VERSION ""

NS_ :

BS_:

BU_: DSAU vHS_M SHVU_RR DPSS AMP ICC RLPSM APSM RWPC RRHV RRPSM CGW_CCU APSS ATS RLHV FPM RDC PSM ASAU

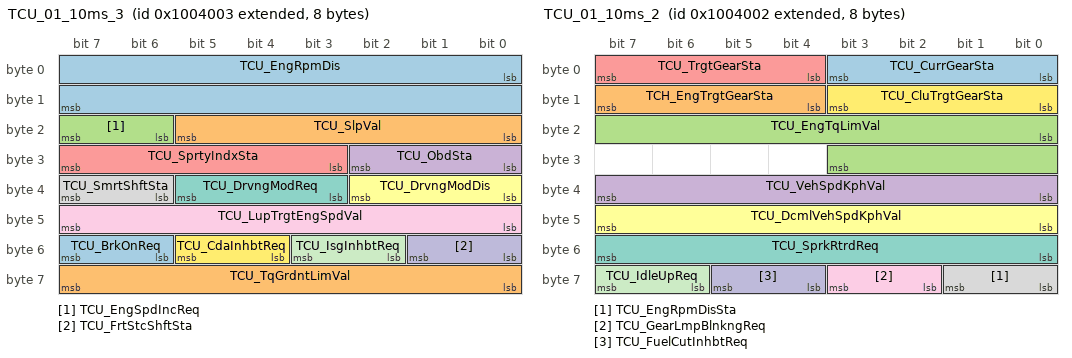
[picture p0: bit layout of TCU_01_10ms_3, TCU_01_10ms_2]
BO_ 2164277251 TCU_01_10ms_3: 8 CGW_CCU
 SG_ TCU_EngRpmDis : 0|16@1+ (0.25,0) [0|0] "rpm"  Vector__XXX
 SG_ TCU_SlpVal : 16|6@1+ (0.5,-16) [0|0] "%"  Vector__XXX
 SG_ TCU_EngSpdIncReq : 22|2@1+ (1,0) [0|0] ""  Vector__XXX
 SG_ TCU_ObdSta : 24|3@1+ (1,0) [0|0] ""  Vector__XXX
 SG_ TCU_SprtyIndxSta : 27|5@1+ (1,0) [0|0] ""  Vector__XXX
 SG_ TCU_DrvngModDis : 32|3@1+ (1,0) [0|0] ""  Vector__XXX
 SG_ TCU_DrvngModReq : 35|3@1+ (1,0) [0|0] ""  Vector__XXX
 SG_ TCU_SmrtShftSta : 38|2@1+ (1,0) [0|0] ""  Vector__XXX
 SG_ TCU_LupTrgtEngSpdVal : 40|8@1+ (10,500) [0|0] "rpm"  Vector__XXX
 SG_ TCU_FrtStcShftSta : 48|2@1+ (1,0) [0|0] ""  Vector__XXX
 SG_ TCU_IsgInhbtReq : 50|2@1+ (1,0) [0|0] ""  Vector__XXX
 SG_ TCU_CdaInhbtReq : 52|2@1+ (1,0) [0|0] ""  Vector__XXX
 SG_ TCU_BrkOnReq : 54|2@1+ (1,0) [0|0] ""  Vector__XXX
 SG_ TCU_TqGrdntLimVal : 56|8@1+ (10,0) [0|0] "Nm/s"  Vector__XXX

BO_ 2164277250 TCU_01_10ms_2: 8 CGW_CCU
 SG_ TCU_CurrGearSta : 0|4@1+ (1,0) [0|0] ""  AMP
 SG_ TCH_EngTrgtGearSta : 12|4@1+ (1,0) [0|0] ""  Vector__XXX
 SG_ TCU_EngTqLimVal : 16|12@1- (1,0) [0|0] "Nm"  Vector__XXX
 SG_ TCU_VehSpdKphVal : 32|8@1+ (1,0) [0|0] "km/h"  Vector__XXX
 SG_ TCU_TrgtGearSta : 4|4@1+ (1,0) [0|0] ""  AMP
 SG_ TCU_DcmlVehSpdKphVal : 40|8@1+ (0.0078125,0) [0|0] "km/h"  Vector__XXX
 SG_ TCU_SprkRtrdReq : 48|8@1+ (0.375,-23.625) [0|0] "˚"  Vector__XXX
 SG_ TCU_EngRpmDisSta : 56|2@1+ (1,0) [0|0] ""  Vector__XXX
 SG_ TCU_GearLmpBlnkngReq : 58|2@1+ (1,0) [0|0] ""  Vector__XXX
 SG_ TCU_FuelCutInhbtReq : 60|2@1+ (1,0) [0|0] ""  Vector__XXX
 SG_ TCU_IdleUpReq : 62|2@1+ (1,0) [0|0] ""  Vector__XXX
 SG_ TCU_CluTrgtGearSta : 8|4@1+ (1,0) [0|0] ""  Vector__XXX

BO_ 799 SBCM_DRV_01_200ms: 8 CGW_CCU
 SG_ SBCM_DRV_Crc1Val : 0|8@1+ (1,0) [0|0] ""  Vector__XXX
 SG_ DRV_CrashUnlockCmd : 10|1@1+ (1,0) [0|0] ""  Vector__XXX
 SG_ C_ApprOpenStatus : 11|1@1+ (1,0) [0|0] ""  Vector__XXX
 SG_ SBCM_DRV_AlvCnt1Val : 12|4@1+ (1,0) [0|0] ""  Vector__XXX
 SG_ Warn_DrvDrSwSta_SBCM : 20|2@1+ (1,0) [0|0] ""  RWPC,PSM,AMP,ATS,ICC
 SG_ DoorLock_DrvDrUnLkSta_SBCM : 22|2@1+ (1,0) [0|0] ""  ATS
 SG_ DRV_SEAWarn_LH : 24|2@1+ (1,0) [0|0] ""  AMP
 SG_ DRV_SEAWarn_RH : 26|2@1+ (1,0) [0|0] ""  AMP
 SG_ DRV_SEWWarn_LH : 28|2@1+ (1,0) [0|0] ""  AMP
 SG_ DRV_SEWWarn_RH : 30|2@1+ (1,0) [0|0] ""  AMP
 SG_ DRV_MRActivationAlarm : 32|2@1+ (1,0) [0|0] ""  Vector__XXX
 SG_ DRV_ReleaseWarn : 34|2@1+ (1,0) [0|0] ""  Vector__XXX
 SG_ Latch_TypeOption_DRV : 36|2@1+ (1,0) [0|0] ""  Vector__XXX
 SG_ DRV_SWFailAlarm : 38|2@1+ (1,0) [0|0] ""  Vector__XXX
 SG_ USM_PwrDRCloseByRKELockSta : 44|2@1+ (1,0) [0|0] ""  Vector__XXX
 SG_ USM_PwrDRCloseByRKELockOpt : 46|2@1+ (1,0) [0|0] ""  Vector__XXX
 SG_ USM_PwrDRCloseByBrakeSta : 48|2@1+ (1,0) [0|0] ""  Vector__XXX
 SG_ USM_PwrDRCloseByBrakeOpt : 50|2@1+ (1,0) [0|0] ""  Vector__XXX
 SG_ USM_PwrDRBuzzerSta : 52|2@1+ (1,0) [0|0] ""  Vector__XXX
 SG_ USM_PwrDRBuzzerOpt : 54|2@1+ (1,0) [0|0] ""  Vector__XXX
 SG_ PDS_TypeOption_DRV : 56|2@1+ (1,0) [0|0] ""  Vector__XXX
 SG_ C_DrvDoorApproachOpen : 58|2@1+ (1,0) [0|0] ""  Vector__XXX
 SG_ C_DrvDoorApproachClose : 60|2@1+ (1,0) [0|0] ""  Vector__XXX
 SG_ DoorLock_PDSLkSwSta_DRV : 62|2@1+ (1,0) [0|0] ""  AMP
 SG_ DRVDoorPushAlarm : 8|2@1+ (1,0) [0|0] ""  Vector__XXX

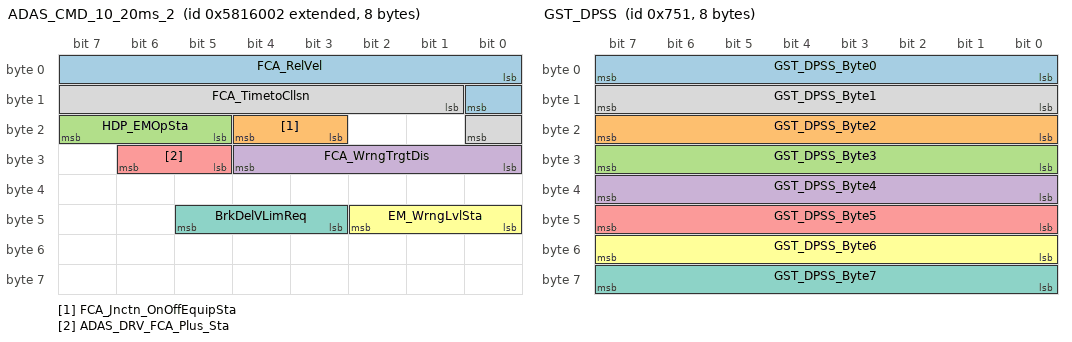
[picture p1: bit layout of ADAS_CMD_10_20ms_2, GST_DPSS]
BO_ 2239848450 ADAS_CMD_10_20ms_2: 8 CGW_CCU
 SG_ FCA_RelVel : 0|9@1+ (0.1,-25.5) [0|0] "m/s"  Vector__XXX
 SG_ FCA_Jnctn_OnOffEquipSta : 19|2@1+ (1,0) [0|0] ""  Vector__XXX
 SG_ HDP_EMOpSta : 21|3@1+ (1,0) [0|0] ""  Vector__XXX
 SG_ FCA_WrngTrgtDis : 24|5@1+ (1,0) [0|0] ""  Vector__XXX
 SG_ ADAS_DRV_FCA_Plus_Sta : 29|2@1+ (1,0) [0|0] ""  Vector__XXX
 SG_ EM_WrngLvlSta : 40|3@1+ (1,0) [0|0] ""  Vector__XXX
 SG_ BrkDelVLimReq : 43|3@1+ (1,0) [0|0] ""  Vector__XXX
 SG_ FCA_TimetoCllsn : 9|8@1+ (10,0) [0|0] "ms"  Vector__XXX

BO_ 1873 GST_DPSS: 8 CGW_CCU
 SG_ GST_DPSS_Byte0 : 0|8@1+ (1,0) [0|0] ""  DPSS,vHS_M
 SG_ GST_DPSS_Byte2 : 16|8@1+ (1,0) [0|0] ""  DPSS,vHS_M
 SG_ GST_DPSS_Byte3 : 24|8@1+ (1,0) [0|0] ""  DPSS,vHS_M
 SG_ GST_DPSS_Byte4 : 32|8@1+ (1,0) [0|0] ""  DPSS,vHS_M
 SG_ GST_DPSS_Byte5 : 40|8@1+ (1,0) [0|0] ""  DPSS,vHS_M
 SG_ GST_DPSS_Byte6 : 48|8@1+ (1,0) [0|0] ""  DPSS,vHS_M
 SG_ GST_DPSS_Byte7 : 56|8@1+ (1,0) [0|0] ""  DPSS,vHS_M
 SG_ GST_DPSS_Byte1 : 8|8@1+ (1,0) [0|0] ""  DPSS,vHS_M

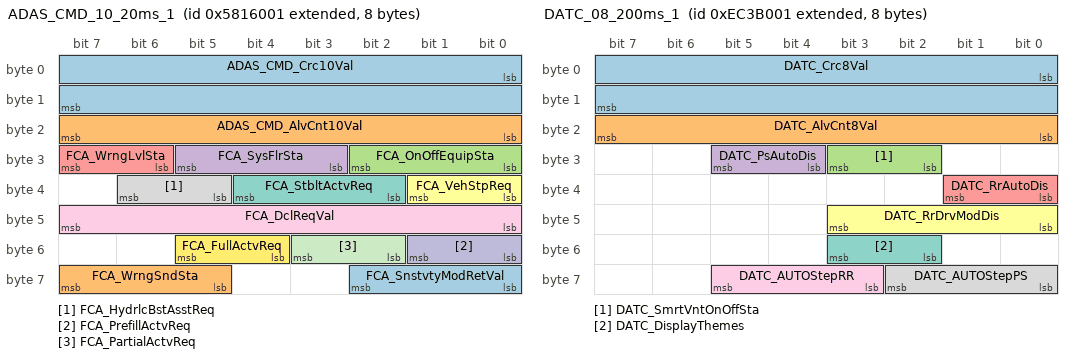
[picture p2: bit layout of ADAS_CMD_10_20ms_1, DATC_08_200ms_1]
BO_ 2239848449 ADAS_CMD_10_20ms_1: 8 CGW_CCU
 SG_ ADAS_CMD_Crc10Val : 0|16@1+ (1,0) [0|0] ""  Vector__XXX
 SG_ ADAS_CMD_AlvCnt10Val : 16|8@1+ (1,0) [0|0] ""  Vector__XXX
 SG_ FCA_OnOffEquipSta : 24|3@1+ (1,0) [0|0] ""  Vector__XXX
 SG_ FCA_SysFlrSta : 27|3@1+ (1,0) [0|0] ""  Vector__XXX
 SG_ FCA_WrngLvlSta : 30|2@1+ (1,0) [0|0] ""  APSM,RLPSM,RRPSM
 SG_ FCA_VehStpReq : 32|2@1+ (1,0) [0|0] ""  Vector__XXX
 SG_ FCA_StbltActvReq : 34|3@1+ (1,0) [0|0] ""  Vector__XXX
 SG_ FCA_HydrlcBstAsstReq : 37|2@1+ (1,0) [0|0] ""  Vector__XXX
 SG_ FCA_DclReqVal : 40|8@1+ (0.01,0) [0|0] "g"  Vector__XXX
 SG_ FCA_PrefillActvReq : 48|2@1+ (1,0) [0|0] ""  Vector__XXX
 SG_ FCA_PartialActvReq : 50|2@1+ (1,0) [0|0] ""  Vector__XXX
 SG_ FCA_FullActvReq : 52|2@1+ (1,0) [0|0] ""  APSM,RLPSM,RRPSM
 SG_ FCA_SnstvtyModRetVal : 56|3@1+ (1,0) [0|0] ""  Vector__XXX
 SG_ FCA_WrngSndSta : 61|3@1+ (1,0) [0|0] ""  AMP

BO_ 2458166529 HU_APSU_PE_00_1: 8 CGW_CCU
 SG_ C_RLUnFldSw_HU : 0|2@1+ (1,0) [0|0] ""  Vector__XXX
 SG_ C_RLTiltUpSw_HU : 10|2@1+ (1,0) [0|0] ""  RLPSM
 SG_ C_RRTiltDownSw_HU : 12|2@1+ (1,0) [0|0] ""  RRPSM
 SG_ C_RRTiltUpSw_HU : 14|2@1+ (1,0) [0|0] ""  RRPSM
 SG_ C_RLRclBwdSw_HU : 16|2@1+ (1,0) [0|0] ""  RLPSM
 SG_ C_RLRclFwdSw_HU : 18|2@1+ (1,0) [0|0] ""  RLPSM
 SG_ C_RLFldSw_HU : 2|2@1+ (1,0) [0|0] ""  Vector__XXX
 SG_ C_RRRclBwdSw_HU : 20|2@1+ (1,0) [0|0] ""  RRPSM
 SG_ C_RRRclFwdSw_HU : 22|2@1+ (1,0) [0|0] ""  RRPSM
 SG_ C_TLHrestFldSw_HU : 24|2@1+ (1,0) [0|0] ""  Vector__XXX
 SG_ C_TRHrestFldSw_HU : 26|2@1+ (1,0) [0|0] ""  Vector__XXX
 SG_ C_RLRlxSW_HU : 28|2@1+ (1,0) [0|0] ""  RLPSM
 SG_ C_RRRlxSW_HU : 30|2@1+ (1,0) [0|0] ""  RRPSM
 SG_ C_RRUnWalkInSw_HU : 32|2@1+ (1,0) [0|0] ""  Vector__XXX
 SG_ C_RRWalkInSw_HU : 34|2@1+ (1,0) [0|0] ""  Vector__XXX
 SG_ C_TLFldSw_HU : 36|2@1+ (1,0) [0|0] ""  Vector__XXX
 SG_ C_TRFldSw_HU : 38|2@1+ (1,0) [0|0] ""  Vector__XXX
 SG_ C_RRUnFldSw_HU : 4|2@1+ (1,0) [0|0] ""  Vector__XXX
 SG_ C_RLUnWalkInSw_HU : 44|2@1+ (1,0) [0|0] ""  Vector__XXX
 SG_ C_RLWalkInSw_HU : 46|2@1+ (1,0) [0|0] ""  Vector__XXX
 SG_ C_TRRclBwdSw_HU : 48|2@1+ (1,0) [0|0] ""  Vector__XXX
 SG_ C_TRRclFwdSw_HU : 50|2@1+ (1,0) [0|0] ""  Vector__XXX
 SG_ C_RRFldSw_HU : 6|2@1+ (1,0) [0|0] ""  Vector__XXX
 SG_ C_TLRclBwdSw_HU : 60|2@1+ (1,0) [0|0] ""  Vector__XXX
 SG_ C_TLRclFwdSw_HU : 62|2@1+ (1,0) [0|0] ""  Vector__XXX
 SG_ C_RLTiltDownSw_HU : 8|2@1+ (1,0) [0|0] ""  RLPSM

BO_ 319 FPM_01_00ms: 8 FPM
 SG_ FPM_Random : 16|48@1+ (1,0) [0|0] ""  CGW_CCU

BO_ 2395189249 DATC_08_200ms_1: 8 CGW_CCU
 SG_ DATC_Crc8Val : 0|16@1+ (1,0) [0|0] ""  Vector__XXX
 SG_ DATC_AlvCnt8Val : 16|8@1+ (1,0) [0|0] ""  Vector__XXX
 SG_ DATC_SmrtVntOnOffSta : 26|2@1+ (1,0) [0|0] ""  Vector__XXX
 SG_ DATC_PsAutoDis : 28|2@1+ (1,0) [0|0] ""  ATS
 SG_ DATC_RrAutoDis : 32|2@1+ (1,0) [0|0] ""  ATS
 SG_ DATC_RrDrvModDis : 40|4@1+ (1,0) [0|0] ""  ATS
 SG_ DATC_DisplayThemes : 50|2@1+ (1,0) [0|0] ""  Vector__XXX
 SG_ DATC_AUTOStepPS : 56|3@1+ (1,0) [0|0] ""  Vector__XXX
 SG_ DATC_AUTOStepRR : 59|3@1+ (1,0) [0|0] ""  Vector__XXX

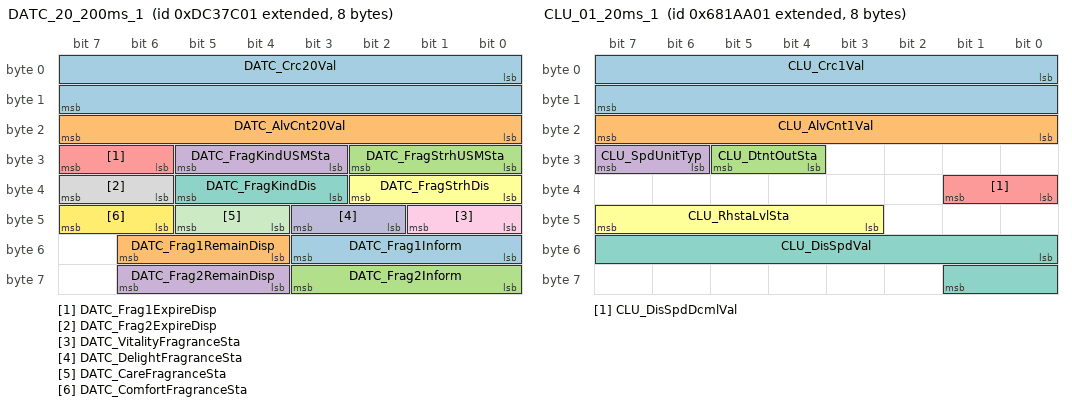
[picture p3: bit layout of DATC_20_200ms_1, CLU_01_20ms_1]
BO_ 2378398721 DATC_20_200ms_1: 8 CGW_CCU
 SG_ DATC_Crc20Val : 0|16@1+ (1,0) [0|0] ""  Vector__XXX
 SG_ DATC_AlvCnt20Val : 16|8@1+ (1,0) [0|0] ""  Vector__XXX
 SG_ DATC_FragStrhUSMSta : 24|3@1+ (1,0) [0|0] ""  ATS
 SG_ DATC_FragKindUSMSta : 27|3@1+ (1,0) [0|0] ""  ATS
 SG_ DATC_Frag1ExpireDisp : 30|2@1+ (1,0) [0|0] ""  ATS
 SG_ DATC_FragStrhDis : 32|3@1+ (1,0) [0|0] ""  ATS
 SG_ DATC_FragKindDis : 35|3@1+ (1,0) [0|0] ""  ATS
 SG_ DATC_Frag2ExpireDisp : 38|2@1+ (1,0) [0|0] ""  ATS
 SG_ DATC_VitalityFragranceSta : 40|2@1+ (1,0) [0|0] ""  Vector__XXX
 SG_ DATC_DelightFragranceSta : 42|2@1+ (1,0) [0|0] ""  Vector__XXX
 SG_ DATC_CareFragranceSta : 44|2@1+ (1,0) [0|0] ""  Vector__XXX
 SG_ DATC_ComfortFragranceSta : 46|2@1+ (1,0) [0|0] ""  Vector__XXX
 SG_ DATC_Frag1Inform : 48|4@1+ (1,0) [0|0] ""  ATS
 SG_ DATC_Frag1RemainDisp : 52|3@1+ (1,0) [0|0] ""  ATS
 SG_ DATC_Frag2Inform : 56|4@1+ (1,0) [0|0] ""  ATS
 SG_ DATC_Frag2RemainDisp : 60|3@1+ (1,0) [0|0] ""  ATS

BO_ 2466562561 HU_USM_E_08_1: 8 CGW_CCU
 SG_ C_RH_Unfolding_SW : 0|2@1+ (1,0) [0|0] ""  Vector__XXX
 SG_ C_PSMHeightNValueSet : 10|3@1+ (1,0) [0|0] ""  Vector__XXX
 SG_ C_AVN_PTGHeightNValueSet : 13|3@1+ (1,0) [0|0] ""  Vector__XXX
 SG_ CF_AVN_SCCMLReset : 16|2@1+ (1,0) [0|0] ""  Vector__XXX
 SG_ C_TgltAwayCloseNValue : 18|2@1+ (1,0) [0|0] ""  Vector__XXX
 SG_ C_RH_Folding_SW : 2|2@1+ (1,0) [0|0] ""  Vector__XXX
 SG_ C_HAnBNValueSet : 20|2@1+ (1,0) [0|0] ""  Vector__XXX
 SG_ CF_AVN_RrSeatRemindNValueSet : 22|2@1+ (1,0) [0|0] ""  Vector__XXX
 SG_ CF_AVN_DSWNValueSet : 24|2@1+ (1,0) [0|0] ""  DSAU,ICC
 SG_ CF_AVN_RRPSU_RLNValueSet : 26|3@1+ (1,0) [0|0] ""  RLPSM
 SG_ CF_AVN_APSUNValueSet : 29|3@1+ (1,0) [0|0] ""  APSM,APSS,ASAU
 SG_ CF_AVN_NCC_CameraNValueSet : 32|3@1+ (1,0) [0|0] ""  Vector__XXX
 SG_ CF_AVN_FCAJnctnNValueSet : 35|2@1+ (1,0) [0|0] ""  Vector__XXX
 SG_ CF_AVN_RRPSU_RRNValueSet : 37|3@1+ (1,0) [0|0] ""  RRPSM
 SG_ C_LH_Unfolding_SW : 4|2@1+ (1,0) [0|0] ""  Vector__XXX
 SG_ CF_AVN_HtBlcAstNValueSet : 40|4@1+ (1,0) [0|0] ""  PSM,APSM
 SG_ CF_AVN_HtBlcDrvNValueSet : 44|4@1+ (1,0) [0|0] ""  PSM,APSM
 SG_ CF_AVN_SCCModeNValueSet : 48|2@1+ (1,0) [0|0] ""  Vector__XXX
 SG_ CF_AVN_SCCMLChar1Set : 50|3@1+ (1,0) [0|0] ""  Vector__XXX
 SG_ CF_AVN_UIPNValueSet : 54|2@1+ (1,0) [0|0] ""  Vector__XXX
 SG_ CF_AVN_SCCMLChar2Set : 56|3@1+ (1,0) [0|0] ""  Vector__XXX
 SG_ CF_AVN_SCCMLChar3Set : 59|3@1+ (1,0) [0|0] ""  Vector__XXX
 SG_ C_LH_Folding_SW : 6|2@1+ (1,0) [0|0] ""  Vector__XXX
 SG_ CF_AVN_NmodeFCAoffNValue : 62|2@1+ (1,0) [0|0] ""  Vector__XXX
 SG_ CF_AVN_HDALCFuncNValueSet : 8|2@1+ (1,0) [0|0] ""  Vector__XXX

BO_ 2256644609 CLU_01_20ms_1: 8 CGW_CCU
 SG_ CLU_Crc1Val : 0|16@1+ (1,0) [0|0] ""  PSM,RRPSM,SHVU_RR,DPSS,ATS
 SG_ CLU_AlvCnt1Val : 16|8@1+ (1,0) [0|0] ""  PSM,RRPSM,SHVU_RR,DPSS,ATS
 SG_ CLU_DtntOutSta : 28|2@1+ (1,0) [0|0] ""  RLPSM,DPSS,FPM,ATS,DSAU,ASAU
 SG_ CLU_SpdUnitTyp : 30|2@1+ (1,0) [0|0] ""  PSM,ICC
 SG_ CLU_DisSpdDcmlVal : 32|2@1+ (0.125,0) [0|0] ""  PSM
 SG_ CLU_RhstaLvlSta : 43|5@1+ (1,0) [0|0] ""  PSM,RLPSM,DPSS,FPM,ATS,DSAU,ASAU
 SG_ CLU_DisSpdVal : 48|10@1+ (0.5,0) [0|0] "km/h or MPH"  PSM,ICC

BO_ 2315419905 HU_FPM_E_01_1: 8 CGW_CCU
 SG_ AVN_Encrypted_Result1 : 0|64@1+ (1,0) [0|0] ""  FPM

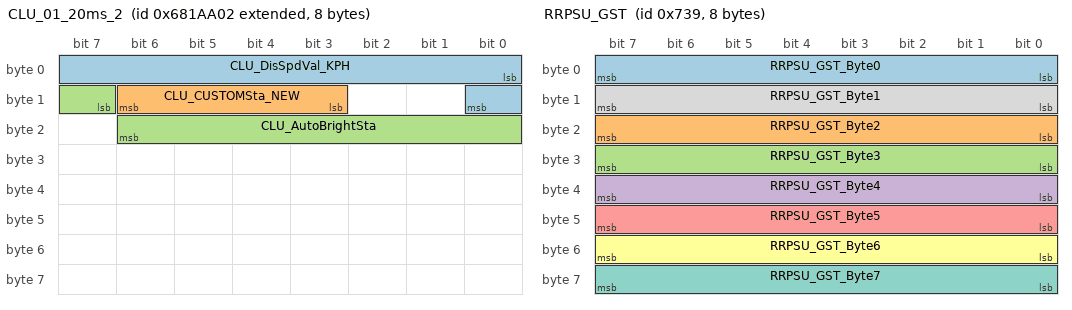
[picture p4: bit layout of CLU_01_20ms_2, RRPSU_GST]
BO_ 2256644610 CLU_01_20ms_2: 8 CGW_CCU
 SG_ CLU_DisSpdVal_KPH : 0|9@1+ (1,0) [0|0] "km/h"  RWPC,PSM,APSM,RLPSM,RRPSM,RLHV,RRHV,SHVU_RR,DPSS,ATS,DSAU,ASAU
 SG_ CLU_CUSTOMSta_NEW : 11|4@1+ (1,0) [0|0] ""  Vector__XXX
 SG_ CLU_AutoBrightSta : 15|8@1+ (1,0) [0|0] ""  Vector__XXX

BO_ 1849 RRPSU_GST: 8 RRPSM
 SG_ RRPSU_GST_Byte0 : 0|8@1+ (1,0) [0|0] ""  CGW_CCU
 SG_ RRPSU_GST_Byte2 : 16|8@1+ (1,0) [0|0] ""  CGW_CCU
 SG_ RRPSU_GST_Byte3 : 24|8@1+ (1,0) [0|0] ""  CGW_CCU
 SG_ RRPSU_GST_Byte4 : 32|8@1+ (1,0) [0|0] ""  CGW_CCU
 SG_ RRPSU_GST_Byte5 : 40|8@1+ (1,0) [0|0] ""  CGW_CCU
 SG_ RRPSU_GST_Byte6 : 48|8@1+ (1,0) [0|0] ""  CGW_CCU
 SG_ RRPSU_GST_Byte7 : 56|8@1+ (1,0) [0|0] ""  CGW_CCU
 SG_ RRPSU_GST_Byte1 : 8|8@1+ (1,0) [0|0] ""  CGW_CCU

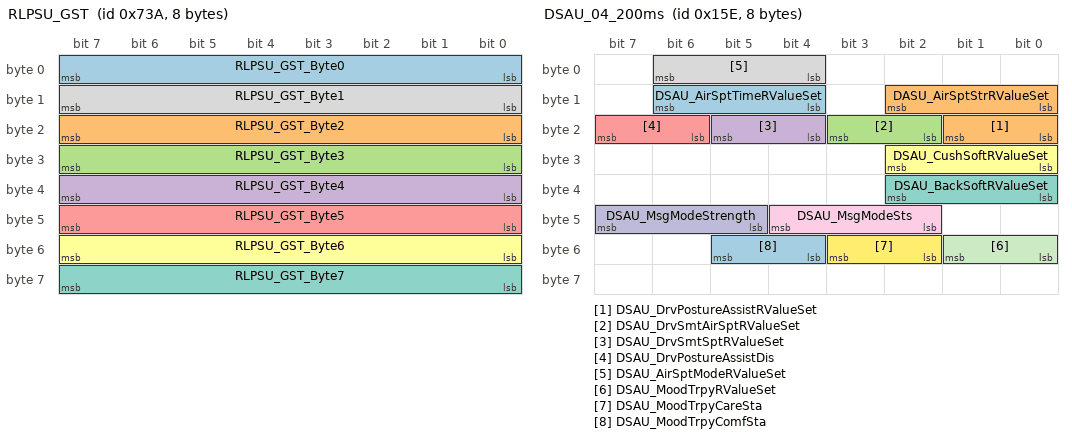
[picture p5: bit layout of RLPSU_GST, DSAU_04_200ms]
BO_ 1850 RLPSU_GST: 8 RLPSM
 SG_ RLPSU_GST_Byte0 : 0|8@1+ (1,0) [0|0] ""  CGW_CCU
 SG_ RLPSU_GST_Byte2 : 16|8@1+ (1,0) [0|0] ""  CGW_CCU
 SG_ RLPSU_GST_Byte3 : 24|8@1+ (1,0) [0|0] ""  CGW_CCU
 SG_ RLPSU_GST_Byte4 : 32|8@1+ (1,0) [0|0] ""  CGW_CCU
 SG_ RLPSU_GST_Byte5 : 40|8@1+ (1,0) [0|0] ""  CGW_CCU
 SG_ RLPSU_GST_Byte6 : 48|8@1+ (1,0) [0|0] ""  CGW_CCU
 SG_ RLPSU_GST_Byte7 : 56|8@1+ (1,0) [0|0] ""  CGW_CCU
 SG_ RLPSU_GST_Byte1 : 8|8@1+ (1,0) [0|0] ""  CGW_CCU

BO_ 351 FPM_03_00ms: 8 FPM
 SG_ FPM_Encrypted_Result2 : 0|64@1+ (1,0) [0|0] ""  CGW_CCU

BO_ 350 DSAU_04_200ms: 8 DSAU
 SG_ DSAU_AirSptTimeRValueSet : 12|3@1+ (1,0) [0|0] ""  CGW_CCU
 SG_ DSAU_DrvPostureAssistRValueSet : 16|2@1+ (1,0) [0|0] ""  CGW_CCU
 SG_ DSAU_DrvSmtAirSptRValueSet : 18|2@1+ (1,0) [0|0] ""  CGW_CCU
 SG_ DSAU_DrvSmtSptRValueSet : 20|2@1+ (1,0) [0|0] ""  CGW_CCU
 SG_ DSAU_DrvPostureAssistDis : 22|2@1+ (1,0) [0|0] ""  CGW_CCU
 SG_ DSAU_CushSoftRValueSet : 24|3@1+ (1,0) [0|0] ""  CGW_CCU
 SG_ DSAU_BackSoftRValueSet : 32|3@1+ (1,0) [0|0] ""  CGW_CCU
 SG_ DSAU_AirSptModeRValueSet : 4|3@1+ (1,0) [0|0] ""  CGW_CCU
 SG_ DSAU_MsgModeSts : 42|3@1+ (1,0) [0|0] ""  CGW_CCU
 SG_ DSAU_MsgModeStrength : 45|3@1+ (1,0) [0|0] ""  CGW_CCU
 SG_ DSAU_MoodTrpyRValueSet : 48|2@1+ (1,0) [0|0] ""  CGW_CCU
 SG_ DSAU_MoodTrpyCareSta : 50|2@1+ (1,0) [0|0] ""  CGW_CCU
 SG_ DSAU_MoodTrpyComfSta : 52|2@1+ (1,0) [0|0] ""  CGW_CCU
 SG_ DASU_AirSptStrRValueSet : 8|3@1+ (1,0) [0|0] ""  CGW_CCU

BO_ 349 DSAU_03_200ms: 8 DSAU
 SG_ DSAU_CushInfDis : 0|2@1+ (1,0) [0|0] ""  DPSS,CGW_CCU
 SG_ DSAU_CushDefDis : 2|2@1+ (1,0) [0|0] ""  DPSS,CGW_CCU

BO_ 348 DSAU_02_200ms: 8 DSAU
 SG_ DSAU_BolsterInfDis : 0|2@1+ (1,0) [0|0] ""  DPSS,CGW_CCU
 SG_ DSAU_BolsterDefDis : 2|2@1+ (1,0) [0|0] ""  DPSS,CGW_CCU

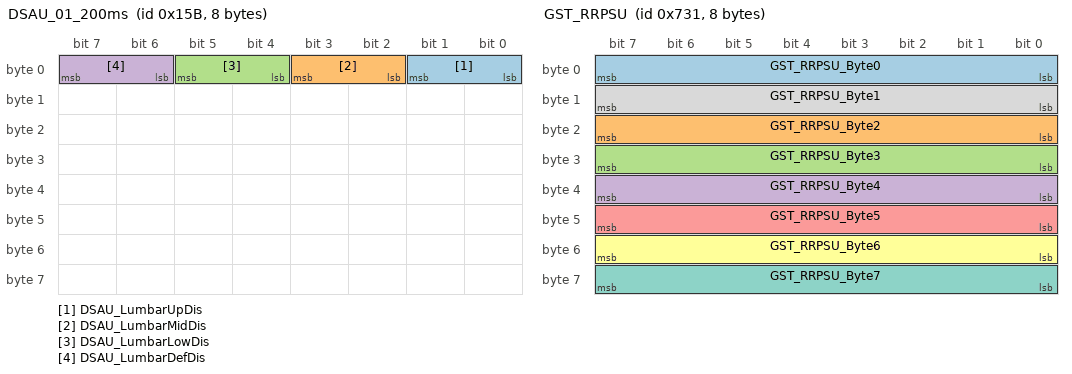
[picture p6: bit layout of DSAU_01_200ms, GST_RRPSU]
BO_ 347 DSAU_01_200ms: 8 DSAU
 SG_ DSAU_LumbarUpDis : 0|2@1+ (1,0) [0|0] ""  DPSS,CGW_CCU
 SG_ DSAU_LumbarMidDis : 2|2@1+ (1,0) [0|0] ""  DPSS,CGW_CCU
 SG_ DSAU_LumbarLowDis : 4|2@1+ (1,0) [0|0] ""  DPSS,CGW_CCU
 SG_ DSAU_LumbarDefDis : 6|2@1+ (1,0) [0|0] ""  DPSS,CGW_CCU

BO_ 1841 GST_RRPSU: 8 CGW_CCU
 SG_ GST_RRPSU_Byte0 : 0|8@1+ (1,0) [0|0] ""  RRPSM,vHS_M
 SG_ GST_RRPSU_Byte2 : 16|8@1+ (1,0) [0|0] ""  RRPSM,vHS_M
 SG_ GST_RRPSU_Byte3 : 24|8@1+ (1,0) [0|0] ""  RRPSM,vHS_M
 SG_ GST_RRPSU_Byte4 : 32|8@1+ (1,0) [0|0] ""  RRPSM,vHS_M
 SG_ GST_RRPSU_Byte5 : 40|8@1+ (1,0) [0|0] ""  RRPSM,vHS_M
 SG_ GST_RRPSU_Byte6 : 48|8@1+ (1,0) [0|0] ""  RRPSM,vHS_M
 SG_ GST_RRPSU_Byte7 : 56|8@1+ (1,0) [0|0] ""  RRPSM,vHS_M
 SG_ GST_RRPSU_Byte1 : 8|8@1+ (1,0) [0|0] ""  RRPSM,vHS_M

BO_ 346 DPSS_04_200ms: 8 DPSS
 SG_ DPSS_AstStCrc1Val : 0|8@1+ (1,0) [0|0] ""  APSM
 SG_ DPSS_AstStAlvCnt1Val : 12|4@1+ (1,0) [0|0] ""  APSM
 SG_ DPSS_AstSldFwdMvBtn : 16|2@1+ (1,0) [0|0] ""  APSM,RRPSM
 SG_ DPSS_AstStSldBwdMvBtn : 18|2@1+ (1,0) [0|0] ""  APSM,RRPSM
 SG_ DPSS_AstStRclFwdMvBtn : 20|2@1+ (1,0) [0|0] ""  APSM,RRPSM
 SG_ DPSS_AstStRclBwdMvBtn : 22|2@1+ (1,0) [0|0] ""  APSM,RRPSM
 SG_ DPSS_AstStHgtUpMvBtn : 24|2@1+ (1,0) [0|0] ""  APSM,RRPSM
 SG_ DPSS_AstStHgtDnMvBtn : 26|2@1+ (1,0) [0|0] ""  APSM,RRPSM
 SG_ DPSS_AstStTltUpMvBtn : 28|2@1+ (1,0) [0|0] ""  APSM,RRPSM
 SG_ DPSS_AstStTltDnMvBtn : 30|2@1+ (1,0) [0|0] ""  APSM,RRPSM
 SG_ DPSS_AstStHRestUpMvBtn : 32|2@1+ (1,0) [0|0] ""  APSM,RRPSM
 SG_ DPSS_AstStHRestDnMvBtn : 34|2@1+ (1,0) [0|0] ""  APSM,RRPSM
 SG_ DPSS_AstStHRestFwdMvBtn : 36|2@1+ (1,0) [0|0] ""  APSM,RRPSM
 SG_ DPSS_AstStHRestBwdMvBtn : 38|2@1+ (1,0) [0|0] ""  APSM,RRPSM
 SG_ DPSS_AstStExtFwdMvBtn : 40|2@1+ (1,0) [0|0] ""  APSM
 SG_ DPSS_AstStExtBwdMvBtn : 42|2@1+ (1,0) [0|0] ""  APSM
 SG_ DPSS_WalkInSwitchSts : 44|2@1+ (1,0) [0|0] ""  Vector__XXX

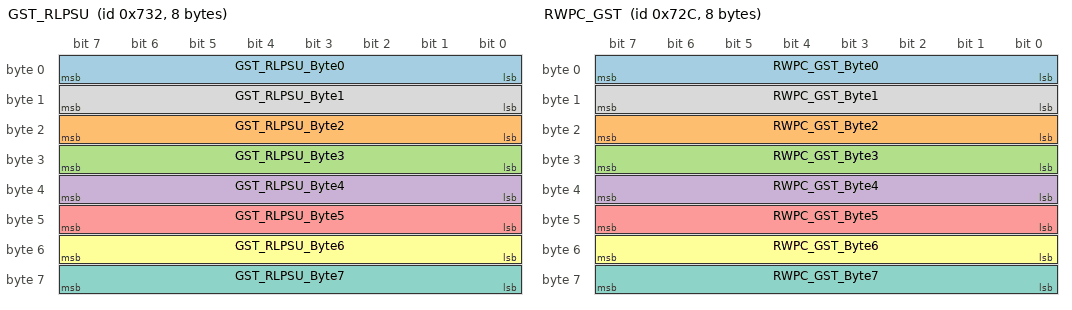
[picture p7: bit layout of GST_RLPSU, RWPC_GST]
BO_ 1842 GST_RLPSU: 8 CGW_CCU
 SG_ GST_RLPSU_Byte0 : 0|8@1+ (1,0) [0|0] ""  RLPSM,vHS_M
 SG_ GST_RLPSU_Byte2 : 16|8@1+ (1,0) [0|0] ""  RLPSM,vHS_M
 SG_ GST_RLPSU_Byte3 : 24|8@1+ (1,0) [0|0] ""  RLPSM,vHS_M
 SG_ GST_RLPSU_Byte4 : 32|8@1+ (1,0) [0|0] ""  RLPSM,vHS_M
 SG_ GST_RLPSU_Byte5 : 40|8@1+ (1,0) [0|0] ""  RLPSM,vHS_M
 SG_ GST_RLPSU_Byte6 : 48|8@1+ (1,0) [0|0] ""  RLPSM,vHS_M
 SG_ GST_RLPSU_Byte7 : 56|8@1+ (1,0) [0|0] ""  RLPSM,vHS_M
 SG_ GST_RLPSU_Byte1 : 8|8@1+ (1,0) [0|0] ""  RLPSM,vHS_M

BO_ 1836 RWPC_GST: 8 RWPC
 SG_ RWPC_GST_Byte0 : 0|8@1+ (1,0) [0|0] ""  CGW_CCU
 SG_ RWPC_GST_Byte2 : 16|8@1+ (1,0) [0|0] ""  CGW_CCU
 SG_ RWPC_GST_Byte3 : 24|8@1+ (1,0) [0|0] ""  CGW_CCU
 SG_ RWPC_GST_Byte4 : 32|8@1+ (1,0) [0|0] ""  CGW_CCU
 SG_ RWPC_GST_Byte5 : 40|8@1+ (1,0) [0|0] ""  CGW_CCU
 SG_ RWPC_GST_Byte6 : 48|8@1+ (1,0) [0|0] ""  CGW_CCU
 SG_ RWPC_GST_Byte7 : 56|8@1+ (1,0) [0|0] ""  CGW_CCU
 SG_ RWPC_GST_Byte1 : 8|8@1+ (1,0) [0|0] ""  CGW_CCU

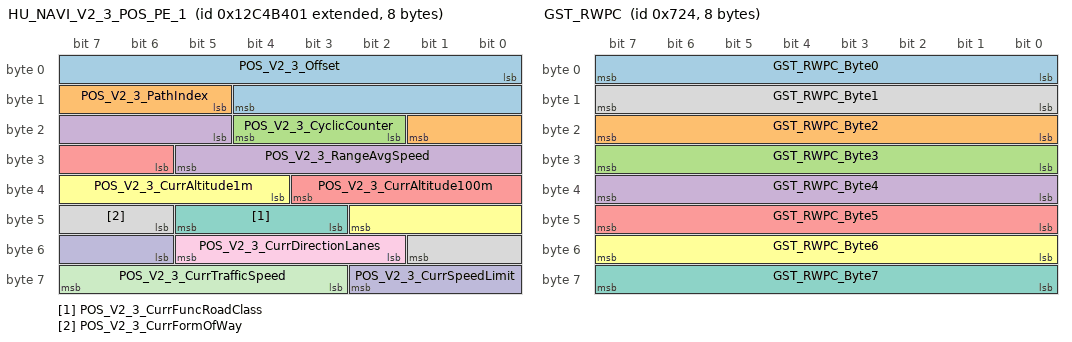
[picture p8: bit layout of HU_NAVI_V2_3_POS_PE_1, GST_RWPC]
BO_ 2462364673 HU_NAVI_V2_3_POS_PE_1: 8 CGW_CCU
 SG_ POS_V2_3_Offset : 0|13@1+ (1,0) [0|0] "m"  DSAU
 SG_ POS_V2_3_PathIndex : 13|5@1+ (1,0) [0|0] ""  Vector__XXX
 SG_ POS_V2_3_CyclicCounter : 18|3@1+ (1,0) [0|0] ""  DSAU
 SG_ POS_V2_3_RangeAvgSpeed : 21|9@1+ (1,0) [0|0] "km/h"  Vector__XXX
 SG_ POS_V2_3_CurrAltitude100m : 30|6@1+ (1,0) [0|0] "m"  Vector__XXX
 SG_ POS_V2_3_CurrAltitude1m : 36|7@1+ (1,0) [0|0] "m"  Vector__XXX
 SG_ POS_V2_3_CurrFuncRoadClass : 43|3@1+ (1,0) [0|0] ""  DSAU
 SG_ POS_V2_3_CurrFormOfWay : 46|4@1+ (1,0) [0|0] ""  DSAU
 SG_ POS_V2_3_CurrDirectionLanes : 50|4@1+ (1,0) [0|0] ""  Vector__XXX
 SG_ POS_V2_3_CurrSpeedLimit : 54|5@1+ (1,0) [0|0] "km/h or MPH"  Vector__XXX
 SG_ POS_V2_3_CurrTrafficSpeed : 59|5@1+ (1,0) [0|0] "km/h or MPH"  Vector__XXX

BO_ 1828 GST_RWPC: 8 CGW_CCU
 SG_ GST_RWPC_Byte0 : 0|8@1+ (1,0) [0|0] ""  RWPC,vHS_M
 SG_ GST_RWPC_Byte2 : 16|8@1+ (1,0) [0|0] ""  RWPC,vHS_M
 SG_ GST_RWPC_Byte3 : 24|8@1+ (1,0) [0|0] ""  RWPC,vHS_M
 SG_ GST_RWPC_Byte4 : 32|8@1+ (1,0) [0|0] ""  RWPC,vHS_M
 SG_ GST_RWPC_Byte5 : 40|8@1+ (1,0) [0|0] ""  RWPC,vHS_M
 SG_ GST_RWPC_Byte6 : 48|8@1+ (1,0) [0|0] ""  RWPC,vHS_M
 SG_ GST_RWPC_Byte7 : 56|8@1+ (1,0) [0|0] ""  RWPC,vHS_M
 SG_ GST_RWPC_Byte1 : 8|8@1+ (1,0) [0|0] ""  RWPC,vHS_M

BO_ 335 FPM_02_00ms: 8 FPM
 SG_ FPM_Encrypted_Result1 : 0|64@1+ (1,0) [0|0] ""  CGW_CCU

BO_ 2407787009 DVRS_HU_PE_00_1: 8 CGW_CCU
 SG_ DVRS_Rec_Crash : 0|2@1+ (1,0) [0|0] ""  Vector__XXX
 SG_ DVRS_Rec_Normal_Prk : 10|2@1+ (1,0) [0|0] ""  Vector__XXX
 SG_ DVRS_Timelapse : 12|2@1+ (1,0) [0|0] ""  Vector__XXX
 SG_ DVRS_Rec_Manual : 14|2@1+ (1,0) [0|0] ""  Vector__XXX
 SG_ DVRS_Prk_time : 16|8@1+ (1,0) [0|0] "Hour"  Vector__XXX
 SG_ DVRS_Rec_Normal : 2|2@1+ (1,0) [0|0] ""  Vector__XXX
 SG_ DVRS_Prk_Crash_Event_Count : 24|8@1+ (1,0) [0|255] ""  Vector__XXX
 SG_ DVRS_Status : 32|4@1+ (1,0) [0|0] ""  Vector__XXX
 SG_ DVRS_Event_Sound : 36|2@1+ (1,0) [0|0] ""  Vector__XXX
 SG_ DVRS_BeepSound : 38|2@1+ (1,0) [0|0] ""  AMP
 SG_ DVRS_Display : 4|4@1+ (1,0) [0|0] ""  Vector__XXX
 SG_ BLTN_CAM_UpdateSWType : 42|2@1+ (1,0) [0|0] ""  Vector__XXX
 SG_ DVRS_I2CMasterSta : 51|2@1+ (1,0) [0|0] ""  Vector__XXX
 SG_ DVRS_CamSta : 53|3@1+ (1,0) [0|0] ""  Vector__XXX
 SG_ DVRS_RecSet_Normal : 56|2@1+ (1,0) [0|0] ""  Vector__XXX
 SG_ DVRS_RecSet_Crash : 58|2@1+ (1,0) [0|0] ""  Vector__XXX
 SG_ DVRS_RecSet_Normal_Prk : 60|2@1+ (1,0) [0|0] ""  Vector__XXX
 SG_ DVRS_RecSet_Crash_Prk : 62|2@1+ (1,0) [0|0] ""  Vector__XXX
 SG_ DVRS_Rec_Crash_Prk : 8|2@1+ (1,0) [0|0] ""  Vector__XXX

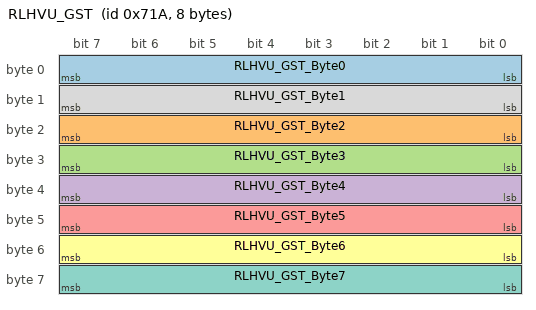
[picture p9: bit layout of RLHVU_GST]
BO_ 1818 RLHVU_GST: 8 RLHV
 SG_ RLHVU_GST_Byte0 : 0|8@1+ (1,0) [0|0] ""  CGW_CCU
 SG_ RLHVU_GST_Byte2 : 16|8@1+ (1,0) [0|0] ""  CGW_CCU
 SG_ RLHVU_GST_Byte3 : 24|8@1+ (1,0) [0|0] ""  CGW_CCU
 SG_ RLHVU_GST_Byte4 : 32|8@1+ (1,0) [0|0] ""  CGW_CCU
 SG_ RLHVU_GST_Byte5 : 40|8@1+ (1,0) [0|0] ""  CGW_CCU
 SG_ RLHVU_GST_Byte6 : 48|8@1+ (1,0) [0|0] ""  CGW_CCU
 SG_ RLHVU_GST_Byte7 : 56|8@1+ (1,0) [0|0] ""  CGW_CCU
 SG_ RLHVU_GST_Byte1 : 8|8@1+ (1,0) [0|0] ""  CGW_CCU

BO_TX_BU_ 1849 : RRPSM,vHS_M;
BO_TX_BU_ 1850 : RLPSM,vHS_M;
BO_TX_BU_ 1836 : RWPC,vHS_M;
BO_TX_BU_ 1818 : RLHV,vHS_M;
CM_ BO_ 2239848449 "[P] Periodic";
CM_ SG_ 2239848449 ADAS_CMD_Crc10Val "ADAS_CMD_CyclicRedundancyCheck10Value ##2G##FCA - FCA11 - CR_FCA_ChkSum";
CM_ SG_ 2239848449 ADAS_CMD_AlvCnt10Val "ADAS_CMD_AliveCounter10Value ##2G##FCA - FCA11 - CR_FCA_Alive";
CM_ SG_ 2239848449 FCA_OnOffEquipSta "FCA_OnOffEquipmentStatus ##2G##FCA - FCA12 - FCA_USM";
CM_ SG_ 2239848449 FCA_SysFlrSta "FCA_SystemFailureStatus ##2G##FCA - FCA11 - FCA_Failinfo";
CM_ SG_ 2239848449 FCA_WrngLvlSta "FCA_WarningLevelStatus ##2G##FCA - FCA11 - CF_VSM_Warn";
CM_ SG_ 2239848449 FCA_VehStpReq "FCA_VehicleStopRequest ##2G##FCA - FCA11 - FCA_StopReq";
CM_ SG_ 2239848449 FCA_StbltActvReq "FCA_SeatBeltActivateRequest ##2G##FCA - FCA11 - CF_VSM_BeltCmd";
CM_ SG_ 2239848449 FCA_HydrlcBstAsstReq "FCA_HydraulicBoostAssistRequest ##2G##FCA - FCA11 - CF_VSM_HBACmd";
CM_ SG_ 2239848449 FCA_DclReqVal "FCA_DecelerationRequestValue ##2G##FCA - FCA11 - CR_VSM_DecCmd";
CM_ SG_ 2239848449 FCA_PrefillActvReq "FCA_PrefillActivateRequest ##2G##FCA - FCA11 - CF_VSM_Prefill";
CM_ SG_ 2239848449 FCA_PartialActvReq "FCA_PartialActivateRequest";
CM_ SG_ 2239848449 FCA_FullActvReq "FCA_FullActivateRequest";
CM_ SG_ 2239848449 FCA_SnstvtyModRetVal "FCA_SensitivityModeReturnValue ##2G##FCA - FCA12 - FCA_DrvSetState";
CM_ SG_ 2239848449 FCA_WrngSndSta "FCA warning sound status";
CM_ BO_ 2239848450 "[P] Periodic";
CM_ SG_ 2239848450 FCA_RelVel "FCA_RelativeVelocity ##2G##FCA - FCA11_FS - FCA_RelativeVelocity";
CM_ SG_ 2239848450 FCA_Jnctn_OnOffEquipSta "FCA_Junction_OnOffEquipStatus";
CM_ SG_ 2239848450 HDP_EMOpSta "HDP EM Operating State";
CM_ SG_ 2239848450 FCA_WrngTrgtDis "FCA_WarningTargetDisplay";
CM_ SG_ 2239848450 ADAS_DRV_FCA_Plus_Sta "전방카메라, 전방레이더 및 전측방 레이더/후측방 레이터 퓨전 트랙을 통해 FCA-Car 타겟 및 자차 좌측/우측 영역 회피 불가능 여부를 판단하여 FCA-Car/Ped/Cyc+ Flag를 출력";
CM_ SG_ 2239848450 EM_WrngLvlSta "EM_WarningLevelStatus";
CM_ SG_ 2239848450 BrkDelVLimReq "Brake Delta V Limit Request";
CM_ SG_ 2239848450 FCA_TimetoCllsn "FCA_TimetoCollision ##2G##FCA - FCA11_FS - FCA_TimetoCollision";
CM_ BO_ 2256644609 "[P] Periodic";
CM_ SG_ 2256644609 CLU_Crc1Val "CLU_CyclicRedundancyCheck1Value";
CM_ SG_ 2256644609 CLU_AlvCnt1Val "CLU_AliveCounter1Value";
CM_ SG_ 2256644609 CLU_DtntOutSta "CLU_DetentOutStatus";
CM_ SG_ 2256644609 CLU_SpdUnitTyp "CLU_SpeedUnitType";
CM_ SG_ 2256644609 CLU_DisSpdDcmlVal "CLU_DisplaySpeedDecimalValue";
CM_ SG_ 2256644609 CLU_RhstaLvlSta "CLU_RheostatLevelStatus";
CM_ SG_ 2256644609 CLU_DisSpdVal "CLU_DisplaySpeedValue";
CM_ BO_ 2256644610 "[P] Periodic";
CM_ SG_ 2256644610 CLU_DisSpdVal_KPH "CLU_DisplaySpeedValue_KPH";
CM_ SG_ 2256644610 CLU_AutoBrightSta "CLU_AutoBrightStatus";
CM_ BO_ 2395189249 "[PE] Periodic and On Event";
CM_ SG_ 2395189249 DATC_Crc8Val "DATC_CyclicRedundancyCheck8Value";
CM_ SG_ 2395189249 DATC_AlvCnt8Val "DATC_AliveCounter8Value";
CM_ SG_ 2395189249 DATC_SmrtVntOnOffSta "DATC_SmartVentilationOnOffStatus";
CM_ SG_ 2395189249 DATC_PsAutoDis "DATC_PassengerAutoDisplay";
CM_ SG_ 2395189249 DATC_RrAutoDis "DATC_RearAutoDisplay";
CM_ SG_ 2395189249 DATC_RrDrvModDis "DATC_RearDriverModeDisplay";
CM_ SG_ 2395189249 DATC_DisplayThemes "DATC_DisplayThemesInformation";
CM_ SG_ 2395189249 DATC_AUTOStepPS "This signal indicates Passenger AUTO step status in case Multi Auto Blower type.";
CM_ SG_ 2395189249 DATC_AUTOStepRR "This signal indicates Rear AUTO step status in case Multi Auto Blower type.";
CM_ BO_ 2378398721 "[PE] Periodic and On Event";
CM_ SG_ 2378398721 DATC_Crc20Val "DATC_CyclicRedundancyCheck20Value";
CM_ SG_ 2378398721 DATC_AlvCnt20Val "DATC_AliveCounter20Value";
CM_ SG_ 2378398721 DATC_FragStrhUSMSta "Fragrance Strength State";
CM_ SG_ 2378398721 DATC_FragKindUSMSta "Fragrance Kind State";
CM_ SG_ 2378398721 DATC_Frag1ExpireDisp "DATC_Fragrance1ExpireDisplay";
CM_ SG_ 2378398721 DATC_FragStrhDis "Fragrance Strength Display";
CM_ SG_ 2378398721 DATC_FragKindDis "Fragrance Kind Display";
CM_ SG_ 2378398721 DATC_Frag2ExpireDisp "DATC_Fragrance2ExpireDisplay";
CM_ SG_ 2378398721 DATC_VitalityFragranceSta "DATC_VitalityFragranceState";
CM_ SG_ 2378398721 DATC_DelightFragranceSta "DATC_DelightFragranceState";
CM_ SG_ 2378398721 DATC_CareFragranceSta "DATC_CareFragranceState";
CM_ SG_ 2378398721 DATC_ComfortFragranceSta "DATC_ComfortFragranceState";
CM_ SG_ 2378398721 DATC_Frag1Inform "DATC_Fragrance1Information";
CM_ SG_ 2378398721 DATC_Frag1RemainDisp "DATC_Fragrance1RemainDisplay";
CM_ SG_ 2378398721 DATC_Frag2Inform "DATC_Fragrance2Information";
CM_ SG_ 2378398721 DATC_Frag2RemainDisp "DATC_Fragrance2RemainDisplay";
CM_ BO_ 346 "[PE] Periodic and On Event";
CM_ SG_ 346 DPSS_AstStCrc1Val "DPSS_AstStCyclicRedundancyCheck1Value";
CM_ SG_ 346 DPSS_AstStAlvCnt1Val "DPSS_AstStAliveCounter1Value";
CM_ SG_ 346 DPSS_AstSldFwdMvBtn "DPSS_AstStSlideForwardMoveButton";
CM_ SG_ 346 DPSS_AstStSldBwdMvBtn "DPSS_AstStSlideBackwardMoveButton";
CM_ SG_ 346 DPSS_AstStRclFwdMvBtn "DPSS_AstStReclinerForwardMoveButton";
CM_ SG_ 346 DPSS_AstStRclBwdMvBtn "DPSS_AstStReclinerBackwardMoveButton";
CM_ SG_ 346 DPSS_AstStHgtUpMvBtn "DPSS_AstStHeightUpMoveButton";
CM_ SG_ 346 DPSS_AstStHgtDnMvBtn "DPSS_AstStHeightDownMoveButton";
CM_ SG_ 346 DPSS_AstStTltUpMvBtn "DPSS_AstStTiltUpMoveButton";
CM_ SG_ 346 DPSS_AstStTltDnMvBtn "DPSS_AstStTiltDownMoveButton";
CM_ SG_ 346 DPSS_AstStHRestUpMvBtn "DPSS_AstStHead Rest UpMoveButton";
CM_ SG_ 346 DPSS_AstStHRestDnMvBtn "DPSS_AstStHead Rest DownMoveButton";
CM_ SG_ 346 DPSS_AstStHRestFwdMvBtn "DPSS_AstStHead Rest ForwardMoveButton";
CM_ SG_ 346 DPSS_AstStHRestBwdMvBtn "DPSS_AstStHead Rest BackwardMoveButton";
CM_ SG_ 346 DPSS_AstStExtFwdMvBtn "DPSS_AstStExtensionForwardMoveButton";
CM_ SG_ 346 DPSS_AstStExtBwdMvBtn "DPSS_AstStExtensionBackwardMoveButton";
CM_ SG_ 346 DPSS_WalkInSwitchSts "DPSS_WalkInSwitchStatus";
CM_ BO_ 347 "[PE] Periodic and On Event";
CM_ SG_ 347 DSAU_LumbarUpDis "DSAU_LumbarUppperDisplay";
CM_ SG_ 347 DSAU_LumbarMidDis "DSAU_LumbarMidDisplay";
CM_ SG_ 347 DSAU_LumbarLowDis "DSAU_LumbarLowerDisplay";
CM_ SG_ 347 DSAU_LumbarDefDis "DSAU_LumbarDeflationDisplay";
CM_ BO_ 348 "[PE] Periodic and On Event";
CM_ SG_ 348 DSAU_BolsterInfDis "DSAU_BolsterInflationDisplay";
CM_ SG_ 348 DSAU_BolsterDefDis "DSAU_BolsterDeflationDisplay";
CM_ BO_ 349 "[PE] Periodic and On Event";
CM_ SG_ 349 DSAU_CushInfDis "DSAU_CushionInflationDisplay";
CM_ SG_ 349 DSAU_CushDefDis "DSAU_CushionDeflationDisplay";
CM_ BO_ 350 "[PE] Periodic and On Event";
CM_ SG_ 350 DSAU_AirSptTimeRValueSet "Air Support Time(Massage Time) USM R Value";
CM_ SG_ 350 DSAU_DrvPostureAssistRValueSet "Drive Seat Posture Assist Function USM R Value";
CM_ SG_ 350 DSAU_DrvSmtAirSptRValueSet "Seat Smart Air Support Function USM R Value";
CM_ SG_ 350 DSAU_DrvSmtSptRValueSet "Seat Smart Support Function USM R Value";
CM_ SG_ 350 DSAU_DrvPostureAssistDis "Seat body Support Function Display Request";
CM_ SG_ 350 DSAU_CushSoftRValueSet "Cushion Soft R Value";
CM_ SG_ 350 DSAU_BackSoftRValueSet "Back Soft USM R Value";
CM_ SG_ 350 DSAU_AirSptModeRValueSet "Air Support Mode(Massage Mode) USM R Value";
CM_ SG_ 350 DSAU_MsgModeSts "Air Support Mode Function Operating Display";
CM_ SG_ 350 DSAU_MsgModeStrength "Air Support intensity regulation(Massage Strenth)";
CM_ SG_ 350 DSAU_MoodTrpyRValueSet "Drive Seat Mood Therapy R Value";
CM_ SG_ 350 DSAU_MoodTrpyCareSta "Drive Seat Mood Therapy Care Mode R Value";
CM_ SG_ 350 DSAU_MoodTrpyComfSta "Drive Seat Mood Therapy Comfort Mode R Value";
CM_ SG_ 350 DASU_AirSptStrRValueSet "Air Support Strenth(Massage Strenth) USM R Value";
CM_ BO_ 2407787009 "[PE] Periodic and On Event";
CM_ SG_ 2407787009 DVRS_Rec_Crash "Crash recoding On/Off Status";
CM_ SG_ 2407787009 DVRS_Rec_Normal_Prk "Parked Normal Recording On/Off Status";
CM_ SG_ 2407787009 DVRS_Timelapse "Timelapse Recording On/Off Status";
CM_ SG_ 2407787009 DVRS_Rec_Manual "Manual recoding On/Off Status";
CM_ SG_ 2407787009 DVRS_Prk_time "The operation time of park mode";
CM_ SG_ 2407787009 DVRS_Rec_Normal "Normal recoding  On/Off  Status";
CM_ SG_ 2407787009 DVRS_Prk_Crash_Event_Count "The number of park crash event";
CM_ SG_ 2407787009 DVRS_Status "Validity of DVRS information";
CM_ SG_ 2407787009 DVRS_Event_Sound "DVRS Event Sound";
CM_ SG_ 2407787009 DVRS_BeepSound "Beep sound when touching AVN screen";
CM_ SG_ 2407787009 DVRS_Display "This signal means whether to display Built-in Cam or AVN mode in AVN screen.";
CM_ SG_ 2407787009 BLTN_CAM_UpdateSWType "0x0: Old/Privious version, 0x1 : New version";
CM_ SG_ 2407787009 DVRS_RecSet_Normal "0x00:Default, 0x01:Off, 0x02:On, 0x03:Invalid";
CM_ SG_ 2407787009 DVRS_RecSet_Crash "0x00:Default, 0x01:Off, 0x02:On, 0x03:Invalid";
CM_ SG_ 2407787009 DVRS_RecSet_Normal_Prk "0x00:Default, 0x01:Off, 0x02:On, 0x03:Invalid";
CM_ SG_ 2407787009 DVRS_RecSet_Crash_Prk "0x00:Default, 0x01:Off, 0x02:On, 0x03:Invalid";
CM_ SG_ 2407787009 DVRS_Rec_Crash_Prk "Crash Recording On/Off Status";
CM_ BO_ 319 "[EC] On Event and On Change";
CM_ BO_ 335 "[EC] On Event and On Change";
CM_ BO_ 351 "[EC] On Event and On Change";
CM_ BO_ 1873 "[TP] Transport Protocol";
CM_ BO_ 1842 "[TP] Transport Protocol";
CM_ BO_ 1841 "[TP] Transport Protocol";
CM_ BO_ 1828 "[TP] Transport Protocol";
CM_ BO_ 2458166529 "[PE] Periodic and On Event";
CM_ SG_ 2458166529 C_RLUnFldSw_HU "2nd Left side seat folding control : UnFolding";
CM_ SG_ 2458166529 C_RLTiltUpSw_HU "2nd Left side seat Moving control : Tilt Up";
CM_ SG_ 2458166529 C_RRTiltDownSw_HU "2nd Right side seat Moving control : Tilt Down";
CM_ SG_ 2458166529 C_RRTiltUpSw_HU "2nd Right side seat Moving control : Tilt Up";
CM_ SG_ 2458166529 C_RLRclBwdSw_HU "2nd Left side seat Moving control :Recline Backward";
CM_ SG_ 2458166529 C_RLRclFwdSw_HU "2nd Left side seat Moving control : Recline Forward";
CM_ SG_ 2458166529 C_RLFldSw_HU "2nd Left side seat folding control : Folding";
CM_ SG_ 2458166529 C_RRRclBwdSw_HU "2nd Right side seat Moving control :Recline Backward";
CM_ SG_ 2458166529 C_RRRclFwdSw_HU "2nd Right side seat Moving control :Recline Forward";
CM_ SG_ 2458166529 C_TLHrestFldSw_HU "3rdLeft side seat Headrest folding control : Folding";
CM_ SG_ 2458166529 C_TRHrestFldSw_HU "3rd Right side seat Headrest folding control : Folding";
CM_ SG_ 2458166529 C_RLRlxSW_HU "2nd Left side seat Moving control : Relax mode";
CM_ SG_ 2458166529 C_RRRlxSW_HU "2nd Right side seat Moving control : Relax mode";
CM_ SG_ 2458166529 C_RRUnWalkInSw_HU "2nd Right side seat moving switch: Un Walk in";
CM_ SG_ 2458166529 C_RRWalkInSw_HU "2nd Right side seat moving switch : Walk In";
CM_ SG_ 2458166529 C_TLFldSw_HU "3rd Left side seat folding control : Folding";
CM_ SG_ 2458166529 C_TRFldSw_HU "3rd Right side seat folding control : Folding";
CM_ SG_ 2458166529 C_RRUnFldSw_HU "2nd Right side seat folding control : UnFolding";
CM_ SG_ 2458166529 C_RLUnWalkInSw_HU "2nd Left side seat moving switch: Un Walkin";
CM_ SG_ 2458166529 C_RLWalkInSw_HU "2nd Right side seat moving switch:Un walk in";
CM_ SG_ 2458166529 C_TRRclBwdSw_HU "3rd right side seat Moving Swtich: Recline Backward";
CM_ SG_ 2458166529 C_TRRclFwdSw_HU "3rd right side seat Moving Swtich: Recline Forward";
CM_ SG_ 2458166529 C_RRFldSw_HU "2nd Right side seat folding control : Folding";
CM_ SG_ 2458166529 C_TLRclBwdSw_HU "3rd left side seat Moving Swtich: Recline Backward";
CM_ SG_ 2458166529 C_TLRclFwdSw_HU "3rd left side seat Moving Swtich: Recline Forward";
CM_ SG_ 2458166529 C_RLTiltDownSw_HU "2nd Left side seat Moving control : Tilt Down";
CM_ BO_ 2315419905 "[EC] On Event and On Change";
CM_ BO_ 2462364673 "[PE] Periodic and On Event";
CM_ SG_ 2462364673 POS_V2_3_Offset "Information for Position moving distance during Position Age.
-Transmitting Map Matching Moving Distance(m) of Vehicles for 200ms by this signal";
CM_ SG_ 2462364673 POS_V2_3_PathIndex "Information for Index of current path: If this number differs from one specified in previous POSITION message, vehicle left the original path.";
CM_ SG_ 2462364673 POS_V2_3_CyclicCounter "Information for Cyclic counter of this message type: Reconstructor can use this value to detect missing messages.";
CM_ SG_ 2462364673 POS_V2_3_RangeAvgSpeed "Information for Range camera average speed
(km/h)
This is used when entering the range camera area.";
CM_ SG_ 2462364673 POS_V2_3_CurrAltitude100m "Information for altitude(height) value of current position in 100m unit";
CM_ SG_ 2462364673 POS_V2_3_CurrAltitude1m "Information for altitude(height) value of current position in 1m unit";
CM_ SG_ 2462364673 POS_V2_3_CurrFuncRoadClass "Information for Functional Road Class of Current Position indicates relative importance of the road in the routing network and lower values indicate higher priority";
CM_ SG_ 2462364673 POS_V2_3_CurrFormOfWay "Information for Link Class Value of current position";
CM_ SG_ 2462364673 POS_V2_3_CurrDirectionLanes "Information for the Number of lanes in driving direction of current position";
CM_ SG_ 2462364673 POS_V2_3_CurrSpeedLimit "Information for Current Link Speed Limit of current position expressed as kph or mph according to META_SpeedUnit";
CM_ SG_ 2462364673 POS_V2_3_CurrTrafficSpeed "Information for the traffic speed of the current position expressed as kph or mph according to META speed unit";
CM_ BO_ 2466562561 "[EC] On Event and On Change";
CM_ SG_ 2466562561 C_RH_Unfolding_SW "3rd RH Seat Unfolding Switch";
CM_ SG_ 2466562561 C_PSMHeightNValueSet "USM request for Seat Easy Access(Height)";
CM_ SG_ 2466562561 C_AVN_PTGHeightNValueSet "Power Tailgate(Trunk) Height Request Signal";
CM_ SG_ 2466562561 CF_AVN_SCCMLReset "Request for SCC-ML reset";
CM_ SG_ 2466562561 C_RH_Folding_SW "3rd RH Seat Folding Switch";
CM_ SG_ 2466562561 C_HAnBNValueSet "USM Request for Horn Feedback";
CM_ SG_ 2466562561 CF_AVN_RrSeatRemindNValueSet "USM Request for Rear Seat Remind function";
CM_ SG_ 2466562561 CF_AVN_DSWNValueSet "Request for driver state warning";
CM_ SG_ 2466562561 CF_AVN_RRPSU_RLNValueSet "Request for Seat easy access of rear left seat";
CM_ SG_ 2466562561 CF_AVN_APSUNValueSet "Request for easy access of passenger seat";
CM_ SG_ 2466562561 CF_AVN_NCC_CameraNValueSet "Request for Eco Vehicle NCC";
CM_ SG_ 2466562561 CF_AVN_FCAJnctnNValueSet "Request for foward cross traffic safety";
CM_ SG_ 2466562561 CF_AVN_RRPSU_RRNValueSet "Request for seat easy access of rear right seat";
CM_ SG_ 2466562561 C_LH_Unfolding_SW "3rd LH Seat Unfolding Switch";
CM_ SG_ 2466562561 CF_AVN_HtBlcAstNValueSet "Request for Passenger seat heater balance";
CM_ SG_ 2466562561 CF_AVN_HtBlcDrvNValueSet "Request for Driver seat heater balance";
CM_ SG_ 2466562561 CF_AVN_SCCModeNValueSet "This signal request for scc setting(Whether sccml or following driving mode)";
CM_ SG_ 2466562561 CF_AVN_SCCMLChar1Set "Request for scc-ml acceleration learning result change";
CM_ SG_ 2466562561 CF_AVN_UIPNValueSet "USM Request for Ultrasonic Intrusion Protection function";
CM_ SG_ 2466562561 CF_AVN_SCCMLChar2Set "Request for scc-ml distnace learning result change";
CM_ SG_ 2466562561 CF_AVN_SCCMLChar3Set "Request for scc-ml reaction learning result change";
CM_ SG_ 2466562561 C_LH_Folding_SW "3RD LH Seat Folding Swtich";
CM_ SG_ 2466562561 CF_AVN_HDALCFuncNValueSet "Request for highway lane change assist";
CM_ BO_ 1818 "[TP] Transport Protocol";
CM_ BO_ 1850 "[TP] Transport Protocol";
CM_ BO_ 1849 "[TP] Transport Protocol";
CM_ BO_ 1836 "[TP] Transport Protocol";
CM_ BO_ 799 "[PE] Periodic and On Event";
CM_ SG_ 799 SBCM_DRV_Crc1Val "SBCM_DRV_CyclicRedundancyCheck1Value";
CM_ SG_ 799 C_ApprOpenStatus "Stop fob searching signal";
CM_ SG_ 799 SBCM_DRV_AlvCnt1Val "SBCM_DRV_AliveCounter1Value";
CM_ SG_ 799 Warn_DrvDrSwSta_SBCM "DoorLock_DriverDoorSwitchStatus ##2G## -  - C_DrvDrSw,CF_Gway_DrvDrSw,Warn_DrvDrSwSta";
CM_ SG_ 799 DoorLock_DrvDrUnLkSta_SBCM "DoorLock_DriverDoorUnLockStatus ##2G## -  - C_DrvUnlockState,CF_Gway_DrvUnlockState";
CM_ SG_ 799 C_DrvDoorApproachOpen "Approach open";
CM_ BO_ 2164277250 "[P] Periodic";
CM_ SG_ 2164277250 TCU_CurrGearSta "TCU_CurrentGearStatus";
CM_ SG_ 2164277250 TCH_EngTrgtGearSta "TCU_EngineTargetGear";
CM_ SG_ 2164277250 TCU_EngTqLimVal "TCU_EngineTorqueLimitValue";
CM_ SG_ 2164277250 TCU_VehSpdKphVal "TCU_VehicleSpeedKphValue";
CM_ SG_ 2164277250 TCU_TrgtGearSta "TCU_TargetGearStatus";
CM_ SG_ 2164277250 TCU_DcmlVehSpdKphVal "TCU_VehicleSpeedDecimalKphValue";
CM_ SG_ 2164277250 TCU_SprkRtrdReq "TCU_SparkRetardAngleValue";
CM_ SG_ 2164277250 TCU_EngRpmDisSta "TCU_EngineRpmDisplayStatus";
CM_ SG_ 2164277250 TCU_GearLmpBlnkngReq "TCU_GearLampBlinkingRequest";
CM_ SG_ 2164277250 TCU_FuelCutInhbtReq "TCU_FuelCutInhibitionRequest";
CM_ SG_ 2164277250 TCU_IdleUpReq "TCU_IdleUpRequest";
CM_ SG_ 2164277250 TCU_CluTrgtGearSta "TCU_ClusterTargetGear";
CM_ BO_ 2164277251 "[P] Periodic";
CM_ SG_ 2164277251 TCU_EngRpmDis "TCU_EngineRpmDisplay";
CM_ SG_ 2164277251 TCU_SlpVal "TCU_SlopeValue";
CM_ SG_ 2164277251 TCU_EngSpdIncReq "TCU_EngineSpeedIncreaseRequest";
CM_ SG_ 2164277251 TCU_ObdSta "TCU_ObdStatus";
CM_ SG_ 2164277251 TCU_SprtyIndxSta "TCU_SportyIndexStatus";
CM_ SG_ 2164277251 TCU_DrvngModDis "TCU_DrivingModeDisplay";
CM_ SG_ 2164277251 TCU_DrvngModReq "TCU_DrivingModeRequest";
CM_ SG_ 2164277251 TCU_SmrtShftSta "TCU_SmartShiftStatus";
CM_ SG_ 2164277251 TCU_LupTrgtEngSpdVal "TCU_LupTargetEngineSpeedValue";
CM_ SG_ 2164277251 TCU_FrtStcShftSta "TCU_FirstStaticShiftStatus";
CM_ SG_ 2164277251 TCU_IsgInhbtReq "TCU_IsgInhibitRequest";
CM_ SG_ 2164277251 TCU_CdaInhbtReq "TCU_CdaInhibitRequest";
CM_ SG_ 2164277251 TCU_BrkOnReq "TCU_BrakeOnRequest";
CM_ SG_ 2164277251 TCU_TqGrdntLimVal "TCU_TorqueGradientLimitationValue";
BA_DEF_ BO_ "DiagState" ENUM "No","Yes" ;
BA_DEF_ BO_ "DiagResponse" ENUM "No","Yes" ;
BA_DEF_ BO_ "DiagRequest" ENUM "No","Yes" ;
BA_DEF_ BO_ "TpMessage" ENUM "No","Yes" ;
BA_DEF_ BO_ "UsrMsgIDSforwardDeviation" INT 0 100 ;
BA_DEF_ BO_ "UsrMsgIDSbackwardDeviation" INT 50 1000 ;
BA_DEF_ BO_ "GenMsgCycleTime" INT 0 2000 ;
BA_DEF_ BO_ "GenMsgStartDelayTime" INT 0 2000 ;
BA_DEF_ BO_ "GenMsgSendType" ENUM "Cyclic","NoMsgSendType" ;
BA_DEF_ BO_ "GenMsgCycleTimeFast" INT 0 500 ;
BA_DEF_ BO_ "GenMsgDelayTime" INT 0 20 ;
BA_DEF_ BO_ "GenMsgILSupport" ENUM "No","Yes" ;
BA_DEF_ BO_ "GenMsgNrOfRepetition" INT 0 3 ;
BA_DEF_ BO_ "NmMessage" ENUM "No","Yes" ;
BA_DEF_ BO_ "NWM-Botschaft" ENUM "No","Yes" ;
BA_DEF_ BO_ "TpTxIndex" INT 0 255 ;
BA_DEF_ BO_ "VFrameFormat" ENUM "StandardCAN","ExtendedCAN","reserved","reserved","reserved","reserved","reserved","reserved","reserved","reserved","reserved","reserved","reserved","reserved","StandardCAN_FD","ExtendedCAN_FD" ;
BA_DEF_ SG_ "UserSigValidity" ENUM "B+","ACC","IG","IG1","IG2","IG3","IG1 or IG2","IG1 or IG3","Undef" ;
BA_DEF_ SG_ "TimeoutValue" STRING ;
BA_DEF_ SG_ "UsrSigPurpose" ENUM "Undef","FN","DIAG","DIAG(Req)","DIAG(Res)","DIAG(Phy)","DEV","CCP(Req)","CCP(Res)","NM","TP" ;
BA_DEF_ SG_ "GenSigStartValue" INT 0 1215752192 ;
BA_DEF_ SG_ "NetworkRequest" ENUM "Yes","No" ;
BA_DEF_ SG_ "NetworkRequestHoldingTime" INT 0 65535 ;
BA_DEF_ SG_ "Description" STRING ;
BA_DEF_ SG_ "Version" STRING ;
BA_DEF_ SG_ "GenSigEnvVarType" ENUM "Int","Float","Undef" ;
BA_DEF_ SG_ "GenSigSendType" ENUM "Cyclic","OnWrite","OnWriteWithRepetition","OnChange","OnChangeWithRepetition","IfActive","IfActiveWithRepetition","NoSigSendType","OnChangeAndIfActive","OnChangeAndIfActiveWithRepetition" ;
BA_DEF_ SG_ "GwSigLatencyTime" INT 0 65536 ;
BA_DEF_ SG_ "GwSigMissingSourceType" ENUM "Undef","OldValue","DefaultValue","InitialValue" ;
BA_DEF_ SG_ "NWM-WakeupAllowed" ENUM "<n.a.>" ;
BA_DEF_ SG_ "RoutingFactor" INT 1 1215752192 ;
BA_DEF_REL_ BU_SG_REL_ "GenSigTimeoutTime" INT 0 7000 ;
BA_DEF_DEF_ "DiagState" "No" ;
BA_DEF_DEF_ "DiagResponse" "No" ;
BA_DEF_DEF_ "DiagRequest" "No" ;
BA_DEF_DEF_ "TpMessage" "No" ;
BA_DEF_DEF_ "UsrMsgIDSforwardDeviation" 10 ;
BA_DEF_DEF_ "UsrMsgIDSbackwardDeviation" 100 ;
BA_DEF_DEF_ "GenMsgCycleTime" 200 ;
BA_DEF_DEF_ "GenMsgStartDelayTime" 0 ;
BA_DEF_DEF_ "GenMsgSendType" "NoMsgSendType" ;
BA_DEF_DEF_ "GenMsgCycleTimeFast" 40 ;
BA_DEF_DEF_ "GenMsgDelayTime" 20 ;
BA_DEF_DEF_ "GenMsgILSupport" "Yes" ;
BA_DEF_DEF_ "GenMsgNrOfRepetition" 3 ;
BA_DEF_DEF_ "NmMessage" "No" ;
BA_DEF_DEF_ "NWM-Botschaft" "No" ;
BA_DEF_DEF_ "TpTxIndex" 0 ;
BA_DEF_DEF_ "VFrameFormat" "StandardCAN" ;
BA_DEF_DEF_ "UserSigValidity" "IG" ;
BA_DEF_DEF_ "TimeoutValue" "" ;
BA_DEF_DEF_ "UsrSigPurpose" "FN" ;
BA_DEF_DEF_ "GenSigStartValue" 0 ;
BA_DEF_DEF_ "NetworkRequest" "No" ;
BA_DEF_DEF_ "NetworkRequestHoldingTime" 0 ;
BA_DEF_DEF_ "Description" "" ;
BA_DEF_DEF_ "Version" "" ;
BA_DEF_DEF_ "GenSigEnvVarType" "Undef" ;
BA_DEF_DEF_ "GenSigSendType" "NoSigSendType" ;
BA_DEF_DEF_ "GwSigLatencyTime" 40 ;
BA_DEF_DEF_ "GwSigMissingSourceType" "Undef" ;
BA_DEF_DEF_ "NWM-WakeupAllowed" "<n.a.>" ;
BA_DEF_DEF_ "RoutingFactor" 1 ;
BA_DEF_DEF_REL_ "GenSigTimeoutTime" 500 ;
BA_ "GenMsgSendType" BO_ 2239848449 0;
BA_ "GenMsgCycleTime" BO_ 2239848449 20;
BA_ "GenMsgCycleTimeFast" BO_ 2239848449 0;
BA_ "GenMsgNrOfRepetition" BO_ 2239848449 0;
BA_ "GenMsgDelayTime" BO_ 2239848449 0;
BA_ "VFrameFormat" BO_ 2239848449 1;
BA_ "Description" SG_ 2239848449 ADAS_CMD_Crc10Val "The data area for CRC calculation is based on the data length (DLC) of the message DB.

The CRC shall be calculated over the entire data block (excluding the CRC bytes) including the user data, alive counter and Data ID

 

- CRC Polynomial (0x1021) , Initial Value : 0xFFFF, XOR value : 0x0000, Data ID : Message ID + 0xF800 

- The initial value is for CRC calculation and the message should be sent with the calculated result value. 

- The mathematical expression to 16 bit CRC polynomial is given here. G(x) = x16 + x12 + x5 + 1";
BA_ "GenSigStartValue" SG_ 2239848449 ADAS_CMD_Crc10Val 65535;
BA_ "UserSigValidity" SG_ 2239848449 ADAS_CMD_Crc10Val 3;
BA_ "RoutingFactor" SG_ 2239848449 ADAS_CMD_Crc10Val 5;
BA_ "Version" SG_ 2239848449 ADAS_CMD_Crc10Val "21.01.08";
BA_ "Description" SG_ 2239848449 ADAS_CMD_AlvCnt10Val "For the first transmission request for a data element the counter shall be initialized with 0 and shall be incremented by 1 for every subsequent send request. 

When the counter reaches the maximum value(0xFF), then it shall restart with 0 for the next send request";
BA_ "UserSigValidity" SG_ 2239848449 ADAS_CMD_AlvCnt10Val 3;
BA_ "RoutingFactor" SG_ 2239848449 ADAS_CMD_AlvCnt10Val 5;
BA_ "Version" SG_ 2239848449 ADAS_CMD_AlvCnt10Val "21.01.08";
BA_ "Description" SG_ 2239848449 FCA_OnOffEquipSta "This signal describes the FCA Function.

- 시스템 장착 여부 및 시스템 on/off 정보";
BA_ "UserSigValidity" SG_ 2239848449 FCA_OnOffEquipSta 3;
BA_ "RoutingFactor" SG_ 2239848449 FCA_OnOffEquipSta 5;
BA_ "Version" SG_ 2239848449 FCA_OnOffEquipSta "21.01.08";
BA_ "Description" SG_ 2239848449 FCA_SysFlrSta "This signal describes the failure information of FCA Function.

- 시스템 정상 또는 카메라/레이더/시스템 고장상태 정보

0x1: Temporary unavailable by Front View Camera (blockage, high temperature, etc) for Sensor Fusion FCA 

0x2: Temporary unavailable by Front Radar (blockage, high temperature, etc) for either Radar only FCA or Sensor Fusion FCA when logic is in Front Radar

0x3: System failure (Failure by Front View Camera failure, Front Radar failure or relative cooperative control units, etc)

0x4: Temporary unavailable by Front View Camera (blockage, high temperature, etc) for Front View Camera only FCA

0x5: Temporary unavailable of steering function by Front View Camera (blockage, high temperature, etc) for sensor fusion when logic is in ADAS_DRV

0x6: Temporary unavailable by Front Radar (blockage, high temperature, etc) for Sensor Fusion FCA when logic is in Front View Camera";
BA_ "UserSigValidity" SG_ 2239848449 FCA_SysFlrSta 3;
BA_ "RoutingFactor" SG_ 2239848449 FCA_SysFlrSta 5;
BA_ "Version" SG_ 2239848449 FCA_SysFlrSta "21.01.08";
BA_ "Description" SG_ 2239848449 FCA_WrngLvlSta "Request CLU to activate the corresponding warning device(s) according to the FCA warning level. (Braking / Steering act)

- FCA 기능의 제동 및 조향 제어 작동 상태 표시용 정보신호";
BA_ "UserSigValidity" SG_ 2239848449 FCA_WrngLvlSta 3;
BA_ "RoutingFactor" SG_ 2239848449 FCA_WrngLvlSta 5;
BA_ "Version" SG_ 2239848449 FCA_WrngLvlSta "21.01.08";
BA_ "Description" SG_ 2239848449 FCA_VehStpReq "A control request flag for vehicle stop. FCA expects vehicle to be controlled to a complete stop and hold its state by ESC.



- FCA 제동상황 종료후 정차 상태 유지를 위한 신호";
BA_ "UserSigValidity" SG_ 2239848449 FCA_VehStpReq 3;
BA_ "RoutingFactor" SG_ 2239848449 FCA_VehStpReq 5;
BA_ "Version" SG_ 2239848449 FCA_VehStpReq "17.12.00";
BA_ "Description" SG_ 2239848449 FCA_StbltActvReq "Depending on the driving situation, FCA tells PSB to release(no alert), retract or pull the seat belt for occupant protection or warning.

- FCA 제동상황시 시트벨트 작동을 위한 정보 신호";
BA_ "UserSigValidity" SG_ 2239848449 FCA_StbltActvReq 3;
BA_ "RoutingFactor" SG_ 2239848449 FCA_StbltActvReq 5;
BA_ "Version" SG_ 2239848449 FCA_StbltActvReq "17.12.00";
BA_ "Description" SG_ 2239848449 FCA_HydrlcBstAsstReq "Depending on the driving situation, FCA tells ESC to use lowered HBA (Hydraulic Boost Assist) threshold to sensitize the HBA entrance. 

The boost assist function is more easily activated than under normal driving condition.

- FCA 제동상황시 HBA 작동을 위한 정보 신호";
BA_ "UserSigValidity" SG_ 2239848449 FCA_HydrlcBstAsstReq 3;
BA_ "RoutingFactor" SG_ 2239848449 FCA_HydrlcBstAsstReq 5;
BA_ "Version" SG_ 2239848449 FCA_HydrlcBstAsstReq "21.01.08";
BA_ "Description" SG_ 2239848449 FCA_DclReqVal "Depending on the driving situation, FCA gives ESC the deceleration command. ESC maintains the deceleration.

- FCA 제동을 위한 요구 감속도 값";
BA_ "UserSigValidity" SG_ 2239848449 FCA_DclReqVal 3;
BA_ "RoutingFactor" SG_ 2239848449 FCA_DclReqVal 5;
BA_ "Version" SG_ 2239848449 FCA_DclReqVal "21.01.08";
BA_ "Description" SG_ 2239848449 FCA_PrefillActvReq "A control requeset flag for FCA first warning. (Audible Warning)

- FCA 1차 제동상황 요청신호";
BA_ "UserSigValidity" SG_ 2239848449 FCA_PrefillActvReq 3;
BA_ "RoutingFactor" SG_ 2239848449 FCA_PrefillActvReq 5;
BA_ "Version" SG_ 2239848449 FCA_PrefillActvReq "17.12.00";
BA_ "Description" SG_ 2239848449 FCA_PartialActvReq "A control requeset flag for FCA second warning. (Partial braking)

- FCA 2차 제동상황 요청신호";
BA_ "UserSigValidity" SG_ 2239848449 FCA_PartialActvReq 3;
BA_ "RoutingFactor" SG_ 2239848449 FCA_PartialActvReq 5;
BA_ "Version" SG_ 2239848449 FCA_PartialActvReq "17.11.00";
BA_ "Description" SG_ 2239848449 FCA_FullActvReq "A control requeset flag for FCA third warning. (Full braking)

- FCA 3차 제동상황 요청신호";
BA_ "UserSigValidity" SG_ 2239848449 FCA_FullActvReq 3;
BA_ "RoutingFactor" SG_ 2239848449 FCA_FullActvReq 5;
BA_ "Version" SG_ 2239848449 FCA_FullActvReq "17.11.00";
BA_ "Description" SG_ 2239848449 FCA_SnstvtyModRetVal "This signal is FCA sensitive set mode switch(USM) info return value to cluster.

- FCA 민감도 설정 관련 USM 설정 스위치 정보의 리턴 값";
BA_ "UserSigValidity" SG_ 2239848449 FCA_SnstvtyModRetVal 3;
BA_ "RoutingFactor" SG_ 2239848449 FCA_SnstvtyModRetVal 5;
BA_ "Version" SG_ 2239848449 FCA_SnstvtyModRetVal "17.12.00";
BA_ "Description" SG_ 2239848449 FCA_WrngSndSta "FCA warning sound status";
BA_ "UserSigValidity" SG_ 2239848449 FCA_WrngSndSta 3;
BA_ "RoutingFactor" SG_ 2239848449 FCA_WrngSndSta 5;
BA_ "Version" SG_ 2239848449 FCA_WrngSndSta "18.12.04";
BA_ "GenMsgSendType" BO_ 2239848450 0;
BA_ "GenMsgCycleTime" BO_ 2239848450 20;
BA_ "GenMsgCycleTimeFast" BO_ 2239848450 0;
BA_ "GenMsgNrOfRepetition" BO_ 2239848450 0;
BA_ "GenMsgDelayTime" BO_ 2239848450 0;
BA_ "VFrameFormat" BO_ 2239848450 1;
BA_ "Description" SG_ 2239848450 FCA_RelVel "This signal indicates the relative velocity between the host vehicle and a forward vehicle.







(PH) = ((HEX)-0FFH)*0.1 [m/s/digit]



       = (HEX)*0.1 [m/s/digit] - 25.5 [m/s]



CAN Message Physical range : Max. Relative velocity : 0x1FE(25.5m/s), Zero : 0x0FF(0m/s), Min. Relative velocity : 0x000(-25.5m/s)";
BA_ "UserSigValidity" SG_ 2239848450 FCA_RelVel 3;
BA_ "RoutingFactor" SG_ 2239848450 FCA_RelVel 5;
BA_ "Version" SG_ 2239848450 FCA_RelVel "21.01.08";
BA_ "Description" SG_ 2239848450 FCA_Jnctn_OnOffEquipSta "This signal describes the FCA-JC Function.

- 시스템 장착 여부 및 시스템 on/off 정보";
BA_ "UserSigValidity" SG_ 2239848450 FCA_Jnctn_OnOffEquipSta 3;
BA_ "RoutingFactor" SG_ 2239848450 FCA_Jnctn_OnOffEquipSta 5;
BA_ "Version" SG_ 2239848450 FCA_Jnctn_OnOffEquipSta "21.01.08";
BA_ "Description" SG_ 2239848450 HDP_EMOpSta "EM On (Not Active/Active), Off status";
BA_ "UserSigValidity" SG_ 2239848450 HDP_EMOpSta 3;
BA_ "RoutingFactor" SG_ 2239848450 HDP_EMOpSta 5;
BA_ "Version" SG_ 2239848450 HDP_EMOpSta "20.06.05";
BA_ "Description" SG_ 2239848450 FCA_WrngTrgtDis "Request CLU to activate the corresponding warning device(s) according to the type of FCA warning target.

- FCA 경고 대상 종류별 표시 정보신호";
BA_ "UserSigValidity" SG_ 2239848450 FCA_WrngTrgtDis 3;
BA_ "RoutingFactor" SG_ 2239848450 FCA_WrngTrgtDis 5;
BA_ "Version" SG_ 2239848450 FCA_WrngTrgtDis "21.01.08";
BA_ "Description" SG_ 2239848450 ADAS_DRV_FCA_Plus_Sta "전방카메라, 전방레이더 및 전측방 레이더/후측방 레이터 퓨전 트랙을 통해 FCA-Car 타겟 및 자차 좌측/우측 영역 회피 불가능 여부를 판단하여 FCA-Car/Ped/Cyc+ Flag를 출력함";
BA_ "UserSigValidity" SG_ 2239848450 ADAS_DRV_FCA_Plus_Sta 3;
BA_ "RoutingFactor" SG_ 2239848450 ADAS_DRV_FCA_Plus_Sta 5;
BA_ "Version" SG_ 2239848450 ADAS_DRV_FCA_Plus_Sta "21.01.08";
BA_ "Description" SG_ 2239848450 EM_WrngLvlSta "Request CLU to activate the corresponding warning device(s) according to the EM warning level. (Braking / Steering act)

- EM 기능의 제동 및 조향 제어 작동 상태 표시용 정보신호";
BA_ "UserSigValidity" SG_ 2239848450 EM_WrngLvlSta 3;
BA_ "RoutingFactor" SG_ 2239848450 EM_WrngLvlSta 5;
BA_ "Version" SG_ 2239848450 EM_WrngLvlSta "19.12.00";
BA_ "Description" SG_ 2239848450 BrkDelVLimReq "- Request ESC whether to release brake control or not when FCA or EM function reduces vehicle’s velocity over 50km/h for ISO 26262.

- FCA 또는 EM 작동 중 ESC가 50km/h 초과 감속 시 제동제어 해제/미해제 요청 신호 (ISO 26262 대응)";
BA_ "UserSigValidity" SG_ 2239848450 BrkDelVLimReq 3;
BA_ "RoutingFactor" SG_ 2239848450 BrkDelVLimReq 5;
BA_ "Version" SG_ 2239848450 BrkDelVLimReq "20.03.00";
BA_ "Description" SG_ 2239848450 FCA_TimetoCllsn "This signal indicates predictive time to Collision between the host vehicle and a forward vehicle.







(PH) = 10*(HEX) [ms]



CAN Message Physical range : 0 ~ 2540 [ms], Resolution : 10ms";
BA_ "GenSigStartValue" SG_ 2239848450 FCA_TimetoCllsn 254;
BA_ "UserSigValidity" SG_ 2239848450 FCA_TimetoCllsn 3;
BA_ "RoutingFactor" SG_ 2239848450 FCA_TimetoCllsn 5;
BA_ "Version" SG_ 2239848450 FCA_TimetoCllsn "19.06.03";
BA_ "GenMsgSendType" BO_ 2256644609 0;
BA_ "GenMsgCycleTime" BO_ 2256644609 100;
BA_ "GenMsgCycleTimeFast" BO_ 2256644609 0;
BA_ "GenMsgNrOfRepetition" BO_ 2256644609 0;
BA_ "VFrameFormat" BO_ 2256644609 1;
BA_ "Description" SG_ 2256644609 CLU_Crc1Val "The data area for CRC calculation is based on the data length (DLC) of the message DB.

The CRC shall be calculated over the entire data block (excluding the CRC bytes) including the user data, alive counter and Data ID

 

- CRC Polynomial (0x1021) , Initial Value : 0xFFFF, XOR value : 0x0000, Data ID : Message ID + 0xF800 

- The initial value is for CRC calculation and the message should be sent with the calculated result value. 

- The mathematical expression to 16 bit CRC polynomial is given here. G(x) = x16 + x12 + x5 + 1";
BA_ "GenSigStartValue" SG_ 2256644609 CLU_Crc1Val 65535;
BA_ "UserSigValidity" SG_ 2256644609 CLU_Crc1Val 3;
BA_REL_ "GenSigTimeoutTime" BU_SG_REL_ PSM SG_ 2256644609 CLU_Crc1Val 1500;
BA_REL_ "GenSigTimeoutTime" BU_SG_REL_ RRPSM SG_ 2256644609 CLU_Crc1Val 1500;
BA_REL_ "GenSigTimeoutTime" BU_SG_REL_ SHVU_RR SG_ 2256644609 CLU_Crc1Val 1500;
BA_REL_ "GenSigTimeoutTime" BU_SG_REL_ DPSS SG_ 2256644609 CLU_Crc1Val 1500;
BA_REL_ "GenSigTimeoutTime" BU_SG_REL_ ATS SG_ 2256644609 CLU_Crc1Val 1500;
BA_ "RoutingFactor" SG_ 2256644609 CLU_Crc1Val 5;
BA_ "Version" SG_ 2256644609 CLU_Crc1Val "18.11.08";
BA_ "Description" SG_ 2256644609 CLU_AlvCnt1Val "For the first transmission request for a data element the counter shall be initialized with 0 and shall be incremented by 1 for every subsequent send request. 

When the counter reaches the maximum value(0xFF), then it shall restart with 0 for the next send request";
BA_ "UserSigValidity" SG_ 2256644609 CLU_AlvCnt1Val 3;
BA_REL_ "GenSigTimeoutTime" BU_SG_REL_ PSM SG_ 2256644609 CLU_AlvCnt1Val 1500;
BA_REL_ "GenSigTimeoutTime" BU_SG_REL_ RRPSM SG_ 2256644609 CLU_AlvCnt1Val 1500;
BA_REL_ "GenSigTimeoutTime" BU_SG_REL_ SHVU_RR SG_ 2256644609 CLU_AlvCnt1Val 1500;
BA_REL_ "GenSigTimeoutTime" BU_SG_REL_ DPSS SG_ 2256644609 CLU_AlvCnt1Val 1500;
BA_REL_ "GenSigTimeoutTime" BU_SG_REL_ ATS SG_ 2256644609 CLU_AlvCnt1Val 1500;
BA_ "RoutingFactor" SG_ 2256644609 CLU_AlvCnt1Val 5;
BA_ "Version" SG_ 2256644609 CLU_AlvCnt1Val "18.11.08";
BA_ "Description" SG_ 2256644609 CLU_DtntOutSta "This signal indicates the status of detent illumination. Cluster sends the detent information for a Unified Illumination system.";
BA_ "UserSigValidity" SG_ 2256644609 CLU_DtntOutSta 0;
BA_REL_ "GenSigTimeoutTime" BU_SG_REL_ RLPSM SG_ 2256644609 CLU_DtntOutSta 1500;
BA_REL_ "GenSigTimeoutTime" BU_SG_REL_ DPSS SG_ 2256644609 CLU_DtntOutSta 1500;
BA_REL_ "GenSigTimeoutTime" BU_SG_REL_ FPM SG_ 2256644609 CLU_DtntOutSta 1500;
BA_REL_ "GenSigTimeoutTime" BU_SG_REL_ ATS SG_ 2256644609 CLU_DtntOutSta 1500;
BA_REL_ "GenSigTimeoutTime" BU_SG_REL_ DSAU SG_ 2256644609 CLU_DtntOutSta 1500;
BA_REL_ "GenSigTimeoutTime" BU_SG_REL_ ASAU SG_ 2256644609 CLU_DtntOutSta 1500;
BA_ "RoutingFactor" SG_ 2256644609 CLU_DtntOutSta 5;
BA_ "Version" SG_ 2256644609 CLU_DtntOutSta "17.11.00";
BA_ "Description" SG_ 2256644609 CLU_SpdUnitTyp "This signal indicates the unit of the speed displayed in the speedometer.";
BA_ "UserSigValidity" SG_ 2256644609 CLU_SpdUnitTyp 3;
BA_REL_ "GenSigTimeoutTime" BU_SG_REL_ PSM SG_ 2256644609 CLU_SpdUnitTyp 1500;
BA_REL_ "GenSigTimeoutTime" BU_SG_REL_ ICC SG_ 2256644609 CLU_SpdUnitTyp 1500;
BA_ "RoutingFactor" SG_ 2256644609 CLU_SpdUnitTyp 5;
BA_ "Version" SG_ 2256644609 CLU_SpdUnitTyp "17.11.00";
BA_ "Description" SG_ 2256644609 CLU_DisSpdDcmlVal "The signal 'CF_Clu_VanzDecimal' means the extra value of the signal 'CF_Clu_Vanz' (vehicle speed which is indicated in the speedometer)

Also, This signal should be sent in km/h or MPH according to the 'CF_Clu_SPEED_UNIT' signal.

CF_Clu_SPEED_UNIT = 0 : [km/h]

CF_Clu_SPEED_UNIT = 1 : [MPH]



Example)   CF_Clu_Vanz = 13,  CF_Clu_VanzDecimal  = 3

Displayed vehicle speed  = (CF_Clu_Vanz / 2) + (CF_Clu_VanzDecimal / 8)

= ( 13 / 2 ) + ( 3 / 8 ) = 6.875 [Km/h or MPH]";
BA_ "UserSigValidity" SG_ 2256644609 CLU_DisSpdDcmlVal 3;
BA_REL_ "GenSigTimeoutTime" BU_SG_REL_ PSM SG_ 2256644609 CLU_DisSpdDcmlVal 1500;
BA_ "RoutingFactor" SG_ 2256644609 CLU_DisSpdDcmlVal 5;
BA_ "Version" SG_ 2256644609 CLU_DisSpdDcmlVal "17.11.00";
BA_ "Description" SG_ 2256644609 CLU_RhstaLvlSta "This signal is used for a rheostat level of CLUSTER from 1 to 21 level (21 level : Detent) for a Unified Illumination system.



※ Start Value : Current value";
BA_ "UserSigValidity" SG_ 2256644609 CLU_RhstaLvlSta 0;
BA_REL_ "GenSigTimeoutTime" BU_SG_REL_ PSM SG_ 2256644609 CLU_RhstaLvlSta 1500;
BA_REL_ "GenSigTimeoutTime" BU_SG_REL_ RLPSM SG_ 2256644609 CLU_RhstaLvlSta 1500;
BA_REL_ "GenSigTimeoutTime" BU_SG_REL_ DPSS SG_ 2256644609 CLU_RhstaLvlSta 1500;
BA_REL_ "GenSigTimeoutTime" BU_SG_REL_ FPM SG_ 2256644609 CLU_RhstaLvlSta 1500;
BA_REL_ "GenSigTimeoutTime" BU_SG_REL_ ATS SG_ 2256644609 CLU_RhstaLvlSta 1500;
BA_REL_ "GenSigTimeoutTime" BU_SG_REL_ DSAU SG_ 2256644609 CLU_RhstaLvlSta 1500;
BA_REL_ "GenSigTimeoutTime" BU_SG_REL_ ASAU SG_ 2256644609 CLU_RhstaLvlSta 1500;
BA_ "RoutingFactor" SG_ 2256644609 CLU_RhstaLvlSta 5;
BA_ "Version" SG_ 2256644609 CLU_RhstaLvlSta "17.11.00";
BA_ "Description" SG_ 2256644609 CLU_DisSpdVal "The vehicle speed which is indicated in the speedmeter has to be sent to SCC. This value is used for evalution of SCC command values instead of the vehicle velocity in order to avoid significant difference between the speedmeter indicator and the set speed indicator(especially in the case of free cruising with the set speed). In terms of debouning and presnce on CAN, the same time scales have to be used and described for time gap setting.

This signal should be sent in km/h or MPH according to the “SPEED_UNIT” signal.

SPEED_UNIT = 0 : [km/h]

SPEED_UNIT = 1 : [MPH]";
BA_ "UserSigValidity" SG_ 2256644609 CLU_DisSpdVal 3;
BA_REL_ "GenSigTimeoutTime" BU_SG_REL_ PSM SG_ 2256644609 CLU_DisSpdVal 1500;
BA_REL_ "GenSigTimeoutTime" BU_SG_REL_ ICC SG_ 2256644609 CLU_DisSpdVal 1500;
BA_ "RoutingFactor" SG_ 2256644609 CLU_DisSpdVal 5;
BA_ "Version" SG_ 2256644609 CLU_DisSpdVal "17.12.03";
BA_ "GenMsgSendType" BO_ 2256644610 0;
BA_ "GenMsgCycleTime" BO_ 2256644610 100;
BA_ "GenMsgCycleTimeFast" BO_ 2256644610 0;
BA_ "GenMsgNrOfRepetition" BO_ 2256644610 0;
BA_ "VFrameFormat" BO_ 2256644610 1;
BA_ "Description" SG_ 2256644610 CLU_DisSpdVal_KPH "The vehicle speed which is indicated in the speedmeter.

This signal should be sent in km/h only.";
BA_ "UserSigValidity" SG_ 2256644610 CLU_DisSpdVal_KPH 3;
BA_REL_ "GenSigTimeoutTime" BU_SG_REL_ RWPC SG_ 2256644610 CLU_DisSpdVal_KPH 1500;
BA_REL_ "GenSigTimeoutTime" BU_SG_REL_ PSM SG_ 2256644610 CLU_DisSpdVal_KPH 1500;
BA_REL_ "GenSigTimeoutTime" BU_SG_REL_ APSM SG_ 2256644610 CLU_DisSpdVal_KPH 1500;
BA_REL_ "GenSigTimeoutTime" BU_SG_REL_ RLPSM SG_ 2256644610 CLU_DisSpdVal_KPH 1500;
BA_REL_ "GenSigTimeoutTime" BU_SG_REL_ RRPSM SG_ 2256644610 CLU_DisSpdVal_KPH 1500;
BA_REL_ "GenSigTimeoutTime" BU_SG_REL_ RLHV SG_ 2256644610 CLU_DisSpdVal_KPH 1500;
BA_REL_ "GenSigTimeoutTime" BU_SG_REL_ RRHV SG_ 2256644610 CLU_DisSpdVal_KPH 1500;
BA_REL_ "GenSigTimeoutTime" BU_SG_REL_ SHVU_RR SG_ 2256644610 CLU_DisSpdVal_KPH 1500;
BA_REL_ "GenSigTimeoutTime" BU_SG_REL_ DPSS SG_ 2256644610 CLU_DisSpdVal_KPH 1500;
BA_REL_ "GenSigTimeoutTime" BU_SG_REL_ ATS SG_ 2256644610 CLU_DisSpdVal_KPH 1500;
BA_REL_ "GenSigTimeoutTime" BU_SG_REL_ DSAU SG_ 2256644610 CLU_DisSpdVal_KPH 1500;
BA_REL_ "GenSigTimeoutTime" BU_SG_REL_ ASAU SG_ 2256644610 CLU_DisSpdVal_KPH 1500;
BA_ "RoutingFactor" SG_ 2256644610 CLU_DisSpdVal_KPH 5;
BA_ "Version" SG_ 2256644610 CLU_DisSpdVal_KPH "17.12.09";
BA_ "Description" SG_ 2256644610 CLU_CUSTOMSta_NEW "This is a signal for New concept CUSTOM mode in AVN USM

This is a confirm signal for selecting CUSTOM mode in AVN USM

And Other units refer this signal when CUSTOM mode (CLU_DrvngModSwSta=0x6

). Other unit decided the Detailed CUSTOM Mode with this signal

EX>

 In AVN USM, MY DRIVE MODE is selected, sent CLU_CUSTOMSta_NEW= 0x1

In vehicle, current mode is MY DRIVE MODE, other unit refer this signal and decide detailed Mode.In this case, MY DRIVE MODE is a mode";
BA_ "UserSigValidity" SG_ 2256644610 CLU_CUSTOMSta_NEW 3;
BA_ "RoutingFactor" SG_ 2256644610 CLU_CUSTOMSta_NEW 5;
BA_ "Version" SG_ 2256644610 CLU_CUSTOMSta_NEW "20.08.07";
BA_ "Description" SG_ 2256644610 CLU_AutoBrightSta "This signal is used for a auto bright level of CLUSTER from 1step to 200step for a Unified Illumination system.



※ Start Value : Current value";
BA_ "UserSigValidity" SG_ 2256644610 CLU_AutoBrightSta 0;
BA_ "RoutingFactor" SG_ 2256644610 CLU_AutoBrightSta 5;
BA_ "Version" SG_ 2256644610 CLU_AutoBrightSta "20.12.05";
BA_ "GenMsgSendType" BO_ 2395189249 0;
BA_ "VFrameFormat" BO_ 2395189249 1;
BA_ "Description" SG_ 2395189249 DATC_Crc8Val "The data area for CRC calculation is based on the data length (DLC) of the message DB.

The CRC shall be calculated over the entire data block (excluding the CRC bytes) including the user data, alive counter and Data ID

 

- CRC Polynomial (0x1021) , Initial Value : 0xFFFF, XOR value : 0x0000, Data ID : Message ID + 0xF800 

- The initial value is for CRC calculation and the message should be sent with the calculated result value. 

- The mathematical expression to 16 bit CRC polynomial is given here. G(x) = x16 + x12 + x5 + 1";
BA_ "GenSigSendType" SG_ 2395189249 DATC_Crc8Val 4;
BA_ "GenSigStartValue" SG_ 2395189249 DATC_Crc8Val 65535;
BA_ "UserSigValidity" SG_ 2395189249 DATC_Crc8Val 3;
BA_ "Version" SG_ 2395189249 DATC_Crc8Val "18.11.08";
BA_ "Description" SG_ 2395189249 DATC_AlvCnt8Val "For the first transmission request for a data element the counter shall be initialized with 0 and shall be incremented by 1 for every subsequent send request. 

When the counter reaches the maximum value(0xFF), then it shall restart with 0 for the next send request";
BA_ "GenSigSendType" SG_ 2395189249 DATC_AlvCnt8Val 4;
BA_ "UserSigValidity" SG_ 2395189249 DATC_AlvCnt8Val 3;
BA_ "Version" SG_ 2395189249 DATC_AlvCnt8Val "18.11.08";
BA_ "GenSigSendType" SG_ 2395189249 DATC_SmrtVntOnOffSta 4;
BA_ "GenSigStartValue" SG_ 2395189249 DATC_SmrtVntOnOffSta 3;
BA_ "UserSigValidity" SG_ 2395189249 DATC_SmrtVntOnOffSta 3;
BA_ "Version" SG_ 2395189249 DATC_SmrtVntOnOffSta "17.11.00";
BA_ "GenSigSendType" SG_ 2395189249 DATC_PsAutoDis 4;
BA_ "UserSigValidity" SG_ 2395189249 DATC_PsAutoDis 3;
BA_REL_ "GenSigTimeoutTime" BU_SG_REL_ ATS SG_ 2395189249 DATC_PsAutoDis 1500;
BA_ "Version" SG_ 2395189249 DATC_PsAutoDis "17.11.00";
BA_ "GenSigSendType" SG_ 2395189249 DATC_RrAutoDis 4;
BA_ "UserSigValidity" SG_ 2395189249 DATC_RrAutoDis 3;
BA_REL_ "GenSigTimeoutTime" BU_SG_REL_ ATS SG_ 2395189249 DATC_RrAutoDis 1500;
BA_ "Version" SG_ 2395189249 DATC_RrAutoDis "17.11.00";
BA_ "GenSigSendType" SG_ 2395189249 DATC_RrDrvModDis 4;
BA_ "UserSigValidity" SG_ 2395189249 DATC_RrDrvModDis 7;
BA_REL_ "GenSigTimeoutTime" BU_SG_REL_ ATS SG_ 2395189249 DATC_RrDrvModDis 1500;
BA_ "Version" SG_ 2395189249 DATC_RrDrvModDis "18.11.05";
BA_ "Description" SG_ 2395189249 DATC_DisplayThemes "This signal indicates DATC lcd white or black themes. (only TFT LCD type)";
BA_ "GenSigSendType" SG_ 2395189249 DATC_DisplayThemes 4;
BA_ "UserSigValidity" SG_ 2395189249 DATC_DisplayThemes 7;
BA_ "Version" SG_ 2395189249 DATC_DisplayThemes "20.01.01";
BA_ "Description" SG_ 2395189249 DATC_AUTOStepPS "This signal indicates Passenger AUTO step status in case Multi Auto Blower type.";
BA_ "GenSigSendType" SG_ 2395189249 DATC_AUTOStepPS 4;
BA_ "UserSigValidity" SG_ 2395189249 DATC_AUTOStepPS 7;
BA_ "Version" SG_ 2395189249 DATC_AUTOStepPS "19.12.00";
BA_ "Description" SG_ 2395189249 DATC_AUTOStepRR "This signal indicates Rear AUTO step status in case Multi Auto Blower type.";
BA_ "GenSigSendType" SG_ 2395189249 DATC_AUTOStepRR 4;
BA_ "UserSigValidity" SG_ 2395189249 DATC_AUTOStepRR 7;
BA_ "Version" SG_ 2395189249 DATC_AUTOStepRR "19.12.00";
BA_ "GenMsgSendType" BO_ 2378398721 0;
BA_ "VFrameFormat" BO_ 2378398721 1;
BA_ "Description" SG_ 2378398721 DATC_Crc20Val "The data area for CRC calculation is based on the data length (DLC) of the message DB.

The CRC shall be calculated over the entire data block (excluding the CRC bytes) including the user data, alive counter and Data ID

 

- CRC Polynomial (0x1021) , Initial Value : 0xFFFF, XOR value : 0x0000, Data ID : Message ID + 0xF800 

- The initial value is for CRC calculation and the message should be sent with the calculated result value. 

- The mathematical expression to 16 bit CRC polynomial is given here. G(x) = x16 + x12 + x5 + 1";
BA_ "GenSigSendType" SG_ 2378398721 DATC_Crc20Val 4;
BA_ "GenSigStartValue" SG_ 2378398721 DATC_Crc20Val 65535;
BA_ "UserSigValidity" SG_ 2378398721 DATC_Crc20Val 3;
BA_ "Version" SG_ 2378398721 DATC_Crc20Val "21.01.02";
BA_ "Description" SG_ 2378398721 DATC_AlvCnt20Val "For the first transmission request for a data element the counter shall be initialized with 0 and shall be incremented by 1 for every subsequent send request. 

When the counter reaches the maximum value(0xFF), then it shall restart with 0 for the next send request";
BA_ "GenSigSendType" SG_ 2378398721 DATC_AlvCnt20Val 4;
BA_ "UserSigValidity" SG_ 2378398721 DATC_AlvCnt20Val 3;
BA_ "Version" SG_ 2378398721 DATC_AlvCnt20Val "21.01.02";
BA_ "Description" SG_ 2378398721 DATC_FragStrhUSMSta "This signal indicate frangrance strength USM state";
BA_ "GenSigSendType" SG_ 2378398721 DATC_FragStrhUSMSta 4;
BA_ "UserSigValidity" SG_ 2378398721 DATC_FragStrhUSMSta 7;
BA_REL_ "GenSigTimeoutTime" BU_SG_REL_ ATS SG_ 2378398721 DATC_FragStrhUSMSta 1500;
BA_ "Version" SG_ 2378398721 DATC_FragStrhUSMSta "21.01.02";
BA_ "Description" SG_ 2378398721 DATC_FragKindUSMSta "This signal indicate fragrance kind USM state.";
BA_ "GenSigSendType" SG_ 2378398721 DATC_FragKindUSMSta 4;
BA_ "UserSigValidity" SG_ 2378398721 DATC_FragKindUSMSta 7;
BA_REL_ "GenSigTimeoutTime" BU_SG_REL_ ATS SG_ 2378398721 DATC_FragKindUSMSta 1500;
BA_ "Version" SG_ 2378398721 DATC_FragKindUSMSta "21.01.02";
BA_ "Description" SG_ 2378398721 DATC_Frag1ExpireDisp "This signal indicate Expire Display of Fragrance No.1";
BA_ "GenSigSendType" SG_ 2378398721 DATC_Frag1ExpireDisp 4;
BA_ "UserSigValidity" SG_ 2378398721 DATC_Frag1ExpireDisp 7;
BA_REL_ "GenSigTimeoutTime" BU_SG_REL_ ATS SG_ 2378398721 DATC_Frag1ExpireDisp 1500;
BA_ "Version" SG_ 2378398721 DATC_Frag1ExpireDisp "21.01.02";
BA_ "Description" SG_ 2378398721 DATC_FragStrhDis "This signal indicate frangrance strength display value.";
BA_ "GenSigSendType" SG_ 2378398721 DATC_FragStrhDis 4;
BA_ "UserSigValidity" SG_ 2378398721 DATC_FragStrhDis 7;
BA_REL_ "GenSigTimeoutTime" BU_SG_REL_ ATS SG_ 2378398721 DATC_FragStrhDis 1500;
BA_ "Version" SG_ 2378398721 DATC_FragStrhDis "21.01.02";
BA_ "Description" SG_ 2378398721 DATC_FragKindDis "This signal indicate fragrance kind display value.";
BA_ "GenSigSendType" SG_ 2378398721 DATC_FragKindDis 4;
BA_ "UserSigValidity" SG_ 2378398721 DATC_FragKindDis 7;
BA_REL_ "GenSigTimeoutTime" BU_SG_REL_ ATS SG_ 2378398721 DATC_FragKindDis 1500;
BA_ "Version" SG_ 2378398721 DATC_FragKindDis "21.01.02";
BA_ "Description" SG_ 2378398721 DATC_Frag2ExpireDisp "This signal indicate Expire Display of Fragrance No.2";
BA_ "GenSigSendType" SG_ 2378398721 DATC_Frag2ExpireDisp 4;
BA_ "UserSigValidity" SG_ 2378398721 DATC_Frag2ExpireDisp 7;
BA_REL_ "GenSigTimeoutTime" BU_SG_REL_ ATS SG_ 2378398721 DATC_Frag2ExpireDisp 1500;
BA_ "Version" SG_ 2378398721 DATC_Frag2ExpireDisp "21.01.02";
BA_ "Description" SG_ 2378398721 DATC_VitalityFragranceSta "This signal indicate USM setting state of Fragrance for Vatality Mood.";
BA_ "GenSigSendType" SG_ 2378398721 DATC_VitalityFragranceSta 4;
BA_ "UserSigValidity" SG_ 2378398721 DATC_VitalityFragranceSta 3;
BA_ "Version" SG_ 2378398721 DATC_VitalityFragranceSta "21.01.02";
BA_ "Description" SG_ 2378398721 DATC_DelightFragranceSta "This signal indicate USM setting state of Fragrance for Delight Mood.";
BA_ "GenSigSendType" SG_ 2378398721 DATC_DelightFragranceSta 4;
BA_ "UserSigValidity" SG_ 2378398721 DATC_DelightFragranceSta 3;
BA_ "Version" SG_ 2378398721 DATC_DelightFragranceSta "21.01.02";
BA_ "Description" SG_ 2378398721 DATC_CareFragranceSta "This signal indicate USM setting state of Fragrance for Care Mood.";
BA_ "GenSigSendType" SG_ 2378398721 DATC_CareFragranceSta 4;
BA_ "UserSigValidity" SG_ 2378398721 DATC_CareFragranceSta 3;
BA_ "Version" SG_ 2378398721 DATC_CareFragranceSta "21.01.02";
BA_ "Description" SG_ 2378398721 DATC_ComfortFragranceSta "This signal indicate USM setting state of Fragrance for Comfort Mood.";
BA_ "GenSigSendType" SG_ 2378398721 DATC_ComfortFragranceSta 4;
BA_ "UserSigValidity" SG_ 2378398721 DATC_ComfortFragranceSta 3;
BA_ "Version" SG_ 2378398721 DATC_ComfortFragranceSta "21.01.02";
BA_ "Description" SG_ 2378398721 DATC_Frag1Inform "This signal indicate Fragrance 1 information.";
BA_ "GenSigSendType" SG_ 2378398721 DATC_Frag1Inform 4;
BA_ "UserSigValidity" SG_ 2378398721 DATC_Frag1Inform 7;
BA_REL_ "GenSigTimeoutTime" BU_SG_REL_ ATS SG_ 2378398721 DATC_Frag1Inform 1500;
BA_ "Version" SG_ 2378398721 DATC_Frag1Inform "21.07.06";
BA_ "Description" SG_ 2378398721 DATC_Frag1RemainDisp "This signal indicate Remain Display of Fragrance No.1";
BA_ "GenSigSendType" SG_ 2378398721 DATC_Frag1RemainDisp 4;
BA_ "UserSigValidity" SG_ 2378398721 DATC_Frag1RemainDisp 7;
BA_REL_ "GenSigTimeoutTime" BU_SG_REL_ ATS SG_ 2378398721 DATC_Frag1RemainDisp 1500;
BA_ "Version" SG_ 2378398721 DATC_Frag1RemainDisp "21.01.02";
BA_ "Description" SG_ 2378398721 DATC_Frag2Inform "This signal indicate Fragrance 2 Information.";
BA_ "GenSigSendType" SG_ 2378398721 DATC_Frag2Inform 4;
BA_ "UserSigValidity" SG_ 2378398721 DATC_Frag2Inform 7;
BA_REL_ "GenSigTimeoutTime" BU_SG_REL_ ATS SG_ 2378398721 DATC_Frag2Inform 1500;
BA_ "Version" SG_ 2378398721 DATC_Frag2Inform "21.07.06";
BA_ "Description" SG_ 2378398721 DATC_Frag2RemainDisp "This signal indicate Remains Display of Fragrance No.2";
BA_ "GenSigSendType" SG_ 2378398721 DATC_Frag2RemainDisp 4;
BA_ "UserSigValidity" SG_ 2378398721 DATC_Frag2RemainDisp 7;
BA_REL_ "GenSigTimeoutTime" BU_SG_REL_ ATS SG_ 2378398721 DATC_Frag2RemainDisp 1500;
BA_ "Version" SG_ 2378398721 DATC_Frag2RemainDisp "21.01.02";
BA_ "GenMsgSendType" BO_ 346 0;
BA_ "Description" SG_ 346 DPSS_AstStCrc1Val "DPSS_AstStCyclicRedundancyCheck1Value";
BA_ "GenSigSendType" SG_ 346 DPSS_AstStCrc1Val 4;
BA_ "GenSigStartValue" SG_ 346 DPSS_AstStCrc1Val 255;
BA_ "UserSigValidity" SG_ 346 DPSS_AstStCrc1Val 3;
BA_REL_ "GenSigTimeoutTime" BU_SG_REL_ APSM SG_ 346 DPSS_AstStCrc1Val 1500;
BA_ "NetworkRequest" SG_ 346 DPSS_AstStCrc1Val 0;
BA_ "Version" SG_ 346 DPSS_AstStCrc1Val "19.11.06";
BA_ "Description" SG_ 346 DPSS_AstStAlvCnt1Val "DPSS_AstStAliveCounter1Value";
BA_ "GenSigSendType" SG_ 346 DPSS_AstStAlvCnt1Val 4;
BA_ "UserSigValidity" SG_ 346 DPSS_AstStAlvCnt1Val 3;
BA_REL_ "GenSigTimeoutTime" BU_SG_REL_ APSM SG_ 346 DPSS_AstStAlvCnt1Val 1500;
BA_ "NetworkRequest" SG_ 346 DPSS_AstStAlvCnt1Val 0;
BA_ "NetworkRequestHoldingTime" SG_ 346 DPSS_AstStAlvCnt1Val 5000;
BA_ "Version" SG_ 346 DPSS_AstStAlvCnt1Val "19.11.06";
BA_ "Description" SG_ 346 DPSS_AstSldFwdMvBtn "DPSS_AstStSlideForwardMoveButton";
BA_ "GenSigSendType" SG_ 346 DPSS_AstSldFwdMvBtn 4;
BA_ "UserSigValidity" SG_ 346 DPSS_AstSldFwdMvBtn 3;
BA_REL_ "GenSigTimeoutTime" BU_SG_REL_ APSM SG_ 346 DPSS_AstSldFwdMvBtn 1500;
BA_REL_ "GenSigTimeoutTime" BU_SG_REL_ RRPSM SG_ 346 DPSS_AstSldFwdMvBtn 1500;
BA_ "NetworkRequest" SG_ 346 DPSS_AstSldFwdMvBtn 0;
BA_ "NetworkRequestHoldingTime" SG_ 346 DPSS_AstSldFwdMvBtn 5000;
BA_ "Version" SG_ 346 DPSS_AstSldFwdMvBtn "19.11.06";
BA_ "Description" SG_ 346 DPSS_AstStSldBwdMvBtn "DPSS_AstStSlideBackwardMoveButton";
BA_ "GenSigSendType" SG_ 346 DPSS_AstStSldBwdMvBtn 4;
BA_ "UserSigValidity" SG_ 346 DPSS_AstStSldBwdMvBtn 3;
BA_REL_ "GenSigTimeoutTime" BU_SG_REL_ APSM SG_ 346 DPSS_AstStSldBwdMvBtn 1500;
BA_REL_ "GenSigTimeoutTime" BU_SG_REL_ RRPSM SG_ 346 DPSS_AstStSldBwdMvBtn 1500;
BA_ "NetworkRequest" SG_ 346 DPSS_AstStSldBwdMvBtn 0;
BA_ "NetworkRequestHoldingTime" SG_ 346 DPSS_AstStSldBwdMvBtn 5000;
BA_ "Version" SG_ 346 DPSS_AstStSldBwdMvBtn "19.11.06";
BA_ "Description" SG_ 346 DPSS_AstStRclFwdMvBtn "DPSS_AstStReclinerForwardMoveButton";
BA_ "GenSigSendType" SG_ 346 DPSS_AstStRclFwdMvBtn 4;
BA_ "UserSigValidity" SG_ 346 DPSS_AstStRclFwdMvBtn 3;
BA_REL_ "GenSigTimeoutTime" BU_SG_REL_ APSM SG_ 346 DPSS_AstStRclFwdMvBtn 1500;
BA_REL_ "GenSigTimeoutTime" BU_SG_REL_ RRPSM SG_ 346 DPSS_AstStRclFwdMvBtn 1500;
BA_ "NetworkRequest" SG_ 346 DPSS_AstStRclFwdMvBtn 0;
BA_ "NetworkRequestHoldingTime" SG_ 346 DPSS_AstStRclFwdMvBtn 5000;
BA_ "Version" SG_ 346 DPSS_AstStRclFwdMvBtn "19.11.06";
BA_ "Description" SG_ 346 DPSS_AstStRclBwdMvBtn "DPSS_AstStReclinerBackwardMoveButton";
BA_ "GenSigSendType" SG_ 346 DPSS_AstStRclBwdMvBtn 4;
BA_ "UserSigValidity" SG_ 346 DPSS_AstStRclBwdMvBtn 3;
BA_REL_ "GenSigTimeoutTime" BU_SG_REL_ APSM SG_ 346 DPSS_AstStRclBwdMvBtn 1500;
BA_REL_ "GenSigTimeoutTime" BU_SG_REL_ RRPSM SG_ 346 DPSS_AstStRclBwdMvBtn 1500;
BA_ "NetworkRequest" SG_ 346 DPSS_AstStRclBwdMvBtn 0;
BA_ "NetworkRequestHoldingTime" SG_ 346 DPSS_AstStRclBwdMvBtn 5000;
BA_ "Version" SG_ 346 DPSS_AstStRclBwdMvBtn "19.11.06";
BA_ "Description" SG_ 346 DPSS_AstStHgtUpMvBtn "DPSS_AstStHeightUpMoveButton";
BA_ "GenSigSendType" SG_ 346 DPSS_AstStHgtUpMvBtn 4;
BA_ "UserSigValidity" SG_ 346 DPSS_AstStHgtUpMvBtn 3;
BA_REL_ "GenSigTimeoutTime" BU_SG_REL_ APSM SG_ 346 DPSS_AstStHgtUpMvBtn 1500;
BA_REL_ "GenSigTimeoutTime" BU_SG_REL_ RRPSM SG_ 346 DPSS_AstStHgtUpMvBtn 1500;
BA_ "NetworkRequest" SG_ 346 DPSS_AstStHgtUpMvBtn 0;
BA_ "NetworkRequestHoldingTime" SG_ 346 DPSS_AstStHgtUpMvBtn 5000;
BA_ "Version" SG_ 346 DPSS_AstStHgtUpMvBtn "19.11.06";
BA_ "Description" SG_ 346 DPSS_AstStHgtDnMvBtn "DPSS_AstStHeightDownMoveButton";
BA_ "GenSigSendType" SG_ 346 DPSS_AstStHgtDnMvBtn 4;
BA_ "UserSigValidity" SG_ 346 DPSS_AstStHgtDnMvBtn 3;
BA_REL_ "GenSigTimeoutTime" BU_SG_REL_ APSM SG_ 346 DPSS_AstStHgtDnMvBtn 1500;
BA_REL_ "GenSigTimeoutTime" BU_SG_REL_ RRPSM SG_ 346 DPSS_AstStHgtDnMvBtn 1500;
BA_ "NetworkRequest" SG_ 346 DPSS_AstStHgtDnMvBtn 0;
BA_ "NetworkRequestHoldingTime" SG_ 346 DPSS_AstStHgtDnMvBtn 5000;
BA_ "Version" SG_ 346 DPSS_AstStHgtDnMvBtn "19.11.06";
BA_ "Description" SG_ 346 DPSS_AstStTltUpMvBtn "DPSS_AstStTiltUpMoveButton";
BA_ "GenSigSendType" SG_ 346 DPSS_AstStTltUpMvBtn 4;
BA_ "UserSigValidity" SG_ 346 DPSS_AstStTltUpMvBtn 3;
BA_REL_ "GenSigTimeoutTime" BU_SG_REL_ APSM SG_ 346 DPSS_AstStTltUpMvBtn 1500;
BA_REL_ "GenSigTimeoutTime" BU_SG_REL_ RRPSM SG_ 346 DPSS_AstStTltUpMvBtn 1500;
BA_ "NetworkRequest" SG_ 346 DPSS_AstStTltUpMvBtn 0;
BA_ "NetworkRequestHoldingTime" SG_ 346 DPSS_AstStTltUpMvBtn 5000;
BA_ "Version" SG_ 346 DPSS_AstStTltUpMvBtn "19.11.06";
BA_ "Description" SG_ 346 DPSS_AstStTltDnMvBtn "DPSS_AstStTiltDownMoveButton";
BA_ "GenSigSendType" SG_ 346 DPSS_AstStTltDnMvBtn 4;
BA_ "UserSigValidity" SG_ 346 DPSS_AstStTltDnMvBtn 3;
BA_REL_ "GenSigTimeoutTime" BU_SG_REL_ APSM SG_ 346 DPSS_AstStTltDnMvBtn 1500;
BA_REL_ "GenSigTimeoutTime" BU_SG_REL_ RRPSM SG_ 346 DPSS_AstStTltDnMvBtn 1500;
BA_ "NetworkRequest" SG_ 346 DPSS_AstStTltDnMvBtn 0;
BA_ "NetworkRequestHoldingTime" SG_ 346 DPSS_AstStTltDnMvBtn 5000;
BA_ "Version" SG_ 346 DPSS_AstStTltDnMvBtn "19.11.06";
BA_ "Description" SG_ 346 DPSS_AstStHRestUpMvBtn "DPSS_AstStHead Rest UpMoveButton";
BA_ "GenSigSendType" SG_ 346 DPSS_AstStHRestUpMvBtn 4;
BA_ "UserSigValidity" SG_ 346 DPSS_AstStHRestUpMvBtn 3;
BA_REL_ "GenSigTimeoutTime" BU_SG_REL_ APSM SG_ 346 DPSS_AstStHRestUpMvBtn 1500;
BA_REL_ "GenSigTimeoutTime" BU_SG_REL_ RRPSM SG_ 346 DPSS_AstStHRestUpMvBtn 1500;
BA_ "NetworkRequest" SG_ 346 DPSS_AstStHRestUpMvBtn 0;
BA_ "NetworkRequestHoldingTime" SG_ 346 DPSS_AstStHRestUpMvBtn 5000;
BA_ "Version" SG_ 346 DPSS_AstStHRestUpMvBtn "19.11.06";
BA_ "Description" SG_ 346 DPSS_AstStHRestDnMvBtn "DPSS_AstStHead Rest DownMoveButton";
BA_ "GenSigSendType" SG_ 346 DPSS_AstStHRestDnMvBtn 4;
BA_ "UserSigValidity" SG_ 346 DPSS_AstStHRestDnMvBtn 3;
BA_REL_ "GenSigTimeoutTime" BU_SG_REL_ APSM SG_ 346 DPSS_AstStHRestDnMvBtn 1500;
BA_REL_ "GenSigTimeoutTime" BU_SG_REL_ RRPSM SG_ 346 DPSS_AstStHRestDnMvBtn 1500;
BA_ "NetworkRequest" SG_ 346 DPSS_AstStHRestDnMvBtn 0;
BA_ "NetworkRequestHoldingTime" SG_ 346 DPSS_AstStHRestDnMvBtn 5000;
BA_ "Version" SG_ 346 DPSS_AstStHRestDnMvBtn "19.11.06";
BA_ "Description" SG_ 346 DPSS_AstStHRestFwdMvBtn "DPSS_AstStHead Rest ForwardMoveButton";
BA_ "GenSigSendType" SG_ 346 DPSS_AstStHRestFwdMvBtn 4;
BA_ "UserSigValidity" SG_ 346 DPSS_AstStHRestFwdMvBtn 3;
BA_REL_ "GenSigTimeoutTime" BU_SG_REL_ APSM SG_ 346 DPSS_AstStHRestFwdMvBtn 1500;
BA_REL_ "GenSigTimeoutTime" BU_SG_REL_ RRPSM SG_ 346 DPSS_AstStHRestFwdMvBtn 1500;
BA_ "NetworkRequest" SG_ 346 DPSS_AstStHRestFwdMvBtn 0;
BA_ "NetworkRequestHoldingTime" SG_ 346 DPSS_AstStHRestFwdMvBtn 5000;
BA_ "Version" SG_ 346 DPSS_AstStHRestFwdMvBtn "19.11.06";
BA_ "Description" SG_ 346 DPSS_AstStHRestBwdMvBtn "DPSS_AstStHead Rest BackwardMoveButton";
BA_ "GenSigSendType" SG_ 346 DPSS_AstStHRestBwdMvBtn 4;
BA_ "UserSigValidity" SG_ 346 DPSS_AstStHRestBwdMvBtn 3;
BA_REL_ "GenSigTimeoutTime" BU_SG_REL_ APSM SG_ 346 DPSS_AstStHRestBwdMvBtn 1500;
BA_REL_ "GenSigTimeoutTime" BU_SG_REL_ RRPSM SG_ 346 DPSS_AstStHRestBwdMvBtn 1500;
BA_ "NetworkRequest" SG_ 346 DPSS_AstStHRestBwdMvBtn 0;
BA_ "NetworkRequestHoldingTime" SG_ 346 DPSS_AstStHRestBwdMvBtn 5000;
BA_ "Version" SG_ 346 DPSS_AstStHRestBwdMvBtn "19.11.06";
BA_ "Description" SG_ 346 DPSS_AstStExtFwdMvBtn "DPSS_AstStExtensionForwardMoveButton";
BA_ "GenSigSendType" SG_ 346 DPSS_AstStExtFwdMvBtn 4;
BA_ "UserSigValidity" SG_ 346 DPSS_AstStExtFwdMvBtn 3;
BA_REL_ "GenSigTimeoutTime" BU_SG_REL_ APSM SG_ 346 DPSS_AstStExtFwdMvBtn 1500;
BA_ "NetworkRequest" SG_ 346 DPSS_AstStExtFwdMvBtn 0;
BA_ "NetworkRequestHoldingTime" SG_ 346 DPSS_AstStExtFwdMvBtn 5000;
BA_ "Version" SG_ 346 DPSS_AstStExtFwdMvBtn "19.11.06";
BA_ "Description" SG_ 346 DPSS_AstStExtBwdMvBtn "DPSS_AstStExtensionBackwardMoveButton";
BA_ "GenSigSendType" SG_ 346 DPSS_AstStExtBwdMvBtn 4;
BA_ "UserSigValidity" SG_ 346 DPSS_AstStExtBwdMvBtn 3;
BA_REL_ "GenSigTimeoutTime" BU_SG_REL_ APSM SG_ 346 DPSS_AstStExtBwdMvBtn 1500;
BA_ "NetworkRequest" SG_ 346 DPSS_AstStExtBwdMvBtn 0;
BA_ "NetworkRequestHoldingTime" SG_ 346 DPSS_AstStExtBwdMvBtn 5000;
BA_ "Version" SG_ 346 DPSS_AstStExtBwdMvBtn "19.11.06";
BA_ "Description" SG_ 346 DPSS_WalkInSwitchSts "DPSS_WalkInSwitchStatus";
BA_ "GenSigSendType" SG_ 346 DPSS_WalkInSwitchSts 4;
BA_ "UserSigValidity" SG_ 346 DPSS_WalkInSwitchSts 3;
BA_ "NetworkRequest" SG_ 346 DPSS_WalkInSwitchSts 0;
BA_ "NetworkRequestHoldingTime" SG_ 346 DPSS_WalkInSwitchSts 5000;
BA_ "Version" SG_ 346 DPSS_WalkInSwitchSts "19.11.06";
BA_ "GenMsgSendType" BO_ 347 0;
BA_ "Description" SG_ 347 DSAU_LumbarUpDis "DSAU_LumbarUppperDisplay";
BA_ "GenSigSendType" SG_ 347 DSAU_LumbarUpDis 4;
BA_ "UserSigValidity" SG_ 347 DSAU_LumbarUpDis 3;
BA_REL_ "GenSigTimeoutTime" BU_SG_REL_ DPSS SG_ 347 DSAU_LumbarUpDis 1500;
BA_REL_ "GenSigTimeoutTime" BU_SG_REL_ CGW_CCU SG_ 347 DSAU_LumbarUpDis 1500;
BA_ "NetworkRequest" SG_ 347 DSAU_LumbarUpDis 0;
BA_ "NetworkRequestHoldingTime" SG_ 347 DSAU_LumbarUpDis 5000;
BA_ "Version" SG_ 347 DSAU_LumbarUpDis "19.11.06";
BA_ "Description" SG_ 347 DSAU_LumbarMidDis "DSAU_LumbarMidDisplay";
BA_ "GenSigSendType" SG_ 347 DSAU_LumbarMidDis 4;
BA_ "UserSigValidity" SG_ 347 DSAU_LumbarMidDis 3;
BA_REL_ "GenSigTimeoutTime" BU_SG_REL_ DPSS SG_ 347 DSAU_LumbarMidDis 1500;
BA_REL_ "GenSigTimeoutTime" BU_SG_REL_ CGW_CCU SG_ 347 DSAU_LumbarMidDis 1500;
BA_ "NetworkRequest" SG_ 347 DSAU_LumbarMidDis 0;
BA_ "NetworkRequestHoldingTime" SG_ 347 DSAU_LumbarMidDis 5000;
BA_ "Version" SG_ 347 DSAU_LumbarMidDis "19.11.06";
BA_ "Description" SG_ 347 DSAU_LumbarLowDis "DSAU_LumbarLowerDisplay";
BA_ "GenSigSendType" SG_ 347 DSAU_LumbarLowDis 4;
BA_ "UserSigValidity" SG_ 347 DSAU_LumbarLowDis 3;
BA_REL_ "GenSigTimeoutTime" BU_SG_REL_ DPSS SG_ 347 DSAU_LumbarLowDis 1500;
BA_REL_ "GenSigTimeoutTime" BU_SG_REL_ CGW_CCU SG_ 347 DSAU_LumbarLowDis 1500;
BA_ "NetworkRequest" SG_ 347 DSAU_LumbarLowDis 0;
BA_ "NetworkRequestHoldingTime" SG_ 347 DSAU_LumbarLowDis 5000;
BA_ "Version" SG_ 347 DSAU_LumbarLowDis "19.11.06";
BA_ "Description" SG_ 347 DSAU_LumbarDefDis "DSAU_LumbarDeflationDisplay";
BA_ "GenSigSendType" SG_ 347 DSAU_LumbarDefDis 4;
BA_ "UserSigValidity" SG_ 347 DSAU_LumbarDefDis 3;
BA_REL_ "GenSigTimeoutTime" BU_SG_REL_ DPSS SG_ 347 DSAU_LumbarDefDis 1500;
BA_REL_ "GenSigTimeoutTime" BU_SG_REL_ CGW_CCU SG_ 347 DSAU_LumbarDefDis 1500;
BA_ "NetworkRequest" SG_ 347 DSAU_LumbarDefDis 0;
BA_ "NetworkRequestHoldingTime" SG_ 347 DSAU_LumbarDefDis 5000;
BA_ "Version" SG_ 347 DSAU_LumbarDefDis "19.11.06";
BA_ "GenMsgSendType" BO_ 348 0;
BA_ "Description" SG_ 348 DSAU_BolsterInfDis "DSAU_BolsterInflationDisplay";
BA_ "GenSigSendType" SG_ 348 DSAU_BolsterInfDis 4;
BA_ "UserSigValidity" SG_ 348 DSAU_BolsterInfDis 3;
BA_REL_ "GenSigTimeoutTime" BU_SG_REL_ DPSS SG_ 348 DSAU_BolsterInfDis 1500;
BA_REL_ "GenSigTimeoutTime" BU_SG_REL_ CGW_CCU SG_ 348 DSAU_BolsterInfDis 1500;
BA_ "NetworkRequest" SG_ 348 DSAU_BolsterInfDis 0;
BA_ "NetworkRequestHoldingTime" SG_ 348 DSAU_BolsterInfDis 5000;
BA_ "Version" SG_ 348 DSAU_BolsterInfDis "19.11.06";
BA_ "Description" SG_ 348 DSAU_BolsterDefDis "DSAU_BolsterDeflationDisplay";
BA_ "GenSigSendType" SG_ 348 DSAU_BolsterDefDis 4;
BA_ "UserSigValidity" SG_ 348 DSAU_BolsterDefDis 3;
BA_REL_ "GenSigTimeoutTime" BU_SG_REL_ DPSS SG_ 348 DSAU_BolsterDefDis 1500;
BA_REL_ "GenSigTimeoutTime" BU_SG_REL_ CGW_CCU SG_ 348 DSAU_BolsterDefDis 1500;
BA_ "NetworkRequest" SG_ 348 DSAU_BolsterDefDis 0;
BA_ "NetworkRequestHoldingTime" SG_ 348 DSAU_BolsterDefDis 5000;
BA_ "Version" SG_ 348 DSAU_BolsterDefDis "19.11.06";
BA_ "GenMsgSendType" BO_ 349 0;
BA_ "Description" SG_ 349 DSAU_CushInfDis "DSAU_CushionInflationDisplay";
BA_ "GenSigSendType" SG_ 349 DSAU_CushInfDis 4;
BA_ "UserSigValidity" SG_ 349 DSAU_CushInfDis 3;
BA_REL_ "GenSigTimeoutTime" BU_SG_REL_ DPSS SG_ 349 DSAU_CushInfDis 1500;
BA_REL_ "GenSigTimeoutTime" BU_SG_REL_ CGW_CCU SG_ 349 DSAU_CushInfDis 1500;
BA_ "NetworkRequest" SG_ 349 DSAU_CushInfDis 0;
BA_ "NetworkRequestHoldingTime" SG_ 349 DSAU_CushInfDis 5000;
BA_ "Version" SG_ 349 DSAU_CushInfDis "19.11.06";
BA_ "Description" SG_ 349 DSAU_CushDefDis "DSAU_CushionDeflationDisplay";
BA_ "GenSigSendType" SG_ 349 DSAU_CushDefDis 4;
BA_ "UserSigValidity" SG_ 349 DSAU_CushDefDis 3;
BA_REL_ "GenSigTimeoutTime" BU_SG_REL_ DPSS SG_ 349 DSAU_CushDefDis 1500;
BA_REL_ "GenSigTimeoutTime" BU_SG_REL_ CGW_CCU SG_ 349 DSAU_CushDefDis 1500;
BA_ "NetworkRequest" SG_ 349 DSAU_CushDefDis 0;
BA_ "NetworkRequestHoldingTime" SG_ 349 DSAU_CushDefDis 5000;
BA_ "Version" SG_ 349 DSAU_CushDefDis "19.11.06";
BA_ "GenMsgSendType" BO_ 350 0;
BA_ "Description" SG_ 350 DSAU_AirSptTimeRValueSet "Air Support Time(Massage Time) USM R Value";
BA_ "GenSigSendType" SG_ 350 DSAU_AirSptTimeRValueSet 4;
BA_ "UserSigValidity" SG_ 350 DSAU_AirSptTimeRValueSet 3;
BA_REL_ "GenSigTimeoutTime" BU_SG_REL_ CGW_CCU SG_ 350 DSAU_AirSptTimeRValueSet 1500;
BA_ "NetworkRequest" SG_ 350 DSAU_AirSptTimeRValueSet 0;
BA_ "NetworkRequestHoldingTime" SG_ 350 DSAU_AirSptTimeRValueSet 5000;
BA_ "Version" SG_ 350 DSAU_AirSptTimeRValueSet "19.11.06";
BA_ "Description" SG_ 350 DSAU_DrvPostureAssistRValueSet "Drive Seat Posture Assist Function USM R Value";
BA_ "GenSigSendType" SG_ 350 DSAU_DrvPostureAssistRValueSet 4;
BA_ "UserSigValidity" SG_ 350 DSAU_DrvPostureAssistRValueSet 3;
BA_REL_ "GenSigTimeoutTime" BU_SG_REL_ CGW_CCU SG_ 350 DSAU_DrvPostureAssistRValueSet 1500;
BA_ "NetworkRequest" SG_ 350 DSAU_DrvPostureAssistRValueSet 0;
BA_ "NetworkRequestHoldingTime" SG_ 350 DSAU_DrvPostureAssistRValueSet 5000;
BA_ "Version" SG_ 350 DSAU_DrvPostureAssistRValueSet "19.11.06";
BA_ "Description" SG_ 350 DSAU_DrvSmtAirSptRValueSet "Seat Smart Air Support Function USM R Value";
BA_ "GenSigSendType" SG_ 350 DSAU_DrvSmtAirSptRValueSet 4;
BA_ "UserSigValidity" SG_ 350 DSAU_DrvSmtAirSptRValueSet 3;
BA_REL_ "GenSigTimeoutTime" BU_SG_REL_ CGW_CCU SG_ 350 DSAU_DrvSmtAirSptRValueSet 1500;
BA_ "NetworkRequest" SG_ 350 DSAU_DrvSmtAirSptRValueSet 0;
BA_ "NetworkRequestHoldingTime" SG_ 350 DSAU_DrvSmtAirSptRValueSet 5000;
BA_ "Version" SG_ 350 DSAU_DrvSmtAirSptRValueSet "19.12.00";
BA_ "Description" SG_ 350 DSAU_DrvSmtSptRValueSet "Seat Smart Support Function USM R Value";
BA_ "GenSigSendType" SG_ 350 DSAU_DrvSmtSptRValueSet 4;
BA_ "UserSigValidity" SG_ 350 DSAU_DrvSmtSptRValueSet 3;
BA_REL_ "GenSigTimeoutTime" BU_SG_REL_ CGW_CCU SG_ 350 DSAU_DrvSmtSptRValueSet 1500;
BA_ "NetworkRequest" SG_ 350 DSAU_DrvSmtSptRValueSet 0;
BA_ "NetworkRequestHoldingTime" SG_ 350 DSAU_DrvSmtSptRValueSet 5000;
BA_ "Version" SG_ 350 DSAU_DrvSmtSptRValueSet "19.12.01";
BA_ "Description" SG_ 350 DSAU_DrvPostureAssistDis "Seat Body Support Function Display Request";
BA_ "GenSigSendType" SG_ 350 DSAU_DrvPostureAssistDis 4;
BA_ "UserSigValidity" SG_ 350 DSAU_DrvPostureAssistDis 1;
BA_REL_ "GenSigTimeoutTime" BU_SG_REL_ CGW_CCU SG_ 350 DSAU_DrvPostureAssistDis 1500;
BA_ "Version" SG_ 350 DSAU_DrvPostureAssistDis "21.07.07";
BA_ "Description" SG_ 350 DSAU_CushSoftRValueSet "Cushion Soft R Value";
BA_ "GenSigSendType" SG_ 350 DSAU_CushSoftRValueSet 4;
BA_ "UserSigValidity" SG_ 350 DSAU_CushSoftRValueSet 3;
BA_REL_ "GenSigTimeoutTime" BU_SG_REL_ CGW_CCU SG_ 350 DSAU_CushSoftRValueSet 1500;
BA_ "NetworkRequest" SG_ 350 DSAU_CushSoftRValueSet 0;
BA_ "NetworkRequestHoldingTime" SG_ 350 DSAU_CushSoftRValueSet 5000;
BA_ "Version" SG_ 350 DSAU_CushSoftRValueSet "20.04.02";
BA_ "Description" SG_ 350 DSAU_BackSoftRValueSet "Back Soft USM R Value";
BA_ "GenSigSendType" SG_ 350 DSAU_BackSoftRValueSet 4;
BA_ "UserSigValidity" SG_ 350 DSAU_BackSoftRValueSet 3;
BA_REL_ "GenSigTimeoutTime" BU_SG_REL_ CGW_CCU SG_ 350 DSAU_BackSoftRValueSet 1500;
BA_ "NetworkRequest" SG_ 350 DSAU_BackSoftRValueSet 0;
BA_ "NetworkRequestHoldingTime" SG_ 350 DSAU_BackSoftRValueSet 5000;
BA_ "Version" SG_ 350 DSAU_BackSoftRValueSet "20.04.02";
BA_ "Description" SG_ 350 DSAU_AirSptModeRValueSet "Air Support Mode(Massage Mode) USM R Value";
BA_ "GenSigSendType" SG_ 350 DSAU_AirSptModeRValueSet 4;
BA_ "UserSigValidity" SG_ 350 DSAU_AirSptModeRValueSet 3;
BA_REL_ "GenSigTimeoutTime" BU_SG_REL_ CGW_CCU SG_ 350 DSAU_AirSptModeRValueSet 1500;
BA_ "NetworkRequest" SG_ 350 DSAU_AirSptModeRValueSet 0;
BA_ "NetworkRequestHoldingTime" SG_ 350 DSAU_AirSptModeRValueSet 5000;
BA_ "Version" SG_ 350 DSAU_AirSptModeRValueSet "19.11.06";
BA_ "Description" SG_ 350 DSAU_MsgModeSts "Air Support Mode Function Operating Display";
BA_ "GenSigSendType" SG_ 350 DSAU_MsgModeSts 4;
BA_ "UserSigValidity" SG_ 350 DSAU_MsgModeSts 3;
BA_REL_ "GenSigTimeoutTime" BU_SG_REL_ CGW_CCU SG_ 350 DSAU_MsgModeSts 1500;
BA_ "NetworkRequest" SG_ 350 DSAU_MsgModeSts 0;
BA_ "NetworkRequestHoldingTime" SG_ 350 DSAU_MsgModeSts 5000;
BA_ "Version" SG_ 350 DSAU_MsgModeSts "20.04.02";
BA_ "Description" SG_ 350 DSAU_MsgModeStrength "Air Support intensity regulation(Massage Strenth)";
BA_ "GenSigSendType" SG_ 350 DSAU_MsgModeStrength 4;
BA_ "UserSigValidity" SG_ 350 DSAU_MsgModeStrength 3;
BA_REL_ "GenSigTimeoutTime" BU_SG_REL_ CGW_CCU SG_ 350 DSAU_MsgModeStrength 1500;
BA_ "NetworkRequest" SG_ 350 DSAU_MsgModeStrength 0;
BA_ "NetworkRequestHoldingTime" SG_ 350 DSAU_MsgModeStrength 5000;
BA_ "Version" SG_ 350 DSAU_MsgModeStrength "19.12.01";
BA_ "Description" SG_ 350 DSAU_MoodTrpyRValueSet "Drive Seat Mood Therapy R Value";
BA_ "GenSigSendType" SG_ 350 DSAU_MoodTrpyRValueSet 4;
BA_ "UserSigValidity" SG_ 350 DSAU_MoodTrpyRValueSet 3;
BA_REL_ "GenSigTimeoutTime" BU_SG_REL_ CGW_CCU SG_ 350 DSAU_MoodTrpyRValueSet 1500;
BA_ "NetworkRequest" SG_ 350 DSAU_MoodTrpyRValueSet 0;
BA_ "NetworkRequestHoldingTime" SG_ 350 DSAU_MoodTrpyRValueSet 5000;
BA_ "Version" SG_ 350 DSAU_MoodTrpyRValueSet "20.07.03";
BA_ "Description" SG_ 350 DSAU_MoodTrpyCareSta "Drive Seat Mood Therapy Care Mode R Value";
BA_ "GenSigSendType" SG_ 350 DSAU_MoodTrpyCareSta 4;
BA_ "UserSigValidity" SG_ 350 DSAU_MoodTrpyCareSta 3;
BA_REL_ "GenSigTimeoutTime" BU_SG_REL_ CGW_CCU SG_ 350 DSAU_MoodTrpyCareSta 1500;
BA_ "NetworkRequest" SG_ 350 DSAU_MoodTrpyCareSta 0;
BA_ "NetworkRequestHoldingTime" SG_ 350 DSAU_MoodTrpyCareSta 5000;
BA_ "Version" SG_ 350 DSAU_MoodTrpyCareSta "20.07.12";
BA_ "Description" SG_ 350 DSAU_MoodTrpyComfSta "Drive Seat Mood Therapy Comfort Mode R Value";
BA_ "GenSigSendType" SG_ 350 DSAU_MoodTrpyComfSta 4;
BA_ "UserSigValidity" SG_ 350 DSAU_MoodTrpyComfSta 3;
BA_REL_ "GenSigTimeoutTime" BU_SG_REL_ CGW_CCU SG_ 350 DSAU_MoodTrpyComfSta 1500;
BA_ "NetworkRequest" SG_ 350 DSAU_MoodTrpyComfSta 0;
BA_ "NetworkRequestHoldingTime" SG_ 350 DSAU_MoodTrpyComfSta 5000;
BA_ "Version" SG_ 350 DSAU_MoodTrpyComfSta "20.07.12";
BA_ "Description" SG_ 350 DASU_AirSptStrRValueSet "Air Support Strenth(Massage Strenth) USM R Value";
BA_ "GenSigSendType" SG_ 350 DASU_AirSptStrRValueSet 4;
BA_ "UserSigValidity" SG_ 350 DASU_AirSptStrRValueSet 3;
BA_REL_ "GenSigTimeoutTime" BU_SG_REL_ CGW_CCU SG_ 350 DASU_AirSptStrRValueSet 1500;
BA_ "NetworkRequest" SG_ 350 DASU_AirSptStrRValueSet 0;
BA_ "NetworkRequestHoldingTime" SG_ 350 DASU_AirSptStrRValueSet 5000;
BA_ "Version" SG_ 350 DASU_AirSptStrRValueSet "20.07.11";
BA_ "GenMsgSendType" BO_ 2407787009 0;
BA_ "VFrameFormat" BO_ 2407787009 1;
BA_ "Description" SG_ 2407787009 DVRS_Rec_Crash "18.11.06_";
BA_ "GenSigSendType" SG_ 2407787009 DVRS_Rec_Crash 4;
BA_ "GenSigStartValue" SG_ 2407787009 DVRS_Rec_Crash 3;
BA_ "UserSigValidity" SG_ 2407787009 DVRS_Rec_Crash 1;
BA_ "Version" SG_ 2407787009 DVRS_Rec_Crash "18.12.06";
BA_ "Description" SG_ 2407787009 DVRS_Rec_Normal_Prk "18.11.04_";
BA_ "GenSigSendType" SG_ 2407787009 DVRS_Rec_Normal_Prk 4;
BA_ "GenSigStartValue" SG_ 2407787009 DVRS_Rec_Normal_Prk 3;
BA_ "UserSigValidity" SG_ 2407787009 DVRS_Rec_Normal_Prk 0;
BA_ "Version" SG_ 2407787009 DVRS_Rec_Normal_Prk "18.12.06";
BA_ "Description" SG_ 2407787009 DVRS_Timelapse "18.07.03_";
BA_ "GenSigSendType" SG_ 2407787009 DVRS_Timelapse 4;
BA_ "GenSigStartValue" SG_ 2407787009 DVRS_Timelapse 3;
BA_ "UserSigValidity" SG_ 2407787009 DVRS_Timelapse 1;
BA_ "Version" SG_ 2407787009 DVRS_Timelapse "18.12.06";
BA_ "Description" SG_ 2407787009 DVRS_Rec_Manual "18.07.03_";
BA_ "GenSigSendType" SG_ 2407787009 DVRS_Rec_Manual 4;
BA_ "GenSigStartValue" SG_ 2407787009 DVRS_Rec_Manual 3;
BA_ "UserSigValidity" SG_ 2407787009 DVRS_Rec_Manual 1;
BA_ "Version" SG_ 2407787009 DVRS_Rec_Manual "18.12.06";
BA_ "GenSigSendType" SG_ 2407787009 DVRS_Prk_time 4;
BA_ "GenSigStartValue" SG_ 2407787009 DVRS_Prk_time 255;
BA_ "UserSigValidity" SG_ 2407787009 DVRS_Prk_time 0;
BA_ "Version" SG_ 2407787009 DVRS_Prk_time "19.12.07";
BA_ "Description" SG_ 2407787009 DVRS_Rec_Normal "18.07.03_";
BA_ "GenSigSendType" SG_ 2407787009 DVRS_Rec_Normal 4;
BA_ "GenSigStartValue" SG_ 2407787009 DVRS_Rec_Normal 3;
BA_ "UserSigValidity" SG_ 2407787009 DVRS_Rec_Normal 1;
BA_ "Version" SG_ 2407787009 DVRS_Rec_Normal "18.12.06";
BA_ "GenSigSendType" SG_ 2407787009 DVRS_Prk_Crash_Event_Count 4;
BA_ "GenSigStartValue" SG_ 2407787009 DVRS_Prk_Crash_Event_Count 255;
BA_ "UserSigValidity" SG_ 2407787009 DVRS_Prk_Crash_Event_Count 0;
BA_ "Version" SG_ 2407787009 DVRS_Prk_Crash_Event_Count "19.12.07";
BA_ "Description" SG_ 2407787009 DVRS_Status "18.08.16_";
BA_ "GenSigSendType" SG_ 2407787009 DVRS_Status 4;
BA_ "UserSigValidity" SG_ 2407787009 DVRS_Status 1;
BA_ "Version" SG_ 2407787009 DVRS_Status "18.12.06";
BA_ "Description" SG_ 2407787009 DVRS_Event_Sound "18.07.03_";
BA_ "GenSigSendType" SG_ 2407787009 DVRS_Event_Sound 4;
BA_ "GenSigStartValue" SG_ 2407787009 DVRS_Event_Sound 3;
BA_ "UserSigValidity" SG_ 2407787009 DVRS_Event_Sound 1;
BA_ "Version" SG_ 2407787009 DVRS_Event_Sound "18.12.06";
BA_ "Description" SG_ 2407787009 DVRS_BeepSound "Beep Trigger signal when DVRS screen on AVN

0x1 : normal trigger

0x2 : Keyboard trigger only";
BA_ "GenSigSendType" SG_ 2407787009 DVRS_BeepSound 4;
BA_ "GenSigStartValue" SG_ 2407787009 DVRS_BeepSound 3;
BA_ "UserSigValidity" SG_ 2407787009 DVRS_BeepSound 1;
BA_REL_ "GenSigTimeoutTime" BU_SG_REL_ AMP SG_ 2407787009 DVRS_BeepSound 1500;
BA_ "Version" SG_ 2407787009 DVRS_BeepSound "20.06.12";
BA_ "Description" SG_ 2407787009 DVRS_Display "This signal means whether to display Built-in Cam or AVN mode in AVN screen.";
BA_ "GenSigSendType" SG_ 2407787009 DVRS_Display 4;
BA_ "GenSigStartValue" SG_ 2407787009 DVRS_Display 15;
BA_ "UserSigValidity" SG_ 2407787009 DVRS_Display 1;
BA_ "Version" SG_ 2407787009 DVRS_Display "21.05.05";
BA_ "Description" SG_ 2407787009 BLTN_CAM_UpdateSWType "BLTN_CAM Update SW Type";
BA_ "GenSigSendType" SG_ 2407787009 BLTN_CAM_UpdateSWType 4;
BA_ "UserSigValidity" SG_ 2407787009 BLTN_CAM_UpdateSWType 1;
BA_ "Version" SG_ 2407787009 BLTN_CAM_UpdateSWType "21.03.01";
BA_ "Description" SG_ 2407787009 DVRS_I2CMasterSta "This signal indicates Status of I2C Master.



0x0:Built-in Cam has control over I2C channel

0x1:ADAS_PRK has control over I2C channel

0x2:Configure Failed

0x3:Invalid";
BA_ "GenSigSendType" SG_ 2407787009 DVRS_I2CMasterSta 4;
BA_ "UserSigValidity" SG_ 2407787009 DVRS_I2CMasterSta 0;
BA_ "Version" SG_ 2407787009 DVRS_I2CMasterSta "20.10.00";
BA_ "Description" SG_ 2407787009 DVRS_CamSta "This signal indicates Status of Rear Camera.";
BA_ "GenSigSendType" SG_ 2407787009 DVRS_CamSta 4;
BA_ "UserSigValidity" SG_ 2407787009 DVRS_CamSta 0;
BA_ "Version" SG_ 2407787009 DVRS_CamSta "19.11.05";
BA_ "Description" SG_ 2407787009 DVRS_RecSet_Normal "FRS Setting for DVRS, DVRS_RecSet_Normal";
BA_ "GenSigSendType" SG_ 2407787009 DVRS_RecSet_Normal 4;
BA_ "UserSigValidity" SG_ 2407787009 DVRS_RecSet_Normal 1;
BA_ "Version" SG_ 2407787009 DVRS_RecSet_Normal "20.11.02";
BA_ "Description" SG_ 2407787009 DVRS_RecSet_Crash "FRS Setting for DVRS, DVRS_RecSet_Crash";
BA_ "GenSigSendType" SG_ 2407787009 DVRS_RecSet_Crash 4;
BA_ "UserSigValidity" SG_ 2407787009 DVRS_RecSet_Crash 1;
BA_ "Version" SG_ 2407787009 DVRS_RecSet_Crash "20.11.02";
BA_ "Description" SG_ 2407787009 DVRS_RecSet_Normal_Prk "FRS Setting for DVRS, DVRS_RecSet_Normal_Prk";
BA_ "GenSigSendType" SG_ 2407787009 DVRS_RecSet_Normal_Prk 4;
BA_ "UserSigValidity" SG_ 2407787009 DVRS_RecSet_Normal_Prk 1;
BA_ "Version" SG_ 2407787009 DVRS_RecSet_Normal_Prk "20.11.02";
BA_ "Description" SG_ 2407787009 DVRS_RecSet_Crash_Prk "FRS Setting for DVRS, DVRS_RecSet_Crash_Prk";
BA_ "GenSigSendType" SG_ 2407787009 DVRS_RecSet_Crash_Prk 4;
BA_ "UserSigValidity" SG_ 2407787009 DVRS_RecSet_Crash_Prk 1;
BA_ "Version" SG_ 2407787009 DVRS_RecSet_Crash_Prk "20.11.02";
BA_ "GenSigSendType" SG_ 2407787009 DVRS_Rec_Crash_Prk 4;
BA_ "GenSigStartValue" SG_ 2407787009 DVRS_Rec_Crash_Prk 3;
BA_ "UserSigValidity" SG_ 2407787009 DVRS_Rec_Crash_Prk 0;
BA_ "Version" SG_ 2407787009 DVRS_Rec_Crash_Prk "19.06.02";
BA_ "GenMsgCycleTime" BO_ 319 0;
BA_ "Description" SG_ 319 FPM_Random "Random number";
BA_ "GenSigSendType" SG_ 319 FPM_Random 4;
BA_ "UserSigValidity" SG_ 319 FPM_Random 0;
BA_REL_ "GenSigTimeoutTime" BU_SG_REL_ CGW_CCU SG_ 319 FPM_Random 0;
BA_ "Version" SG_ 319 FPM_Random "21.07.05";
BA_ "GenMsgCycleTime" BO_ 335 0;
BA_ "Description" SG_ 335 FPM_Encrypted_Result1 "encrypted result of FPM";
BA_ "GenSigSendType" SG_ 335 FPM_Encrypted_Result1 4;
BA_ "UserSigValidity" SG_ 335 FPM_Encrypted_Result1 0;
BA_REL_ "GenSigTimeoutTime" BU_SG_REL_ CGW_CCU SG_ 335 FPM_Encrypted_Result1 0;
BA_ "Version" SG_ 335 FPM_Encrypted_Result1 "21.07.05";
BA_ "GenMsgCycleTime" BO_ 351 0;
BA_ "Description" SG_ 351 FPM_Encrypted_Result2 "enrypted result of FPM";
BA_ "GenSigSendType" SG_ 351 FPM_Encrypted_Result2 4;
BA_ "UserSigValidity" SG_ 351 FPM_Encrypted_Result2 0;
BA_REL_ "GenSigTimeoutTime" BU_SG_REL_ CGW_CCU SG_ 351 FPM_Encrypted_Result2 0;
BA_ "Version" SG_ 351 FPM_Encrypted_Result2 "21.07.05";
BA_ "GenMsgCycleTime" BO_ 1873 0;
BA_ "GenMsgCycleTimeFast" BO_ 1873 0;
BA_ "GenMsgNrOfRepetition" BO_ 1873 0;
BA_ "DiagRequest" BO_ 1873 1;
BA_ "GenMsgILSupport" BO_ 1873 0;
BA_ "TpMessage" BO_ 1873 1;
BA_ "TpTxIndex" BO_ 1873 122;
BA_ "Description" SG_ 1873 GST_DPSS_Byte0 "TP Index : 122";
BA_ "UsrSigPurpose" SG_ 1873 GST_DPSS_Byte0 3;
BA_ "UserSigValidity" SG_ 1873 GST_DPSS_Byte0 0;
BA_REL_ "GenSigTimeoutTime" BU_SG_REL_ DPSS SG_ 1873 GST_DPSS_Byte0 0;
BA_REL_ "GenSigTimeoutTime" BU_SG_REL_ vHS_M SG_ 1873 GST_DPSS_Byte0 0;
BA_ "NetworkRequest" SG_ 1873 GST_DPSS_Byte0 0;
BA_ "NetworkRequestHoldingTime" SG_ 1873 GST_DPSS_Byte0 5000;
BA_ "Version" SG_ 1873 GST_DPSS_Byte0 "21.02.04";
BA_ "Description" SG_ 1873 GST_DPSS_Byte2 "TP Index : 122";
BA_ "UsrSigPurpose" SG_ 1873 GST_DPSS_Byte2 3;
BA_ "UserSigValidity" SG_ 1873 GST_DPSS_Byte2 0;
BA_REL_ "GenSigTimeoutTime" BU_SG_REL_ DPSS SG_ 1873 GST_DPSS_Byte2 0;
BA_REL_ "GenSigTimeoutTime" BU_SG_REL_ vHS_M SG_ 1873 GST_DPSS_Byte2 0;
BA_ "NetworkRequest" SG_ 1873 GST_DPSS_Byte2 0;
BA_ "NetworkRequestHoldingTime" SG_ 1873 GST_DPSS_Byte2 5000;
BA_ "Version" SG_ 1873 GST_DPSS_Byte2 "21.02.04";
BA_ "Description" SG_ 1873 GST_DPSS_Byte3 "TP Index : 122";
BA_ "UsrSigPurpose" SG_ 1873 GST_DPSS_Byte3 3;
BA_ "UserSigValidity" SG_ 1873 GST_DPSS_Byte3 0;
BA_REL_ "GenSigTimeoutTime" BU_SG_REL_ DPSS SG_ 1873 GST_DPSS_Byte3 0;
BA_REL_ "GenSigTimeoutTime" BU_SG_REL_ vHS_M SG_ 1873 GST_DPSS_Byte3 0;
BA_ "NetworkRequest" SG_ 1873 GST_DPSS_Byte3 0;
BA_ "NetworkRequestHoldingTime" SG_ 1873 GST_DPSS_Byte3 5000;
BA_ "Version" SG_ 1873 GST_DPSS_Byte3 "21.02.04";
BA_ "Description" SG_ 1873 GST_DPSS_Byte4 "TP Index : 122";
BA_ "UsrSigPurpose" SG_ 1873 GST_DPSS_Byte4 3;
BA_ "UserSigValidity" SG_ 1873 GST_DPSS_Byte4 0;
BA_REL_ "GenSigTimeoutTime" BU_SG_REL_ DPSS SG_ 1873 GST_DPSS_Byte4 0;
BA_REL_ "GenSigTimeoutTime" BU_SG_REL_ vHS_M SG_ 1873 GST_DPSS_Byte4 0;
BA_ "NetworkRequest" SG_ 1873 GST_DPSS_Byte4 0;
BA_ "NetworkRequestHoldingTime" SG_ 1873 GST_DPSS_Byte4 5000;
BA_ "Version" SG_ 1873 GST_DPSS_Byte4 "21.02.04";
BA_ "Description" SG_ 1873 GST_DPSS_Byte5 "TP Index : 122";
BA_ "UsrSigPurpose" SG_ 1873 GST_DPSS_Byte5 3;
BA_ "UserSigValidity" SG_ 1873 GST_DPSS_Byte5 0;
BA_REL_ "GenSigTimeoutTime" BU_SG_REL_ DPSS SG_ 1873 GST_DPSS_Byte5 0;
BA_REL_ "GenSigTimeoutTime" BU_SG_REL_ vHS_M SG_ 1873 GST_DPSS_Byte5 0;
BA_ "NetworkRequest" SG_ 1873 GST_DPSS_Byte5 0;
BA_ "NetworkRequestHoldingTime" SG_ 1873 GST_DPSS_Byte5 5000;
BA_ "Version" SG_ 1873 GST_DPSS_Byte5 "21.02.04";
BA_ "Description" SG_ 1873 GST_DPSS_Byte6 "TP Index : 122";
BA_ "UsrSigPurpose" SG_ 1873 GST_DPSS_Byte6 3;
BA_ "UserSigValidity" SG_ 1873 GST_DPSS_Byte6 0;
BA_REL_ "GenSigTimeoutTime" BU_SG_REL_ DPSS SG_ 1873 GST_DPSS_Byte6 0;
BA_REL_ "GenSigTimeoutTime" BU_SG_REL_ vHS_M SG_ 1873 GST_DPSS_Byte6 0;
BA_ "NetworkRequest" SG_ 1873 GST_DPSS_Byte6 0;
BA_ "NetworkRequestHoldingTime" SG_ 1873 GST_DPSS_Byte6 5000;
BA_ "Version" SG_ 1873 GST_DPSS_Byte6 "21.02.04";
BA_ "Description" SG_ 1873 GST_DPSS_Byte7 "TP Index : 122";
BA_ "UsrSigPurpose" SG_ 1873 GST_DPSS_Byte7 3;
BA_ "UserSigValidity" SG_ 1873 GST_DPSS_Byte7 0;
BA_REL_ "GenSigTimeoutTime" BU_SG_REL_ DPSS SG_ 1873 GST_DPSS_Byte7 0;
BA_REL_ "GenSigTimeoutTime" BU_SG_REL_ vHS_M SG_ 1873 GST_DPSS_Byte7 0;
BA_ "NetworkRequest" SG_ 1873 GST_DPSS_Byte7 0;
BA_ "NetworkRequestHoldingTime" SG_ 1873 GST_DPSS_Byte7 5000;
BA_ "Version" SG_ 1873 GST_DPSS_Byte7 "21.02.04";
BA_ "Description" SG_ 1873 GST_DPSS_Byte1 "TP Index : 122";
BA_ "UsrSigPurpose" SG_ 1873 GST_DPSS_Byte1 3;
BA_ "UserSigValidity" SG_ 1873 GST_DPSS_Byte1 0;
BA_REL_ "GenSigTimeoutTime" BU_SG_REL_ DPSS SG_ 1873 GST_DPSS_Byte1 0;
BA_REL_ "GenSigTimeoutTime" BU_SG_REL_ vHS_M SG_ 1873 GST_DPSS_Byte1 0;
BA_ "NetworkRequest" SG_ 1873 GST_DPSS_Byte1 0;
BA_ "NetworkRequestHoldingTime" SG_ 1873 GST_DPSS_Byte1 5000;
BA_ "Version" SG_ 1873 GST_DPSS_Byte1 "21.02.04";
BA_ "GenMsgCycleTime" BO_ 1842 0;
BA_ "GenMsgCycleTimeFast" BO_ 1842 0;
BA_ "GenMsgNrOfRepetition" BO_ 1842 0;
BA_ "DiagRequest" BO_ 1842 1;
BA_ "GenMsgILSupport" BO_ 1842 0;
BA_ "TpMessage" BO_ 1842 1;
BA_ "TpTxIndex" BO_ 1842 161;
BA_ "Description" SG_ 1842 GST_RLPSU_Byte0 "TP Index : 161";
BA_ "UsrSigPurpose" SG_ 1842 GST_RLPSU_Byte0 3;
BA_ "UserSigValidity" SG_ 1842 GST_RLPSU_Byte0 0;
BA_REL_ "GenSigTimeoutTime" BU_SG_REL_ RLPSM SG_ 1842 GST_RLPSU_Byte0 0;
BA_REL_ "GenSigTimeoutTime" BU_SG_REL_ vHS_M SG_ 1842 GST_RLPSU_Byte0 0;
BA_ "NetworkRequest" SG_ 1842 GST_RLPSU_Byte0 0;
BA_ "NetworkRequestHoldingTime" SG_ 1842 GST_RLPSU_Byte0 5000;
BA_ "Version" SG_ 1842 GST_RLPSU_Byte0 "21.02.04";
BA_ "Description" SG_ 1842 GST_RLPSU_Byte2 "TP Index : 161";
BA_ "UsrSigPurpose" SG_ 1842 GST_RLPSU_Byte2 3;
BA_ "UserSigValidity" SG_ 1842 GST_RLPSU_Byte2 0;
BA_REL_ "GenSigTimeoutTime" BU_SG_REL_ RLPSM SG_ 1842 GST_RLPSU_Byte2 0;
BA_REL_ "GenSigTimeoutTime" BU_SG_REL_ vHS_M SG_ 1842 GST_RLPSU_Byte2 0;
BA_ "NetworkRequest" SG_ 1842 GST_RLPSU_Byte2 0;
BA_ "NetworkRequestHoldingTime" SG_ 1842 GST_RLPSU_Byte2 5000;
BA_ "Version" SG_ 1842 GST_RLPSU_Byte2 "21.02.04";
BA_ "Description" SG_ 1842 GST_RLPSU_Byte3 "TP Index : 161";
BA_ "UsrSigPurpose" SG_ 1842 GST_RLPSU_Byte3 3;
BA_ "UserSigValidity" SG_ 1842 GST_RLPSU_Byte3 0;
BA_REL_ "GenSigTimeoutTime" BU_SG_REL_ RLPSM SG_ 1842 GST_RLPSU_Byte3 0;
BA_REL_ "GenSigTimeoutTime" BU_SG_REL_ vHS_M SG_ 1842 GST_RLPSU_Byte3 0;
BA_ "NetworkRequest" SG_ 1842 GST_RLPSU_Byte3 0;
BA_ "NetworkRequestHoldingTime" SG_ 1842 GST_RLPSU_Byte3 5000;
BA_ "Version" SG_ 1842 GST_RLPSU_Byte3 "21.02.04";
BA_ "Description" SG_ 1842 GST_RLPSU_Byte4 "TP Index : 161";
BA_ "UsrSigPurpose" SG_ 1842 GST_RLPSU_Byte4 3;
BA_ "UserSigValidity" SG_ 1842 GST_RLPSU_Byte4 0;
BA_REL_ "GenSigTimeoutTime" BU_SG_REL_ RLPSM SG_ 1842 GST_RLPSU_Byte4 0;
BA_REL_ "GenSigTimeoutTime" BU_SG_REL_ vHS_M SG_ 1842 GST_RLPSU_Byte4 0;
BA_ "NetworkRequest" SG_ 1842 GST_RLPSU_Byte4 0;
BA_ "NetworkRequestHoldingTime" SG_ 1842 GST_RLPSU_Byte4 5000;
BA_ "Version" SG_ 1842 GST_RLPSU_Byte4 "21.02.04";
BA_ "Description" SG_ 1842 GST_RLPSU_Byte5 "TP Index : 161";
BA_ "UsrSigPurpose" SG_ 1842 GST_RLPSU_Byte5 3;
BA_ "UserSigValidity" SG_ 1842 GST_RLPSU_Byte5 0;
BA_REL_ "GenSigTimeoutTime" BU_SG_REL_ RLPSM SG_ 1842 GST_RLPSU_Byte5 0;
BA_REL_ "GenSigTimeoutTime" BU_SG_REL_ vHS_M SG_ 1842 GST_RLPSU_Byte5 0;
BA_ "NetworkRequest" SG_ 1842 GST_RLPSU_Byte5 0;
BA_ "NetworkRequestHoldingTime" SG_ 1842 GST_RLPSU_Byte5 5000;
BA_ "Version" SG_ 1842 GST_RLPSU_Byte5 "21.02.04";
BA_ "Description" SG_ 1842 GST_RLPSU_Byte6 "TP Index : 161";
BA_ "UsrSigPurpose" SG_ 1842 GST_RLPSU_Byte6 3;
BA_ "UserSigValidity" SG_ 1842 GST_RLPSU_Byte6 0;
BA_REL_ "GenSigTimeoutTime" BU_SG_REL_ RLPSM SG_ 1842 GST_RLPSU_Byte6 0;
BA_REL_ "GenSigTimeoutTime" BU_SG_REL_ vHS_M SG_ 1842 GST_RLPSU_Byte6 0;
BA_ "NetworkRequest" SG_ 1842 GST_RLPSU_Byte6 0;
BA_ "NetworkRequestHoldingTime" SG_ 1842 GST_RLPSU_Byte6 5000;
BA_ "Version" SG_ 1842 GST_RLPSU_Byte6 "21.02.04";
BA_ "Description" SG_ 1842 GST_RLPSU_Byte7 "TP Index : 161";
BA_ "UsrSigPurpose" SG_ 1842 GST_RLPSU_Byte7 3;
BA_ "UserSigValidity" SG_ 1842 GST_RLPSU_Byte7 0;
BA_REL_ "GenSigTimeoutTime" BU_SG_REL_ RLPSM SG_ 1842 GST_RLPSU_Byte7 0;
BA_REL_ "GenSigTimeoutTime" BU_SG_REL_ vHS_M SG_ 1842 GST_RLPSU_Byte7 0;
BA_ "NetworkRequest" SG_ 1842 GST_RLPSU_Byte7 0;
BA_ "NetworkRequestHoldingTime" SG_ 1842 GST_RLPSU_Byte7 5000;
BA_ "Version" SG_ 1842 GST_RLPSU_Byte7 "21.02.04";
BA_ "Description" SG_ 1842 GST_RLPSU_Byte1 "TP Index : 161";
BA_ "UsrSigPurpose" SG_ 1842 GST_RLPSU_Byte1 3;
BA_ "UserSigValidity" SG_ 1842 GST_RLPSU_Byte1 0;
BA_REL_ "GenSigTimeoutTime" BU_SG_REL_ RLPSM SG_ 1842 GST_RLPSU_Byte1 0;
BA_REL_ "GenSigTimeoutTime" BU_SG_REL_ vHS_M SG_ 1842 GST_RLPSU_Byte1 0;
BA_ "NetworkRequest" SG_ 1842 GST_RLPSU_Byte1 0;
BA_ "NetworkRequestHoldingTime" SG_ 1842 GST_RLPSU_Byte1 5000;
BA_ "Version" SG_ 1842 GST_RLPSU_Byte1 "21.02.04";
BA_ "GenMsgCycleTime" BO_ 1841 0;
BA_ "GenMsgCycleTimeFast" BO_ 1841 0;
BA_ "GenMsgNrOfRepetition" BO_ 1841 0;
BA_ "DiagRequest" BO_ 1841 1;
BA_ "GenMsgILSupport" BO_ 1841 0;
BA_ "TpMessage" BO_ 1841 1;
BA_ "TpTxIndex" BO_ 1841 166;
BA_ "Description" SG_ 1841 GST_RRPSU_Byte0 "TP Index : 166";
BA_ "UsrSigPurpose" SG_ 1841 GST_RRPSU_Byte0 3;
BA_ "UserSigValidity" SG_ 1841 GST_RRPSU_Byte0 0;
BA_REL_ "GenSigTimeoutTime" BU_SG_REL_ RRPSM SG_ 1841 GST_RRPSU_Byte0 0;
BA_REL_ "GenSigTimeoutTime" BU_SG_REL_ vHS_M SG_ 1841 GST_RRPSU_Byte0 0;
BA_ "NetworkRequest" SG_ 1841 GST_RRPSU_Byte0 0;
BA_ "NetworkRequestHoldingTime" SG_ 1841 GST_RRPSU_Byte0 5000;
BA_ "Version" SG_ 1841 GST_RRPSU_Byte0 "21.02.04";
BA_ "Description" SG_ 1841 GST_RRPSU_Byte2 "TP Index : 166";
BA_ "UsrSigPurpose" SG_ 1841 GST_RRPSU_Byte2 3;
BA_ "UserSigValidity" SG_ 1841 GST_RRPSU_Byte2 0;
BA_REL_ "GenSigTimeoutTime" BU_SG_REL_ RRPSM SG_ 1841 GST_RRPSU_Byte2 0;
BA_REL_ "GenSigTimeoutTime" BU_SG_REL_ vHS_M SG_ 1841 GST_RRPSU_Byte2 0;
BA_ "NetworkRequest" SG_ 1841 GST_RRPSU_Byte2 0;
BA_ "NetworkRequestHoldingTime" SG_ 1841 GST_RRPSU_Byte2 5000;
BA_ "Version" SG_ 1841 GST_RRPSU_Byte2 "21.02.04";
BA_ "Description" SG_ 1841 GST_RRPSU_Byte3 "TP Index : 166";
BA_ "UsrSigPurpose" SG_ 1841 GST_RRPSU_Byte3 3;
BA_ "UserSigValidity" SG_ 1841 GST_RRPSU_Byte3 0;
BA_REL_ "GenSigTimeoutTime" BU_SG_REL_ RRPSM SG_ 1841 GST_RRPSU_Byte3 0;
BA_REL_ "GenSigTimeoutTime" BU_SG_REL_ vHS_M SG_ 1841 GST_RRPSU_Byte3 0;
BA_ "NetworkRequest" SG_ 1841 GST_RRPSU_Byte3 0;
BA_ "NetworkRequestHoldingTime" SG_ 1841 GST_RRPSU_Byte3 5000;
BA_ "Version" SG_ 1841 GST_RRPSU_Byte3 "21.02.04";
BA_ "Description" SG_ 1841 GST_RRPSU_Byte4 "TP Index : 166";
BA_ "UsrSigPurpose" SG_ 1841 GST_RRPSU_Byte4 3;
BA_ "UserSigValidity" SG_ 1841 GST_RRPSU_Byte4 0;
BA_REL_ "GenSigTimeoutTime" BU_SG_REL_ RRPSM SG_ 1841 GST_RRPSU_Byte4 0;
BA_REL_ "GenSigTimeoutTime" BU_SG_REL_ vHS_M SG_ 1841 GST_RRPSU_Byte4 0;
BA_ "NetworkRequest" SG_ 1841 GST_RRPSU_Byte4 0;
BA_ "NetworkRequestHoldingTime" SG_ 1841 GST_RRPSU_Byte4 5000;
BA_ "Version" SG_ 1841 GST_RRPSU_Byte4 "21.02.04";
BA_ "Description" SG_ 1841 GST_RRPSU_Byte5 "TP Index : 166";
BA_ "UsrSigPurpose" SG_ 1841 GST_RRPSU_Byte5 3;
BA_ "UserSigValidity" SG_ 1841 GST_RRPSU_Byte5 0;
BA_REL_ "GenSigTimeoutTime" BU_SG_REL_ RRPSM SG_ 1841 GST_RRPSU_Byte5 0;
BA_REL_ "GenSigTimeoutTime" BU_SG_REL_ vHS_M SG_ 1841 GST_RRPSU_Byte5 0;
BA_ "NetworkRequest" SG_ 1841 GST_RRPSU_Byte5 0;
BA_ "NetworkRequestHoldingTime" SG_ 1841 GST_RRPSU_Byte5 5000;
BA_ "Version" SG_ 1841 GST_RRPSU_Byte5 "21.02.04";
BA_ "Description" SG_ 1841 GST_RRPSU_Byte6 "TP Index : 166";
BA_ "UsrSigPurpose" SG_ 1841 GST_RRPSU_Byte6 3;
BA_ "UserSigValidity" SG_ 1841 GST_RRPSU_Byte6 0;
BA_REL_ "GenSigTimeoutTime" BU_SG_REL_ RRPSM SG_ 1841 GST_RRPSU_Byte6 0;
BA_REL_ "GenSigTimeoutTime" BU_SG_REL_ vHS_M SG_ 1841 GST_RRPSU_Byte6 0;
BA_ "NetworkRequest" SG_ 1841 GST_RRPSU_Byte6 0;
BA_ "NetworkRequestHoldingTime" SG_ 1841 GST_RRPSU_Byte6 5000;
BA_ "Version" SG_ 1841 GST_RRPSU_Byte6 "21.02.04";
BA_ "Description" SG_ 1841 GST_RRPSU_Byte7 "TP Index : 166";
BA_ "UsrSigPurpose" SG_ 1841 GST_RRPSU_Byte7 3;
BA_ "UserSigValidity" SG_ 1841 GST_RRPSU_Byte7 0;
BA_REL_ "GenSigTimeoutTime" BU_SG_REL_ RRPSM SG_ 1841 GST_RRPSU_Byte7 0;
BA_REL_ "GenSigTimeoutTime" BU_SG_REL_ vHS_M SG_ 1841 GST_RRPSU_Byte7 0;
BA_ "NetworkRequest" SG_ 1841 GST_RRPSU_Byte7 0;
BA_ "NetworkRequestHoldingTime" SG_ 1841 GST_RRPSU_Byte7 5000;
BA_ "Version" SG_ 1841 GST_RRPSU_Byte7 "21.02.04";
BA_ "Description" SG_ 1841 GST_RRPSU_Byte1 "TP Index : 166";
BA_ "UsrSigPurpose" SG_ 1841 GST_RRPSU_Byte1 3;
BA_ "UserSigValidity" SG_ 1841 GST_RRPSU_Byte1 0;
BA_REL_ "GenSigTimeoutTime" BU_SG_REL_ RRPSM SG_ 1841 GST_RRPSU_Byte1 0;
BA_REL_ "GenSigTimeoutTime" BU_SG_REL_ vHS_M SG_ 1841 GST_RRPSU_Byte1 0;
BA_ "NetworkRequest" SG_ 1841 GST_RRPSU_Byte1 0;
BA_ "NetworkRequestHoldingTime" SG_ 1841 GST_RRPSU_Byte1 5000;
BA_ "Version" SG_ 1841 GST_RRPSU_Byte1 "21.02.04";
BA_ "GenMsgCycleTime" BO_ 1828 0;
BA_ "GenMsgCycleTimeFast" BO_ 1828 0;
BA_ "GenMsgNrOfRepetition" BO_ 1828 0;
BA_ "DiagRequest" BO_ 1828 1;
BA_ "GenMsgILSupport" BO_ 1828 0;
BA_ "TpMessage" BO_ 1828 1;
BA_ "TpTxIndex" BO_ 1828 168;
BA_ "Description" SG_ 1828 GST_RWPC_Byte0 "TP Index : 168";
BA_ "UsrSigPurpose" SG_ 1828 GST_RWPC_Byte0 3;
BA_ "UserSigValidity" SG_ 1828 GST_RWPC_Byte0 0;
BA_REL_ "GenSigTimeoutTime" BU_SG_REL_ RWPC SG_ 1828 GST_RWPC_Byte0 0;
BA_REL_ "GenSigTimeoutTime" BU_SG_REL_ vHS_M SG_ 1828 GST_RWPC_Byte0 0;
BA_ "NetworkRequest" SG_ 1828 GST_RWPC_Byte0 0;
BA_ "NetworkRequestHoldingTime" SG_ 1828 GST_RWPC_Byte0 5000;
BA_ "Version" SG_ 1828 GST_RWPC_Byte0 "21.02.04";
BA_ "Description" SG_ 1828 GST_RWPC_Byte2 "TP Index : 168";
BA_ "UsrSigPurpose" SG_ 1828 GST_RWPC_Byte2 3;
BA_ "UserSigValidity" SG_ 1828 GST_RWPC_Byte2 0;
BA_REL_ "GenSigTimeoutTime" BU_SG_REL_ RWPC SG_ 1828 GST_RWPC_Byte2 0;
BA_REL_ "GenSigTimeoutTime" BU_SG_REL_ vHS_M SG_ 1828 GST_RWPC_Byte2 0;
BA_ "NetworkRequest" SG_ 1828 GST_RWPC_Byte2 0;
BA_ "NetworkRequestHoldingTime" SG_ 1828 GST_RWPC_Byte2 5000;
BA_ "Version" SG_ 1828 GST_RWPC_Byte2 "21.02.04";
BA_ "Description" SG_ 1828 GST_RWPC_Byte3 "TP Index : 168";
BA_ "UsrSigPurpose" SG_ 1828 GST_RWPC_Byte3 3;
BA_ "UserSigValidity" SG_ 1828 GST_RWPC_Byte3 0;
BA_REL_ "GenSigTimeoutTime" BU_SG_REL_ RWPC SG_ 1828 GST_RWPC_Byte3 0;
BA_REL_ "GenSigTimeoutTime" BU_SG_REL_ vHS_M SG_ 1828 GST_RWPC_Byte3 0;
BA_ "NetworkRequest" SG_ 1828 GST_RWPC_Byte3 0;
BA_ "NetworkRequestHoldingTime" SG_ 1828 GST_RWPC_Byte3 5000;
BA_ "Version" SG_ 1828 GST_RWPC_Byte3 "21.02.04";
BA_ "Description" SG_ 1828 GST_RWPC_Byte4 "TP Index : 168";
BA_ "UsrSigPurpose" SG_ 1828 GST_RWPC_Byte4 3;
BA_ "UserSigValidity" SG_ 1828 GST_RWPC_Byte4 0;
BA_REL_ "GenSigTimeoutTime" BU_SG_REL_ RWPC SG_ 1828 GST_RWPC_Byte4 0;
BA_REL_ "GenSigTimeoutTime" BU_SG_REL_ vHS_M SG_ 1828 GST_RWPC_Byte4 0;
BA_ "NetworkRequest" SG_ 1828 GST_RWPC_Byte4 0;
BA_ "NetworkRequestHoldingTime" SG_ 1828 GST_RWPC_Byte4 5000;
BA_ "Version" SG_ 1828 GST_RWPC_Byte4 "21.02.04";
BA_ "Description" SG_ 1828 GST_RWPC_Byte5 "TP Index : 168";
BA_ "UsrSigPurpose" SG_ 1828 GST_RWPC_Byte5 3;
BA_ "UserSigValidity" SG_ 1828 GST_RWPC_Byte5 0;
BA_REL_ "GenSigTimeoutTime" BU_SG_REL_ RWPC SG_ 1828 GST_RWPC_Byte5 0;
BA_REL_ "GenSigTimeoutTime" BU_SG_REL_ vHS_M SG_ 1828 GST_RWPC_Byte5 0;
BA_ "NetworkRequest" SG_ 1828 GST_RWPC_Byte5 0;
BA_ "NetworkRequestHoldingTime" SG_ 1828 GST_RWPC_Byte5 5000;
BA_ "Version" SG_ 1828 GST_RWPC_Byte5 "21.02.04";
BA_ "Description" SG_ 1828 GST_RWPC_Byte6 "TP Index : 168";
BA_ "UsrSigPurpose" SG_ 1828 GST_RWPC_Byte6 3;
BA_ "UserSigValidity" SG_ 1828 GST_RWPC_Byte6 0;
BA_REL_ "GenSigTimeoutTime" BU_SG_REL_ RWPC SG_ 1828 GST_RWPC_Byte6 0;
BA_REL_ "GenSigTimeoutTime" BU_SG_REL_ vHS_M SG_ 1828 GST_RWPC_Byte6 0;
BA_ "NetworkRequest" SG_ 1828 GST_RWPC_Byte6 0;
BA_ "NetworkRequestHoldingTime" SG_ 1828 GST_RWPC_Byte6 5000;
BA_ "Version" SG_ 1828 GST_RWPC_Byte6 "21.02.04";
BA_ "Description" SG_ 1828 GST_RWPC_Byte7 "TP Index : 168";
BA_ "UsrSigPurpose" SG_ 1828 GST_RWPC_Byte7 3;
BA_ "UserSigValidity" SG_ 1828 GST_RWPC_Byte7 0;
BA_REL_ "GenSigTimeoutTime" BU_SG_REL_ RWPC SG_ 1828 GST_RWPC_Byte7 0;
BA_REL_ "GenSigTimeoutTime" BU_SG_REL_ vHS_M SG_ 1828 GST_RWPC_Byte7 0;
BA_ "NetworkRequest" SG_ 1828 GST_RWPC_Byte7 0;
BA_ "NetworkRequestHoldingTime" SG_ 1828 GST_RWPC_Byte7 5000;
BA_ "Version" SG_ 1828 GST_RWPC_Byte7 "21.02.04";
BA_ "Description" SG_ 1828 GST_RWPC_Byte1 "TP Index : 168";
BA_ "UsrSigPurpose" SG_ 1828 GST_RWPC_Byte1 3;
BA_ "UserSigValidity" SG_ 1828 GST_RWPC_Byte1 0;
BA_REL_ "GenSigTimeoutTime" BU_SG_REL_ RWPC SG_ 1828 GST_RWPC_Byte1 0;
BA_REL_ "GenSigTimeoutTime" BU_SG_REL_ vHS_M SG_ 1828 GST_RWPC_Byte1 0;
BA_ "NetworkRequest" SG_ 1828 GST_RWPC_Byte1 0;
BA_ "NetworkRequestHoldingTime" SG_ 1828 GST_RWPC_Byte1 5000;
BA_ "Version" SG_ 1828 GST_RWPC_Byte1 "21.02.04";
BA_ "GenMsgSendType" BO_ 2458166529 0;
BA_ "GenMsgStartDelayTime" BO_ 2458166529 80;
BA_ "VFrameFormat" BO_ 2458166529 1;
BA_ "GenSigSendType" SG_ 2458166529 C_RLUnFldSw_HU 4;
BA_ "UserSigValidity" SG_ 2458166529 C_RLUnFldSw_HU 0;
BA_ "Version" SG_ 2458166529 C_RLUnFldSw_HU "18.10.03";
BA_ "GenSigSendType" SG_ 2458166529 C_RLTiltUpSw_HU 4;
BA_ "UserSigValidity" SG_ 2458166529 C_RLTiltUpSw_HU 0;
BA_REL_ "GenSigTimeoutTime" BU_SG_REL_ RLPSM SG_ 2458166529 C_RLTiltUpSw_HU 1500;
BA_ "Version" SG_ 2458166529 C_RLTiltUpSw_HU "18.10.03";
BA_ "GenSigSendType" SG_ 2458166529 C_RRTiltDownSw_HU 4;
BA_ "UserSigValidity" SG_ 2458166529 C_RRTiltDownSw_HU 0;
BA_REL_ "GenSigTimeoutTime" BU_SG_REL_ RRPSM SG_ 2458166529 C_RRTiltDownSw_HU 1500;
BA_ "Version" SG_ 2458166529 C_RRTiltDownSw_HU "18.10.03";
BA_ "GenSigSendType" SG_ 2458166529 C_RRTiltUpSw_HU 4;
BA_ "UserSigValidity" SG_ 2458166529 C_RRTiltUpSw_HU 0;
BA_REL_ "GenSigTimeoutTime" BU_SG_REL_ RRPSM SG_ 2458166529 C_RRTiltUpSw_HU 1500;
BA_ "Version" SG_ 2458166529 C_RRTiltUpSw_HU "18.10.03";
BA_ "GenSigSendType" SG_ 2458166529 C_RLRclBwdSw_HU 4;
BA_ "UserSigValidity" SG_ 2458166529 C_RLRclBwdSw_HU 0;
BA_REL_ "GenSigTimeoutTime" BU_SG_REL_ RLPSM SG_ 2458166529 C_RLRclBwdSw_HU 1500;
BA_ "Version" SG_ 2458166529 C_RLRclBwdSw_HU "18.10.03";
BA_ "GenSigSendType" SG_ 2458166529 C_RLRclFwdSw_HU 4;
BA_ "UserSigValidity" SG_ 2458166529 C_RLRclFwdSw_HU 0;
BA_REL_ "GenSigTimeoutTime" BU_SG_REL_ RLPSM SG_ 2458166529 C_RLRclFwdSw_HU 1500;
BA_ "Version" SG_ 2458166529 C_RLRclFwdSw_HU "18.10.03";
BA_ "GenSigSendType" SG_ 2458166529 C_RLFldSw_HU 4;
BA_ "UserSigValidity" SG_ 2458166529 C_RLFldSw_HU 0;
BA_ "Version" SG_ 2458166529 C_RLFldSw_HU "18.10.03";
BA_ "GenSigSendType" SG_ 2458166529 C_RRRclBwdSw_HU 4;
BA_ "UserSigValidity" SG_ 2458166529 C_RRRclBwdSw_HU 0;
BA_REL_ "GenSigTimeoutTime" BU_SG_REL_ RRPSM SG_ 2458166529 C_RRRclBwdSw_HU 1500;
BA_ "Version" SG_ 2458166529 C_RRRclBwdSw_HU "18.10.03";
BA_ "GenSigSendType" SG_ 2458166529 C_RRRclFwdSw_HU 4;
BA_ "UserSigValidity" SG_ 2458166529 C_RRRclFwdSw_HU 0;
BA_REL_ "GenSigTimeoutTime" BU_SG_REL_ RRPSM SG_ 2458166529 C_RRRclFwdSw_HU 1500;
BA_ "Version" SG_ 2458166529 C_RRRclFwdSw_HU "18.10.03";
BA_ "GenSigSendType" SG_ 2458166529 C_TLHrestFldSw_HU 4;
BA_ "UserSigValidity" SG_ 2458166529 C_TLHrestFldSw_HU 0;
BA_ "Version" SG_ 2458166529 C_TLHrestFldSw_HU "18.10.03";
BA_ "GenSigSendType" SG_ 2458166529 C_TRHrestFldSw_HU 4;
BA_ "UserSigValidity" SG_ 2458166529 C_TRHrestFldSw_HU 0;
BA_ "Version" SG_ 2458166529 C_TRHrestFldSw_HU "18.10.03";
BA_ "GenSigSendType" SG_ 2458166529 C_RLRlxSW_HU 4;
BA_ "UserSigValidity" SG_ 2458166529 C_RLRlxSW_HU 0;
BA_REL_ "GenSigTimeoutTime" BU_SG_REL_ RLPSM SG_ 2458166529 C_RLRlxSW_HU 1500;
BA_ "Version" SG_ 2458166529 C_RLRlxSW_HU "18.10.03";
BA_ "GenSigSendType" SG_ 2458166529 C_RRRlxSW_HU 4;
BA_ "UserSigValidity" SG_ 2458166529 C_RRRlxSW_HU 0;
BA_REL_ "GenSigTimeoutTime" BU_SG_REL_ RRPSM SG_ 2458166529 C_RRRlxSW_HU 1500;
BA_ "Version" SG_ 2458166529 C_RRRlxSW_HU "18.10.03";
BA_ "GenSigSendType" SG_ 2458166529 C_RRUnWalkInSw_HU 4;
BA_ "UserSigValidity" SG_ 2458166529 C_RRUnWalkInSw_HU 0;
BA_ "Version" SG_ 2458166529 C_RRUnWalkInSw_HU "18.10.03";
BA_ "GenSigSendType" SG_ 2458166529 C_RRWalkInSw_HU 4;
BA_ "UserSigValidity" SG_ 2458166529 C_RRWalkInSw_HU 0;
BA_ "Version" SG_ 2458166529 C_RRWalkInSw_HU "18.10.03";
BA_ "GenSigSendType" SG_ 2458166529 C_TLFldSw_HU 4;
BA_ "UserSigValidity" SG_ 2458166529 C_TLFldSw_HU 0;
BA_ "Version" SG_ 2458166529 C_TLFldSw_HU "18.10.03";
BA_ "GenSigSendType" SG_ 2458166529 C_TRFldSw_HU 4;
BA_ "UserSigValidity" SG_ 2458166529 C_TRFldSw_HU 0;
BA_ "Version" SG_ 2458166529 C_TRFldSw_HU "18.10.03";
BA_ "GenSigSendType" SG_ 2458166529 C_RRUnFldSw_HU 4;
BA_ "UserSigValidity" SG_ 2458166529 C_RRUnFldSw_HU 0;
BA_ "Version" SG_ 2458166529 C_RRUnFldSw_HU "18.10.03";
BA_ "GenSigSendType" SG_ 2458166529 C_RLUnWalkInSw_HU 4;
BA_ "UserSigValidity" SG_ 2458166529 C_RLUnWalkInSw_HU 0;
BA_ "Version" SG_ 2458166529 C_RLUnWalkInSw_HU "18.10.03";
BA_ "GenSigSendType" SG_ 2458166529 C_RLWalkInSw_HU 4;
BA_ "UserSigValidity" SG_ 2458166529 C_RLWalkInSw_HU 0;
BA_ "Version" SG_ 2458166529 C_RLWalkInSw_HU "18.10.03";
BA_ "GenSigSendType" SG_ 2458166529 C_TRRclBwdSw_HU 4;
BA_ "UserSigValidity" SG_ 2458166529 C_TRRclBwdSw_HU 0;
BA_ "Version" SG_ 2458166529 C_TRRclBwdSw_HU "18.10.03";
BA_ "GenSigSendType" SG_ 2458166529 C_TRRclFwdSw_HU 4;
BA_ "UserSigValidity" SG_ 2458166529 C_TRRclFwdSw_HU 0;
BA_ "Version" SG_ 2458166529 C_TRRclFwdSw_HU "18.10.03";
BA_ "GenSigSendType" SG_ 2458166529 C_RRFldSw_HU 4;
BA_ "UserSigValidity" SG_ 2458166529 C_RRFldSw_HU 0;
BA_ "Version" SG_ 2458166529 C_RRFldSw_HU "18.10.03";
BA_ "GenSigSendType" SG_ 2458166529 C_TLRclBwdSw_HU 4;
BA_ "UserSigValidity" SG_ 2458166529 C_TLRclBwdSw_HU 0;
BA_ "Version" SG_ 2458166529 C_TLRclBwdSw_HU "18.10.03";
BA_ "GenSigSendType" SG_ 2458166529 C_TLRclFwdSw_HU 4;
BA_ "UserSigValidity" SG_ 2458166529 C_TLRclFwdSw_HU 0;
BA_ "Version" SG_ 2458166529 C_TLRclFwdSw_HU "18.10.03";
BA_ "GenSigSendType" SG_ 2458166529 C_RLTiltDownSw_HU 4;
BA_ "UserSigValidity" SG_ 2458166529 C_RLTiltDownSw_HU 0;
BA_REL_ "GenSigTimeoutTime" BU_SG_REL_ RLPSM SG_ 2458166529 C_RLTiltDownSw_HU 1500;
BA_ "Version" SG_ 2458166529 C_RLTiltDownSw_HU "18.10.03";
BA_ "GenMsgCycleTime" BO_ 2315419905 0;
BA_ "VFrameFormat" BO_ 2315419905 1;
BA_ "Description" SG_ 2315419905 AVN_Encrypted_Result1 "This signal is for a send encrypted result of AVN";
BA_ "GenSigSendType" SG_ 2315419905 AVN_Encrypted_Result1 4;
BA_ "UserSigValidity" SG_ 2315419905 AVN_Encrypted_Result1 0;
BA_REL_ "GenSigTimeoutTime" BU_SG_REL_ FPM SG_ 2315419905 AVN_Encrypted_Result1 0;
BA_ "Version" SG_ 2315419905 AVN_Encrypted_Result1 "21.07.05";
BA_ "GenMsgSendType" BO_ 2462364673 0;
BA_ "VFrameFormat" BO_ 2462364673 1;
BA_ "GenSigSendType" SG_ 2462364673 POS_V2_3_Offset 4;
BA_ "UserSigValidity" SG_ 2462364673 POS_V2_3_Offset 3;
BA_REL_ "GenSigTimeoutTime" BU_SG_REL_ DSAU SG_ 2462364673 POS_V2_3_Offset 1500;
BA_ "Version" SG_ 2462364673 POS_V2_3_Offset "20.03.06";
BA_ "GenSigSendType" SG_ 2462364673 POS_V2_3_PathIndex 4;
BA_ "UserSigValidity" SG_ 2462364673 POS_V2_3_PathIndex 3;
BA_ "Version" SG_ 2462364673 POS_V2_3_PathIndex "20.03.06";
BA_ "GenSigSendType" SG_ 2462364673 POS_V2_3_CyclicCounter 4;
BA_ "UserSigValidity" SG_ 2462364673 POS_V2_3_CyclicCounter 3;
BA_REL_ "GenSigTimeoutTime" BU_SG_REL_ DSAU SG_ 2462364673 POS_V2_3_CyclicCounter 1500;
BA_ "Version" SG_ 2462364673 POS_V2_3_CyclicCounter "20.03.06";
BA_ "GenSigSendType" SG_ 2462364673 POS_V2_3_RangeAvgSpeed 4;
BA_ "GenSigStartValue" SG_ 2462364673 POS_V2_3_RangeAvgSpeed 510;
BA_ "UserSigValidity" SG_ 2462364673 POS_V2_3_RangeAvgSpeed 3;
BA_ "Version" SG_ 2462364673 POS_V2_3_RangeAvgSpeed "20.03.06";
BA_ "GenSigSendType" SG_ 2462364673 POS_V2_3_CurrAltitude100m 4;
BA_ "UserSigValidity" SG_ 2462364673 POS_V2_3_CurrAltitude100m 3;
BA_ "Version" SG_ 2462364673 POS_V2_3_CurrAltitude100m "20.03.06";
BA_ "GenSigSendType" SG_ 2462364673 POS_V2_3_CurrAltitude1m 4;
BA_ "UserSigValidity" SG_ 2462364673 POS_V2_3_CurrAltitude1m 3;
BA_ "Version" SG_ 2462364673 POS_V2_3_CurrAltitude1m "20.03.06";
BA_ "GenSigSendType" SG_ 2462364673 POS_V2_3_CurrFuncRoadClass 4;
BA_ "UserSigValidity" SG_ 2462364673 POS_V2_3_CurrFuncRoadClass 3;
BA_REL_ "GenSigTimeoutTime" BU_SG_REL_ DSAU SG_ 2462364673 POS_V2_3_CurrFuncRoadClass 1500;
BA_ "Version" SG_ 2462364673 POS_V2_3_CurrFuncRoadClass "20.03.06";
BA_ "GenSigSendType" SG_ 2462364673 POS_V2_3_CurrFormOfWay 4;
BA_ "UserSigValidity" SG_ 2462364673 POS_V2_3_CurrFormOfWay 3;
BA_REL_ "GenSigTimeoutTime" BU_SG_REL_ DSAU SG_ 2462364673 POS_V2_3_CurrFormOfWay 1500;
BA_ "Version" SG_ 2462364673 POS_V2_3_CurrFormOfWay "20.03.06";
BA_ "GenSigSendType" SG_ 2462364673 POS_V2_3_CurrDirectionLanes 4;
BA_ "UserSigValidity" SG_ 2462364673 POS_V2_3_CurrDirectionLanes 3;
BA_ "Version" SG_ 2462364673 POS_V2_3_CurrDirectionLanes "20.03.06";
BA_ "GenSigSendType" SG_ 2462364673 POS_V2_3_CurrSpeedLimit 4;
BA_ "UserSigValidity" SG_ 2462364673 POS_V2_3_CurrSpeedLimit 3;
BA_ "Version" SG_ 2462364673 POS_V2_3_CurrSpeedLimit "20.03.06";
BA_ "GenSigSendType" SG_ 2462364673 POS_V2_3_CurrTrafficSpeed 4;
BA_ "UserSigValidity" SG_ 2462364673 POS_V2_3_CurrTrafficSpeed 3;
BA_ "Version" SG_ 2462364673 POS_V2_3_CurrTrafficSpeed "20.03.06";
BA_ "GenMsgCycleTime" BO_ 2466562561 0;
BA_ "VFrameFormat" BO_ 2466562561 1;
BA_ "GenSigSendType" SG_ 2466562561 C_RH_Unfolding_SW 4;
BA_ "UserSigValidity" SG_ 2466562561 C_RH_Unfolding_SW 1;
BA_ "Version" SG_ 2466562561 C_RH_Unfolding_SW "18.09.04";
BA_ "GenSigSendType" SG_ 2466562561 C_PSMHeightNValueSet 4;
BA_ "UserSigValidity" SG_ 2466562561 C_PSMHeightNValueSet 3;
BA_ "Version" SG_ 2466562561 C_PSMHeightNValueSet "18.09.04";
BA_ "GenSigSendType" SG_ 2466562561 C_AVN_PTGHeightNValueSet 4;
BA_ "UserSigValidity" SG_ 2466562561 C_AVN_PTGHeightNValueSet 3;
BA_ "Version" SG_ 2466562561 C_AVN_PTGHeightNValueSet "19.02.07";
BA_ "GenSigSendType" SG_ 2466562561 CF_AVN_SCCMLReset 4;
BA_ "UserSigValidity" SG_ 2466562561 CF_AVN_SCCMLReset 3;
BA_ "Version" SG_ 2466562561 CF_AVN_SCCMLReset "18.09.04";
BA_ "Description" SG_ 2466562561 C_TgltAwayCloseNValue "USM Request for Tailgate Away Close";
BA_ "GenSigSendType" SG_ 2466562561 C_TgltAwayCloseNValue 4;
BA_ "UserSigValidity" SG_ 2466562561 C_TgltAwayCloseNValue 3;
BA_ "Version" SG_ 2466562561 C_TgltAwayCloseNValue "19.01.10";
BA_ "GenSigSendType" SG_ 2466562561 C_RH_Folding_SW 4;
BA_ "UserSigValidity" SG_ 2466562561 C_RH_Folding_SW 1;
BA_ "Version" SG_ 2466562561 C_RH_Folding_SW "18.09.04";
BA_ "GenSigSendType" SG_ 2466562561 C_HAnBNValueSet 4;
BA_ "UserSigValidity" SG_ 2466562561 C_HAnBNValueSet 3;
BA_ "Version" SG_ 2466562561 C_HAnBNValueSet "18.09.04";
BA_ "GenSigSendType" SG_ 2466562561 CF_AVN_RrSeatRemindNValueSet 4;
BA_ "UserSigValidity" SG_ 2466562561 CF_AVN_RrSeatRemindNValueSet 3;
BA_ "Version" SG_ 2466562561 CF_AVN_RrSeatRemindNValueSet "18.09.04";
BA_ "GenSigSendType" SG_ 2466562561 CF_AVN_DSWNValueSet 4;
BA_ "UserSigValidity" SG_ 2466562561 CF_AVN_DSWNValueSet 3;
BA_REL_ "GenSigTimeoutTime" BU_SG_REL_ DSAU SG_ 2466562561 CF_AVN_DSWNValueSet 0;
BA_REL_ "GenSigTimeoutTime" BU_SG_REL_ ICC SG_ 2466562561 CF_AVN_DSWNValueSet 0;
BA_ "Version" SG_ 2466562561 CF_AVN_DSWNValueSet "18.09.04";
BA_ "GenSigSendType" SG_ 2466562561 CF_AVN_RRPSU_RLNValueSet 4;
BA_ "UserSigValidity" SG_ 2466562561 CF_AVN_RRPSU_RLNValueSet 3;
BA_REL_ "GenSigTimeoutTime" BU_SG_REL_ RLPSM SG_ 2466562561 CF_AVN_RRPSU_RLNValueSet 0;
BA_ "Version" SG_ 2466562561 CF_AVN_RRPSU_RLNValueSet "18.09.04";
BA_ "GenSigSendType" SG_ 2466562561 CF_AVN_APSUNValueSet 4;
BA_ "UserSigValidity" SG_ 2466562561 CF_AVN_APSUNValueSet 3;
BA_REL_ "GenSigTimeoutTime" BU_SG_REL_ APSM SG_ 2466562561 CF_AVN_APSUNValueSet 0;
BA_REL_ "GenSigTimeoutTime" BU_SG_REL_ APSS SG_ 2466562561 CF_AVN_APSUNValueSet 0;
BA_REL_ "GenSigTimeoutTime" BU_SG_REL_ ASAU SG_ 2466562561 CF_AVN_APSUNValueSet 0;
BA_ "Version" SG_ 2466562561 CF_AVN_APSUNValueSet "18.09.04";
BA_ "GenSigSendType" SG_ 2466562561 CF_AVN_NCC_CameraNValueSet 4;
BA_ "UserSigValidity" SG_ 2466562561 CF_AVN_NCC_CameraNValueSet 3;
BA_ "Version" SG_ 2466562561 CF_AVN_NCC_CameraNValueSet "18.09.04";
BA_ "GenSigSendType" SG_ 2466562561 CF_AVN_FCAJnctnNValueSet 4;
BA_ "UserSigValidity" SG_ 2466562561 CF_AVN_FCAJnctnNValueSet 3;
BA_ "Version" SG_ 2466562561 CF_AVN_FCAJnctnNValueSet "18.09.04";
BA_ "GenSigSendType" SG_ 2466562561 CF_AVN_RRPSU_RRNValueSet 4;
BA_ "UserSigValidity" SG_ 2466562561 CF_AVN_RRPSU_RRNValueSet 3;
BA_REL_ "GenSigTimeoutTime" BU_SG_REL_ RRPSM SG_ 2466562561 CF_AVN_RRPSU_RRNValueSet 0;
BA_ "Version" SG_ 2466562561 CF_AVN_RRPSU_RRNValueSet "18.09.04";
BA_ "GenSigSendType" SG_ 2466562561 C_LH_Unfolding_SW 4;
BA_ "UserSigValidity" SG_ 2466562561 C_LH_Unfolding_SW 1;
BA_ "Version" SG_ 2466562561 C_LH_Unfolding_SW "18.09.04";
BA_ "GenSigSendType" SG_ 2466562561 CF_AVN_HtBlcAstNValueSet 4;
BA_ "UserSigValidity" SG_ 2466562561 CF_AVN_HtBlcAstNValueSet 3;
BA_REL_ "GenSigTimeoutTime" BU_SG_REL_ PSM SG_ 2466562561 CF_AVN_HtBlcAstNValueSet 0;
BA_REL_ "GenSigTimeoutTime" BU_SG_REL_ APSM SG_ 2466562561 CF_AVN_HtBlcAstNValueSet 0;
BA_ "Version" SG_ 2466562561 CF_AVN_HtBlcAstNValueSet "18.09.04";
BA_ "GenSigSendType" SG_ 2466562561 CF_AVN_HtBlcDrvNValueSet 4;
BA_ "UserSigValidity" SG_ 2466562561 CF_AVN_HtBlcDrvNValueSet 3;
BA_REL_ "GenSigTimeoutTime" BU_SG_REL_ PSM SG_ 2466562561 CF_AVN_HtBlcDrvNValueSet 0;
BA_REL_ "GenSigTimeoutTime" BU_SG_REL_ APSM SG_ 2466562561 CF_AVN_HtBlcDrvNValueSet 0;
BA_ "Version" SG_ 2466562561 CF_AVN_HtBlcDrvNValueSet "18.09.04";
BA_ "GenSigSendType" SG_ 2466562561 CF_AVN_SCCModeNValueSet 4;
BA_ "GenSigStartValue" SG_ 2466562561 CF_AVN_SCCModeNValueSet 3;
BA_ "UserSigValidity" SG_ 2466562561 CF_AVN_SCCModeNValueSet 3;
BA_ "Version" SG_ 2466562561 CF_AVN_SCCModeNValueSet "18.12.03";
BA_ "GenSigSendType" SG_ 2466562561 CF_AVN_SCCMLChar1Set 4;
BA_ "UserSigValidity" SG_ 2466562561 CF_AVN_SCCMLChar1Set 3;
BA_ "Version" SG_ 2466562561 CF_AVN_SCCMLChar1Set "19.11.05";
BA_ "GenSigSendType" SG_ 2466562561 CF_AVN_UIPNValueSet 4;
BA_ "UserSigValidity" SG_ 2466562561 CF_AVN_UIPNValueSet 3;
BA_ "Version" SG_ 2466562561 CF_AVN_UIPNValueSet "18.10.06";
BA_ "GenSigSendType" SG_ 2466562561 CF_AVN_SCCMLChar2Set 4;
BA_ "UserSigValidity" SG_ 2466562561 CF_AVN_SCCMLChar2Set 3;
BA_ "Version" SG_ 2466562561 CF_AVN_SCCMLChar2Set "19.11.05";
BA_ "GenSigSendType" SG_ 2466562561 CF_AVN_SCCMLChar3Set 4;
BA_ "UserSigValidity" SG_ 2466562561 CF_AVN_SCCMLChar3Set 3;
BA_ "Version" SG_ 2466562561 CF_AVN_SCCMLChar3Set "19.11.05";
BA_ "GenSigSendType" SG_ 2466562561 C_LH_Folding_SW 4;
BA_ "UserSigValidity" SG_ 2466562561 C_LH_Folding_SW 1;
BA_ "Version" SG_ 2466562561 C_LH_Folding_SW "18.09.04";
BA_ "Description" SG_ 2466562561 CF_AVN_NmodeFCAoffNValue "USM request for FCA Auto Off in N mode";
BA_ "GenSigSendType" SG_ 2466562561 CF_AVN_NmodeFCAoffNValue 4;
BA_ "UserSigValidity" SG_ 2466562561 CF_AVN_NmodeFCAoffNValue 3;
BA_ "Version" SG_ 2466562561 CF_AVN_NmodeFCAoffNValue "19.05.04";
BA_ "GenSigSendType" SG_ 2466562561 CF_AVN_HDALCFuncNValueSet 4;
BA_ "UserSigValidity" SG_ 2466562561 CF_AVN_HDALCFuncNValueSet 3;
BA_ "Version" SG_ 2466562561 CF_AVN_HDALCFuncNValueSet "18.09.04";
BA_ "GenMsgCycleTime" BO_ 1818 0;
BA_ "GenMsgCycleTimeFast" BO_ 1818 0;
BA_ "GenMsgNrOfRepetition" BO_ 1818 0;
BA_ "DiagResponse" BO_ 1818 1;
BA_ "GenMsgILSupport" BO_ 1818 0;
BA_ "TpMessage" BO_ 1818 1;
BA_ "TpTxIndex" BO_ 1818 160;
BA_ "Description" SG_ 1818 RLHVU_GST_Byte0 "TP Index : 160";
BA_ "UsrSigPurpose" SG_ 1818 RLHVU_GST_Byte0 4;
BA_ "UserSigValidity" SG_ 1818 RLHVU_GST_Byte0 0;
BA_REL_ "GenSigTimeoutTime" BU_SG_REL_ CGW_CCU SG_ 1818 RLHVU_GST_Byte0 0;
BA_ "NetworkRequest" SG_ 1818 RLHVU_GST_Byte0 0;
BA_ "NetworkRequestHoldingTime" SG_ 1818 RLHVU_GST_Byte0 5000;
BA_ "Version" SG_ 1818 RLHVU_GST_Byte0 "21.02.04";
BA_ "Description" SG_ 1818 RLHVU_GST_Byte2 "TP Index : 160";
BA_ "UsrSigPurpose" SG_ 1818 RLHVU_GST_Byte2 4;
BA_ "UserSigValidity" SG_ 1818 RLHVU_GST_Byte2 0;
BA_REL_ "GenSigTimeoutTime" BU_SG_REL_ CGW_CCU SG_ 1818 RLHVU_GST_Byte2 0;
BA_ "NetworkRequest" SG_ 1818 RLHVU_GST_Byte2 0;
BA_ "NetworkRequestHoldingTime" SG_ 1818 RLHVU_GST_Byte2 5000;
BA_ "Version" SG_ 1818 RLHVU_GST_Byte2 "21.02.04";
BA_ "Description" SG_ 1818 RLHVU_GST_Byte3 "TP Index : 160";
BA_ "UsrSigPurpose" SG_ 1818 RLHVU_GST_Byte3 4;
BA_ "UserSigValidity" SG_ 1818 RLHVU_GST_Byte3 0;
BA_REL_ "GenSigTimeoutTime" BU_SG_REL_ CGW_CCU SG_ 1818 RLHVU_GST_Byte3 0;
BA_ "NetworkRequest" SG_ 1818 RLHVU_GST_Byte3 0;
BA_ "NetworkRequestHoldingTime" SG_ 1818 RLHVU_GST_Byte3 5000;
BA_ "Version" SG_ 1818 RLHVU_GST_Byte3 "21.02.04";
BA_ "Description" SG_ 1818 RLHVU_GST_Byte4 "TP Index : 160";
BA_ "UsrSigPurpose" SG_ 1818 RLHVU_GST_Byte4 4;
BA_ "UserSigValidity" SG_ 1818 RLHVU_GST_Byte4 0;
BA_REL_ "GenSigTimeoutTime" BU_SG_REL_ CGW_CCU SG_ 1818 RLHVU_GST_Byte4 0;
BA_ "NetworkRequest" SG_ 1818 RLHVU_GST_Byte4 0;
BA_ "NetworkRequestHoldingTime" SG_ 1818 RLHVU_GST_Byte4 5000;
BA_ "Version" SG_ 1818 RLHVU_GST_Byte4 "21.02.04";
BA_ "Description" SG_ 1818 RLHVU_GST_Byte5 "TP Index : 160";
BA_ "UsrSigPurpose" SG_ 1818 RLHVU_GST_Byte5 4;
BA_ "UserSigValidity" SG_ 1818 RLHVU_GST_Byte5 0;
BA_REL_ "GenSigTimeoutTime" BU_SG_REL_ CGW_CCU SG_ 1818 RLHVU_GST_Byte5 0;
BA_ "NetworkRequest" SG_ 1818 RLHVU_GST_Byte5 0;
BA_ "NetworkRequestHoldingTime" SG_ 1818 RLHVU_GST_Byte5 5000;
BA_ "Version" SG_ 1818 RLHVU_GST_Byte5 "21.02.04";
BA_ "Description" SG_ 1818 RLHVU_GST_Byte6 "TP Index : 160";
BA_ "UsrSigPurpose" SG_ 1818 RLHVU_GST_Byte6 4;
BA_ "UserSigValidity" SG_ 1818 RLHVU_GST_Byte6 0;
BA_REL_ "GenSigTimeoutTime" BU_SG_REL_ CGW_CCU SG_ 1818 RLHVU_GST_Byte6 0;
BA_ "NetworkRequest" SG_ 1818 RLHVU_GST_Byte6 0;
BA_ "NetworkRequestHoldingTime" SG_ 1818 RLHVU_GST_Byte6 5000;
BA_ "Version" SG_ 1818 RLHVU_GST_Byte6 "21.02.04";
BA_ "Description" SG_ 1818 RLHVU_GST_Byte7 "TP Index : 160";
BA_ "UsrSigPurpose" SG_ 1818 RLHVU_GST_Byte7 4;
BA_ "UserSigValidity" SG_ 1818 RLHVU_GST_Byte7 0;
BA_REL_ "GenSigTimeoutTime" BU_SG_REL_ CGW_CCU SG_ 1818 RLHVU_GST_Byte7 0;
BA_ "NetworkRequest" SG_ 1818 RLHVU_GST_Byte7 0;
BA_ "NetworkRequestHoldingTime" SG_ 1818 RLHVU_GST_Byte7 5000;
BA_ "Version" SG_ 1818 RLHVU_GST_Byte7 "21.02.04";
BA_ "Description" SG_ 1818 RLHVU_GST_Byte1 "TP Index : 160";
BA_ "UsrSigPurpose" SG_ 1818 RLHVU_GST_Byte1 4;
BA_ "UserSigValidity" SG_ 1818 RLHVU_GST_Byte1 0;
BA_REL_ "GenSigTimeoutTime" BU_SG_REL_ CGW_CCU SG_ 1818 RLHVU_GST_Byte1 0;
BA_ "NetworkRequest" SG_ 1818 RLHVU_GST_Byte1 0;
BA_ "NetworkRequestHoldingTime" SG_ 1818 RLHVU_GST_Byte1 5000;
BA_ "Version" SG_ 1818 RLHVU_GST_Byte1 "21.02.04";
BA_ "GenMsgCycleTime" BO_ 1850 0;
BA_ "GenMsgCycleTimeFast" BO_ 1850 0;
BA_ "GenMsgNrOfRepetition" BO_ 1850 0;
BA_ "DiagResponse" BO_ 1850 1;
BA_ "GenMsgILSupport" BO_ 1850 0;
BA_ "TpMessage" BO_ 1850 1;
BA_ "TpTxIndex" BO_ 1850 161;
BA_ "Description" SG_ 1850 RLPSU_GST_Byte0 "TP Index : 161";
BA_ "UsrSigPurpose" SG_ 1850 RLPSU_GST_Byte0 4;
BA_ "UserSigValidity" SG_ 1850 RLPSU_GST_Byte0 0;
BA_REL_ "GenSigTimeoutTime" BU_SG_REL_ CGW_CCU SG_ 1850 RLPSU_GST_Byte0 0;
BA_ "NetworkRequest" SG_ 1850 RLPSU_GST_Byte0 0;
BA_ "NetworkRequestHoldingTime" SG_ 1850 RLPSU_GST_Byte0 5000;
BA_ "Version" SG_ 1850 RLPSU_GST_Byte0 "21.02.04";
BA_ "Description" SG_ 1850 RLPSU_GST_Byte2 "TP Index : 161";
BA_ "UsrSigPurpose" SG_ 1850 RLPSU_GST_Byte2 4;
BA_ "UserSigValidity" SG_ 1850 RLPSU_GST_Byte2 0;
BA_REL_ "GenSigTimeoutTime" BU_SG_REL_ CGW_CCU SG_ 1850 RLPSU_GST_Byte2 0;
BA_ "NetworkRequest" SG_ 1850 RLPSU_GST_Byte2 0;
BA_ "NetworkRequestHoldingTime" SG_ 1850 RLPSU_GST_Byte2 5000;
BA_ "Version" SG_ 1850 RLPSU_GST_Byte2 "21.02.04";
BA_ "Description" SG_ 1850 RLPSU_GST_Byte3 "TP Index : 161";
BA_ "UsrSigPurpose" SG_ 1850 RLPSU_GST_Byte3 4;
BA_ "UserSigValidity" SG_ 1850 RLPSU_GST_Byte3 0;
BA_REL_ "GenSigTimeoutTime" BU_SG_REL_ CGW_CCU SG_ 1850 RLPSU_GST_Byte3 0;
BA_ "NetworkRequest" SG_ 1850 RLPSU_GST_Byte3 0;
BA_ "NetworkRequestHoldingTime" SG_ 1850 RLPSU_GST_Byte3 5000;
BA_ "Version" SG_ 1850 RLPSU_GST_Byte3 "21.02.04";
BA_ "Description" SG_ 1850 RLPSU_GST_Byte4 "TP Index : 161";
BA_ "UsrSigPurpose" SG_ 1850 RLPSU_GST_Byte4 4;
BA_ "UserSigValidity" SG_ 1850 RLPSU_GST_Byte4 0;
BA_REL_ "GenSigTimeoutTime" BU_SG_REL_ CGW_CCU SG_ 1850 RLPSU_GST_Byte4 0;
BA_ "NetworkRequest" SG_ 1850 RLPSU_GST_Byte4 0;
BA_ "NetworkRequestHoldingTime" SG_ 1850 RLPSU_GST_Byte4 5000;
BA_ "Version" SG_ 1850 RLPSU_GST_Byte4 "21.02.04";
BA_ "Description" SG_ 1850 RLPSU_GST_Byte5 "TP Index : 161";
BA_ "UsrSigPurpose" SG_ 1850 RLPSU_GST_Byte5 4;
BA_ "UserSigValidity" SG_ 1850 RLPSU_GST_Byte5 0;
BA_REL_ "GenSigTimeoutTime" BU_SG_REL_ CGW_CCU SG_ 1850 RLPSU_GST_Byte5 0;
BA_ "NetworkRequest" SG_ 1850 RLPSU_GST_Byte5 0;
BA_ "NetworkRequestHoldingTime" SG_ 1850 RLPSU_GST_Byte5 5000;
BA_ "Version" SG_ 1850 RLPSU_GST_Byte5 "21.02.04";
BA_ "Description" SG_ 1850 RLPSU_GST_Byte6 "TP Index : 161";
BA_ "UsrSigPurpose" SG_ 1850 RLPSU_GST_Byte6 4;
BA_ "UserSigValidity" SG_ 1850 RLPSU_GST_Byte6 0;
BA_REL_ "GenSigTimeoutTime" BU_SG_REL_ CGW_CCU SG_ 1850 RLPSU_GST_Byte6 0;
BA_ "NetworkRequest" SG_ 1850 RLPSU_GST_Byte6 0;
BA_ "NetworkRequestHoldingTime" SG_ 1850 RLPSU_GST_Byte6 5000;
BA_ "Version" SG_ 1850 RLPSU_GST_Byte6 "21.02.04";
BA_ "Description" SG_ 1850 RLPSU_GST_Byte7 "TP Index : 161";
BA_ "UsrSigPurpose" SG_ 1850 RLPSU_GST_Byte7 4;
BA_ "UserSigValidity" SG_ 1850 RLPSU_GST_Byte7 0;
BA_REL_ "GenSigTimeoutTime" BU_SG_REL_ CGW_CCU SG_ 1850 RLPSU_GST_Byte7 0;
BA_ "NetworkRequest" SG_ 1850 RLPSU_GST_Byte7 0;
BA_ "NetworkRequestHoldingTime" SG_ 1850 RLPSU_GST_Byte7 5000;
BA_ "Version" SG_ 1850 RLPSU_GST_Byte7 "21.02.04";
BA_ "Description" SG_ 1850 RLPSU_GST_Byte1 "TP Index : 161";
BA_ "UsrSigPurpose" SG_ 1850 RLPSU_GST_Byte1 4;
BA_ "UserSigValidity" SG_ 1850 RLPSU_GST_Byte1 0;
BA_REL_ "GenSigTimeoutTime" BU_SG_REL_ CGW_CCU SG_ 1850 RLPSU_GST_Byte1 0;
BA_ "NetworkRequest" SG_ 1850 RLPSU_GST_Byte1 0;
BA_ "NetworkRequestHoldingTime" SG_ 1850 RLPSU_GST_Byte1 5000;
BA_ "Version" SG_ 1850 RLPSU_GST_Byte1 "21.02.04";
BA_ "GenMsgCycleTime" BO_ 1849 0;
BA_ "GenMsgCycleTimeFast" BO_ 1849 0;
BA_ "GenMsgNrOfRepetition" BO_ 1849 0;
BA_ "DiagResponse" BO_ 1849 1;
BA_ "GenMsgILSupport" BO_ 1849 0;
BA_ "TpMessage" BO_ 1849 1;
BA_ "TpTxIndex" BO_ 1849 166;
BA_ "Description" SG_ 1849 RRPSU_GST_Byte0 "TP Index : 166";
BA_ "UsrSigPurpose" SG_ 1849 RRPSU_GST_Byte0 4;
BA_ "UserSigValidity" SG_ 1849 RRPSU_GST_Byte0 0;
BA_REL_ "GenSigTimeoutTime" BU_SG_REL_ CGW_CCU SG_ 1849 RRPSU_GST_Byte0 0;
BA_ "NetworkRequest" SG_ 1849 RRPSU_GST_Byte0 0;
BA_ "NetworkRequestHoldingTime" SG_ 1849 RRPSU_GST_Byte0 5000;
BA_ "Version" SG_ 1849 RRPSU_GST_Byte0 "21.02.04";
BA_ "Description" SG_ 1849 RRPSU_GST_Byte2 "TP Index : 166";
BA_ "UsrSigPurpose" SG_ 1849 RRPSU_GST_Byte2 4;
BA_ "UserSigValidity" SG_ 1849 RRPSU_GST_Byte2 0;
BA_REL_ "GenSigTimeoutTime" BU_SG_REL_ CGW_CCU SG_ 1849 RRPSU_GST_Byte2 0;
BA_ "NetworkRequest" SG_ 1849 RRPSU_GST_Byte2 0;
BA_ "NetworkRequestHoldingTime" SG_ 1849 RRPSU_GST_Byte2 5000;
BA_ "Version" SG_ 1849 RRPSU_GST_Byte2 "21.02.04";
BA_ "Description" SG_ 1849 RRPSU_GST_Byte3 "TP Index : 166";
BA_ "UsrSigPurpose" SG_ 1849 RRPSU_GST_Byte3 4;
BA_ "UserSigValidity" SG_ 1849 RRPSU_GST_Byte3 0;
BA_REL_ "GenSigTimeoutTime" BU_SG_REL_ CGW_CCU SG_ 1849 RRPSU_GST_Byte3 0;
BA_ "NetworkRequest" SG_ 1849 RRPSU_GST_Byte3 0;
BA_ "NetworkRequestHoldingTime" SG_ 1849 RRPSU_GST_Byte3 5000;
BA_ "Version" SG_ 1849 RRPSU_GST_Byte3 "21.02.04";
BA_ "Description" SG_ 1849 RRPSU_GST_Byte4 "TP Index : 166";
BA_ "UsrSigPurpose" SG_ 1849 RRPSU_GST_Byte4 4;
BA_ "UserSigValidity" SG_ 1849 RRPSU_GST_Byte4 0;
BA_REL_ "GenSigTimeoutTime" BU_SG_REL_ CGW_CCU SG_ 1849 RRPSU_GST_Byte4 0;
BA_ "NetworkRequest" SG_ 1849 RRPSU_GST_Byte4 0;
BA_ "NetworkRequestHoldingTime" SG_ 1849 RRPSU_GST_Byte4 5000;
BA_ "Version" SG_ 1849 RRPSU_GST_Byte4 "21.02.04";
BA_ "Description" SG_ 1849 RRPSU_GST_Byte5 "TP Index : 166";
BA_ "UsrSigPurpose" SG_ 1849 RRPSU_GST_Byte5 4;
BA_ "UserSigValidity" SG_ 1849 RRPSU_GST_Byte5 0;
BA_REL_ "GenSigTimeoutTime" BU_SG_REL_ CGW_CCU SG_ 1849 RRPSU_GST_Byte5 0;
BA_ "NetworkRequest" SG_ 1849 RRPSU_GST_Byte5 0;
BA_ "NetworkRequestHoldingTime" SG_ 1849 RRPSU_GST_Byte5 5000;
BA_ "Version" SG_ 1849 RRPSU_GST_Byte5 "21.02.04";
BA_ "Description" SG_ 1849 RRPSU_GST_Byte6 "TP Index : 166";
BA_ "UsrSigPurpose" SG_ 1849 RRPSU_GST_Byte6 4;
BA_ "UserSigValidity" SG_ 1849 RRPSU_GST_Byte6 0;
BA_REL_ "GenSigTimeoutTime" BU_SG_REL_ CGW_CCU SG_ 1849 RRPSU_GST_Byte6 0;
BA_ "NetworkRequest" SG_ 1849 RRPSU_GST_Byte6 0;
BA_ "NetworkRequestHoldingTime" SG_ 1849 RRPSU_GST_Byte6 5000;
BA_ "Version" SG_ 1849 RRPSU_GST_Byte6 "21.02.04";
BA_ "Description" SG_ 1849 RRPSU_GST_Byte7 "TP Index : 166";
BA_ "UsrSigPurpose" SG_ 1849 RRPSU_GST_Byte7 4;
BA_ "UserSigValidity" SG_ 1849 RRPSU_GST_Byte7 0;
BA_REL_ "GenSigTimeoutTime" BU_SG_REL_ CGW_CCU SG_ 1849 RRPSU_GST_Byte7 0;
BA_ "NetworkRequest" SG_ 1849 RRPSU_GST_Byte7 0;
BA_ "NetworkRequestHoldingTime" SG_ 1849 RRPSU_GST_Byte7 5000;
BA_ "Version" SG_ 1849 RRPSU_GST_Byte7 "21.02.04";
BA_ "Description" SG_ 1849 RRPSU_GST_Byte1 "TP Index : 166";
BA_ "UsrSigPurpose" SG_ 1849 RRPSU_GST_Byte1 4;
BA_ "UserSigValidity" SG_ 1849 RRPSU_GST_Byte1 0;
BA_REL_ "GenSigTimeoutTime" BU_SG_REL_ CGW_CCU SG_ 1849 RRPSU_GST_Byte1 0;
BA_ "NetworkRequest" SG_ 1849 RRPSU_GST_Byte1 0;
BA_ "NetworkRequestHoldingTime" SG_ 1849 RRPSU_GST_Byte1 5000;
BA_ "Version" SG_ 1849 RRPSU_GST_Byte1 "21.02.04";
BA_ "GenMsgCycleTime" BO_ 1836 0;
BA_ "GenMsgCycleTimeFast" BO_ 1836 0;
BA_ "GenMsgNrOfRepetition" BO_ 1836 0;
BA_ "DiagResponse" BO_ 1836 1;
BA_ "GenMsgILSupport" BO_ 1836 0;
BA_ "TpMessage" BO_ 1836 1;
BA_ "TpTxIndex" BO_ 1836 168;
BA_ "Description" SG_ 1836 RWPC_GST_Byte0 "TP Index : 168";
BA_ "UsrSigPurpose" SG_ 1836 RWPC_GST_Byte0 4;
BA_ "UserSigValidity" SG_ 1836 RWPC_GST_Byte0 0;
BA_REL_ "GenSigTimeoutTime" BU_SG_REL_ CGW_CCU SG_ 1836 RWPC_GST_Byte0 0;
BA_ "NetworkRequest" SG_ 1836 RWPC_GST_Byte0 0;
BA_ "NetworkRequestHoldingTime" SG_ 1836 RWPC_GST_Byte0 5000;
BA_ "Version" SG_ 1836 RWPC_GST_Byte0 "21.02.04";
BA_ "Description" SG_ 1836 RWPC_GST_Byte2 "TP Index : 168";
BA_ "UsrSigPurpose" SG_ 1836 RWPC_GST_Byte2 4;
BA_ "UserSigValidity" SG_ 1836 RWPC_GST_Byte2 0;
BA_REL_ "GenSigTimeoutTime" BU_SG_REL_ CGW_CCU SG_ 1836 RWPC_GST_Byte2 0;
BA_ "NetworkRequest" SG_ 1836 RWPC_GST_Byte2 0;
BA_ "NetworkRequestHoldingTime" SG_ 1836 RWPC_GST_Byte2 5000;
BA_ "Version" SG_ 1836 RWPC_GST_Byte2 "21.02.04";
BA_ "Description" SG_ 1836 RWPC_GST_Byte3 "TP Index : 168";
BA_ "UsrSigPurpose" SG_ 1836 RWPC_GST_Byte3 4;
BA_ "UserSigValidity" SG_ 1836 RWPC_GST_Byte3 0;
BA_REL_ "GenSigTimeoutTime" BU_SG_REL_ CGW_CCU SG_ 1836 RWPC_GST_Byte3 0;
BA_ "NetworkRequest" SG_ 1836 RWPC_GST_Byte3 0;
BA_ "NetworkRequestHoldingTime" SG_ 1836 RWPC_GST_Byte3 5000;
BA_ "Version" SG_ 1836 RWPC_GST_Byte3 "21.02.04";
BA_ "Description" SG_ 1836 RWPC_GST_Byte4 "TP Index : 168";
BA_ "UsrSigPurpose" SG_ 1836 RWPC_GST_Byte4 4;
BA_ "UserSigValidity" SG_ 1836 RWPC_GST_Byte4 0;
BA_REL_ "GenSigTimeoutTime" BU_SG_REL_ CGW_CCU SG_ 1836 RWPC_GST_Byte4 0;
BA_ "NetworkRequest" SG_ 1836 RWPC_GST_Byte4 0;
BA_ "NetworkRequestHoldingTime" SG_ 1836 RWPC_GST_Byte4 5000;
BA_ "Version" SG_ 1836 RWPC_GST_Byte4 "21.02.04";
BA_ "Description" SG_ 1836 RWPC_GST_Byte5 "TP Index : 168";
BA_ "UsrSigPurpose" SG_ 1836 RWPC_GST_Byte5 4;
BA_ "UserSigValidity" SG_ 1836 RWPC_GST_Byte5 0;
BA_REL_ "GenSigTimeoutTime" BU_SG_REL_ CGW_CCU SG_ 1836 RWPC_GST_Byte5 0;
BA_ "NetworkRequest" SG_ 1836 RWPC_GST_Byte5 0;
BA_ "NetworkRequestHoldingTime" SG_ 1836 RWPC_GST_Byte5 5000;
BA_ "Version" SG_ 1836 RWPC_GST_Byte5 "21.02.04";
BA_ "Description" SG_ 1836 RWPC_GST_Byte6 "TP Index : 168";
BA_ "UsrSigPurpose" SG_ 1836 RWPC_GST_Byte6 4;
BA_ "UserSigValidity" SG_ 1836 RWPC_GST_Byte6 0;
BA_REL_ "GenSigTimeoutTime" BU_SG_REL_ CGW_CCU SG_ 1836 RWPC_GST_Byte6 0;
BA_ "NetworkRequest" SG_ 1836 RWPC_GST_Byte6 0;
BA_ "NetworkRequestHoldingTime" SG_ 1836 RWPC_GST_Byte6 5000;
BA_ "Version" SG_ 1836 RWPC_GST_Byte6 "21.02.04";
BA_ "Description" SG_ 1836 RWPC_GST_Byte7 "TP Index : 168";
BA_ "UsrSigPurpose" SG_ 1836 RWPC_GST_Byte7 4;
BA_ "UserSigValidity" SG_ 1836 RWPC_GST_Byte7 0;
BA_REL_ "GenSigTimeoutTime" BU_SG_REL_ CGW_CCU SG_ 1836 RWPC_GST_Byte7 0;
BA_ "NetworkRequest" SG_ 1836 RWPC_GST_Byte7 0;
BA_ "NetworkRequestHoldingTime" SG_ 1836 RWPC_GST_Byte7 5000;
BA_ "Version" SG_ 1836 RWPC_GST_Byte7 "21.02.04";
BA_ "Description" SG_ 1836 RWPC_GST_Byte1 "TP Index : 168";
BA_ "UsrSigPurpose" SG_ 1836 RWPC_GST_Byte1 4;
BA_ "UserSigValidity" SG_ 1836 RWPC_GST_Byte1 0;
BA_REL_ "GenSigTimeoutTime" BU_SG_REL_ CGW_CCU SG_ 1836 RWPC_GST_Byte1 0;
BA_ "NetworkRequest" SG_ 1836 RWPC_GST_Byte1 0;
BA_ "NetworkRequestHoldingTime" SG_ 1836 RWPC_GST_Byte1 5000;
BA_ "Version" SG_ 1836 RWPC_GST_Byte1 "21.02.04";
BA_ "GenMsgSendType" BO_ 799 0;
BA_ "Description" SG_ 799 SBCM_DRV_Crc1Val "The data area for CRC calculation is based on the data length (DLC) of the message DB.

The CRC shall be calculated over the entire data block (excluding the CRC bytes) including the user data, alive counter and Data ID 

 

- CRC Polynomial (0x1D) , Initial Value : 0x00, XOR value : 0xFF, Data ID Mode : Both, Data ID : Message ID + 0xF800 

- The initial value is for CRC calculation and the message should be sent with the calculated result value. 

The mathematical expression to 8 bit CRC polynomial is given here. G(x) = x8 + x4 + x3 + x2 + 1";
BA_ "GenSigSendType" SG_ 799 SBCM_DRV_Crc1Val 4;
BA_ "GenSigStartValue" SG_ 799 SBCM_DRV_Crc1Val 255;
BA_ "UserSigValidity" SG_ 799 SBCM_DRV_Crc1Val 0;
BA_ "Version" SG_ 799 SBCM_DRV_Crc1Val "19.07.06";
BA_ "Description" SG_ 799 DRV_CrashUnlockCmd "Drive Crash Unlock Command";
BA_ "GenSigSendType" SG_ 799 DRV_CrashUnlockCmd 4;
BA_ "UserSigValidity" SG_ 799 DRV_CrashUnlockCmd 0;
BA_ "NetworkRequest" SG_ 799 DRV_CrashUnlockCmd 0;
BA_ "Version" SG_ 799 DRV_CrashUnlockCmd "20.09.00";
BA_ "Description" SG_ 799 C_ApprOpenStatus "This is for Power Door System enable/disable signal.";
BA_ "GenSigSendType" SG_ 799 C_ApprOpenStatus 4;
BA_ "UserSigValidity" SG_ 799 C_ApprOpenStatus 0;
BA_ "Version" SG_ 799 C_ApprOpenStatus "20.09.00";
BA_ "Description" SG_ 799 SBCM_DRV_AlvCnt1Val "For the first transmission request for a data element the counter shall be initialized with 0 and shall be incremented by 1

for every subsequent send request. When the counter reaches the maximum value(0xE), then it shall restart with 0 for the next send request";
BA_ "GenSigSendType" SG_ 799 SBCM_DRV_AlvCnt1Val 4;
BA_ "UserSigValidity" SG_ 799 SBCM_DRV_AlvCnt1Val 0;
BA_ "Version" SG_ 799 SBCM_DRV_AlvCnt1Val "19.07.06";
BA_ "Description" SG_ 799 Warn_DrvDrSwSta_SBCM "Warning Drive Door Switch State";
BA_ "GenSigSendType" SG_ 799 Warn_DrvDrSwSta_SBCM 4;
BA_ "UserSigValidity" SG_ 799 Warn_DrvDrSwSta_SBCM 0;
BA_REL_ "GenSigTimeoutTime" BU_SG_REL_ RWPC SG_ 799 Warn_DrvDrSwSta_SBCM 1500;
BA_REL_ "GenSigTimeoutTime" BU_SG_REL_ PSM SG_ 799 Warn_DrvDrSwSta_SBCM 1500;
BA_REL_ "GenSigTimeoutTime" BU_SG_REL_ AMP SG_ 799 Warn_DrvDrSwSta_SBCM 1500;
BA_REL_ "GenSigTimeoutTime" BU_SG_REL_ ATS SG_ 799 Warn_DrvDrSwSta_SBCM 1500;
BA_REL_ "GenSigTimeoutTime" BU_SG_REL_ ICC SG_ 799 Warn_DrvDrSwSta_SBCM 1500;
BA_ "NetworkRequest" SG_ 799 Warn_DrvDrSwSta_SBCM 0;
BA_ "Version" SG_ 799 Warn_DrvDrSwSta_SBCM "19.07.06";
BA_ "Description" SG_ 799 DoorLock_DrvDrUnLkSta_SBCM "Drive Door Lock Unlock Status";
BA_ "GenSigSendType" SG_ 799 DoorLock_DrvDrUnLkSta_SBCM 4;
BA_ "UserSigValidity" SG_ 799 DoorLock_DrvDrUnLkSta_SBCM 0;
BA_REL_ "GenSigTimeoutTime" BU_SG_REL_ ATS SG_ 799 DoorLock_DrvDrUnLkSta_SBCM 1500;
BA_ "NetworkRequest" SG_ 799 DoorLock_DrvDrUnLkSta_SBCM 0;
BA_ "Version" SG_ 799 DoorLock_DrvDrUnLkSta_SBCM "19.07.06";
BA_ "Description" SG_ 799 DRV_SEAWarn_LH "Drive (FLH) Door SEA Warning";
BA_ "GenSigSendType" SG_ 799 DRV_SEAWarn_LH 4;
BA_ "UserSigValidity" SG_ 799 DRV_SEAWarn_LH 0;
BA_REL_ "GenSigTimeoutTime" BU_SG_REL_ AMP SG_ 799 DRV_SEAWarn_LH 1500;
BA_ "NetworkRequest" SG_ 799 DRV_SEAWarn_LH 0;
BA_ "Version" SG_ 799 DRV_SEAWarn_LH "19.12.00";
BA_ "Description" SG_ 799 DRV_SEAWarn_RH "Drive (FRH) Door SEA Warning";
BA_ "GenSigSendType" SG_ 799 DRV_SEAWarn_RH 4;
BA_ "UserSigValidity" SG_ 799 DRV_SEAWarn_RH 0;
BA_REL_ "GenSigTimeoutTime" BU_SG_REL_ AMP SG_ 799 DRV_SEAWarn_RH 1500;
BA_ "NetworkRequest" SG_ 799 DRV_SEAWarn_RH 0;
BA_ "Version" SG_ 799 DRV_SEAWarn_RH "19.12.07";
BA_ "Description" SG_ 799 DRV_SEWWarn_LH "Drive (FLH) Door Safety Exit Warning";
BA_ "GenSigSendType" SG_ 799 DRV_SEWWarn_LH 4;
BA_ "UserSigValidity" SG_ 799 DRV_SEWWarn_LH 0;
BA_REL_ "GenSigTimeoutTime" BU_SG_REL_ AMP SG_ 799 DRV_SEWWarn_LH 1500;
BA_ "NetworkRequest" SG_ 799 DRV_SEWWarn_LH 0;
BA_ "Version" SG_ 799 DRV_SEWWarn_LH "20.09.00";
BA_ "Description" SG_ 799 DRV_SEWWarn_RH "Drive (FRH) Door Safety Exit Warning";
BA_ "GenSigSendType" SG_ 799 DRV_SEWWarn_RH 4;
BA_ "UserSigValidity" SG_ 799 DRV_SEWWarn_RH 0;
BA_REL_ "GenSigTimeoutTime" BU_SG_REL_ AMP SG_ 799 DRV_SEWWarn_RH 1500;
BA_ "NetworkRequest" SG_ 799 DRV_SEWWarn_RH 0;
BA_ "Version" SG_ 799 DRV_SEWWarn_RH "20.09.00";
BA_ "GenSigSendType" SG_ 799 DRV_MRActivationAlarm 4;
BA_ "UserSigValidity" SG_ 799 DRV_MRActivationAlarm 0;
BA_ "NetworkRequest" SG_ 799 DRV_MRActivationAlarm 0;
BA_ "NetworkRequestHoldingTime" SG_ 799 DRV_MRActivationAlarm 5000;
BA_ "Version" SG_ 799 DRV_MRActivationAlarm "19.11.05";
BA_ "GenSigSendType" SG_ 799 DRV_ReleaseWarn 4;
BA_ "UserSigValidity" SG_ 799 DRV_ReleaseWarn 0;
BA_ "NetworkRequest" SG_ 799 DRV_ReleaseWarn 0;
BA_ "NetworkRequestHoldingTime" SG_ 799 DRV_ReleaseWarn 5000;
BA_ "Version" SG_ 799 DRV_ReleaseWarn "19.11.05";
BA_ "Description" SG_ 799 Latch_TypeOption_DRV "If the E-Lacth is applied, the signal will be send for identify the door lock/unlock function and option.";
BA_ "GenSigSendType" SG_ 799 Latch_TypeOption_DRV 4;
BA_ "UserSigValidity" SG_ 799 Latch_TypeOption_DRV 0;
BA_ "NetworkRequest" SG_ 799 Latch_TypeOption_DRV 0;
BA_ "Version" SG_ 799 Latch_TypeOption_DRV "20.09.00";
BA_ "GenSigSendType" SG_ 799 DRV_SWFailAlarm 4;
BA_ "UserSigValidity" SG_ 799 DRV_SWFailAlarm 0;
BA_ "NetworkRequest" SG_ 799 DRV_SWFailAlarm 0;
BA_ "NetworkRequestHoldingTime" SG_ 799 DRV_SWFailAlarm 5000;
BA_ "Version" SG_ 799 DRV_SWFailAlarm "19.11.05";
BA_ "GenSigSendType" SG_ 799 USM_PwrDRCloseByRKELockSta 4;
BA_ "UserSigValidity" SG_ 799 USM_PwrDRCloseByRKELockSta 0;
BA_ "NetworkRequest" SG_ 799 USM_PwrDRCloseByRKELockSta 0;
BA_ "NetworkRequestHoldingTime" SG_ 799 USM_PwrDRCloseByRKELockSta 5000;
BA_ "Version" SG_ 799 USM_PwrDRCloseByRKELockSta "20.12.03";
BA_ "GenSigSendType" SG_ 799 USM_PwrDRCloseByRKELockOpt 4;
BA_ "UserSigValidity" SG_ 799 USM_PwrDRCloseByRKELockOpt 0;
BA_ "NetworkRequest" SG_ 799 USM_PwrDRCloseByRKELockOpt 0;
BA_ "NetworkRequestHoldingTime" SG_ 799 USM_PwrDRCloseByRKELockOpt 5000;
BA_ "Version" SG_ 799 USM_PwrDRCloseByRKELockOpt "20.12.03";
BA_ "GenSigSendType" SG_ 799 USM_PwrDRCloseByBrakeSta 4;
BA_ "UserSigValidity" SG_ 799 USM_PwrDRCloseByBrakeSta 0;
BA_ "NetworkRequest" SG_ 799 USM_PwrDRCloseByBrakeSta 0;
BA_ "NetworkRequestHoldingTime" SG_ 799 USM_PwrDRCloseByBrakeSta 5000;
BA_ "Version" SG_ 799 USM_PwrDRCloseByBrakeSta "20.12.03";
BA_ "GenSigSendType" SG_ 799 USM_PwrDRCloseByBrakeOpt 4;
BA_ "UserSigValidity" SG_ 799 USM_PwrDRCloseByBrakeOpt 0;
BA_ "NetworkRequest" SG_ 799 USM_PwrDRCloseByBrakeOpt 0;
BA_ "NetworkRequestHoldingTime" SG_ 799 USM_PwrDRCloseByBrakeOpt 5000;
BA_ "Version" SG_ 799 USM_PwrDRCloseByBrakeOpt "20.12.03";
BA_ "GenSigSendType" SG_ 799 USM_PwrDRBuzzerSta 4;
BA_ "UserSigValidity" SG_ 799 USM_PwrDRBuzzerSta 0;
BA_ "NetworkRequest" SG_ 799 USM_PwrDRBuzzerSta 0;
BA_ "NetworkRequestHoldingTime" SG_ 799 USM_PwrDRBuzzerSta 5000;
BA_ "Version" SG_ 799 USM_PwrDRBuzzerSta "20.12.03";
BA_ "GenSigSendType" SG_ 799 USM_PwrDRBuzzerOpt 4;
BA_ "UserSigValidity" SG_ 799 USM_PwrDRBuzzerOpt 0;
BA_ "NetworkRequest" SG_ 799 USM_PwrDRBuzzerOpt 0;
BA_ "NetworkRequestHoldingTime" SG_ 799 USM_PwrDRBuzzerOpt 5000;
BA_ "Version" SG_ 799 USM_PwrDRBuzzerOpt "20.12.03";
BA_ "GenSigSendType" SG_ 799 PDS_TypeOption_DRV 4;
BA_ "UserSigValidity" SG_ 799 PDS_TypeOption_DRV 0;
BA_ "NetworkRequest" SG_ 799 PDS_TypeOption_DRV 0;
BA_ "Version" SG_ 799 PDS_TypeOption_DRV "20.09.00";
BA_ "Description" SG_ 799 C_DrvDoorApproachOpen "Fob searching start and stop signal for PDS.";
BA_ "GenSigSendType" SG_ 799 C_DrvDoorApproachOpen 4;
BA_ "UserSigValidity" SG_ 799 C_DrvDoorApproachOpen 0;
BA_ "Version" SG_ 799 C_DrvDoorApproachOpen "20.09.00";
BA_ "Description" SG_ 799 C_DrvDoorApproachClose "To close the door automatically, request the fob searching signal";
BA_ "GenSigSendType" SG_ 799 C_DrvDoorApproachClose 4;
BA_ "UserSigValidity" SG_ 799 C_DrvDoorApproachClose 0;
BA_ "Version" SG_ 799 C_DrvDoorApproachClose "20.09.00";
BA_ "GenSigSendType" SG_ 799 DoorLock_PDSLkSwSta_DRV 4;
BA_ "UserSigValidity" SG_ 799 DoorLock_PDSLkSwSta_DRV 0;
BA_REL_ "GenSigTimeoutTime" BU_SG_REL_ AMP SG_ 799 DoorLock_PDSLkSwSta_DRV 1500;
BA_ "NetworkRequest" SG_ 799 DoorLock_PDSLkSwSta_DRV 0;
BA_ "Version" SG_ 799 DoorLock_PDSLkSwSta_DRV "20.09.00";
BA_ "GenSigSendType" SG_ 799 DRVDoorPushAlarm 4;
BA_ "UserSigValidity" SG_ 799 DRVDoorPushAlarm 0;
BA_ "NetworkRequest" SG_ 799 DRVDoorPushAlarm 0;
BA_ "NetworkRequestHoldingTime" SG_ 799 DRVDoorPushAlarm 5000;
BA_ "Version" SG_ 799 DRVDoorPushAlarm "20.09.00";
BA_ "GenMsgSendType" BO_ 2164277250 0;
BA_ "GenMsgCycleTime" BO_ 2164277250 20;
BA_ "GenMsgCycleTimeFast" BO_ 2164277250 0;
BA_ "GenMsgNrOfRepetition" BO_ 2164277250 0;
BA_ "GenMsgDelayTime" BO_ 2164277250 0;
BA_ "VFrameFormat" BO_ 2164277250 1;
BA_ "Description" SG_ 2164277250 TCU_CurrGearSta "CUR_GR indicates the gear speed which is currently engaged in the gearbox.";
BA_ "UserSigValidity" SG_ 2164277250 TCU_CurrGearSta 3;
BA_ "RoutingFactor" SG_ 2164277250 TCU_CurrGearSta 5;
BA_ "Version" SG_ 2164277250 TCU_CurrGearSta "17.11.00";
BA_ "Description" SG_ 2164277250 TCH_EngTrgtGearSta "TCH_EngTrgtGearSta informs about target gear of SS timing 

(For indicating Paddle shift or Manual mode on cluster)";
BA_ "UserSigValidity" SG_ 2164277250 TCH_EngTrgtGearSta 3;
BA_ "RoutingFactor" SG_ 2164277250 TCH_EngTrgtGearSta 5;
BA_ "Version" SG_ 2164277250 TCH_EngTrgtGearSta "17.11.00";
BA_ "Description" SG_ 2164277250 TCU_EngTqLimVal "The TCU requests a engine torque limit(ETL) from the EMS. 

There is no time limitation of the intervention.

TCU requests engine torque limit below the TCU requesting torque.

The engine torque request signal means the absolute torque limitation.

TCU sends it through CAN system and makes it change every moment.

In any non-requesting situations, TCU sends the maximum value of CAN message.



If MSB is 1, this signal is - value.

else, this signal is +value.

0~10bit is used for absolute value.";
BA_ "GenSigStartValue" SG_ 2164277250 TCU_EngTqLimVal 2047;
BA_ "UserSigValidity" SG_ 2164277250 TCU_EngTqLimVal 3;
BA_ "RoutingFactor" SG_ 2164277250 TCU_EngTqLimVal 5;
BA_ "Version" SG_ 2164277250 TCU_EngTqLimVal "18.01.02";
BA_ "Description" SG_ 2164277250 TCU_VehSpdKphVal "The vehicle speed calculated by TCU is transferred. 

If a vehicle has no vehicle speed sensor, no wheel speed sensor and no ABS(TCS/ESC) then it is impossible for an EMS to calculate veficle speed. In this case a TCU should calculate vehicle speed and send to other ECUs.

The calculation can be done with output speed of gearbox, final gear ratio and actual radius of a tire. 

In case of failure the value FFH is used as error identifier.";
BA_ "UserSigValidity" SG_ 2164277250 TCU_VehSpdKphVal 3;
BA_ "RoutingFactor" SG_ 2164277250 TCU_VehSpdKphVal 5;
BA_ "Version" SG_ 2164277250 TCU_VehSpdKphVal "17.11.00";
BA_ "Description" SG_ 2164277250 TCU_TrgtGearSta "CF_Tcu_TarGr informs about the speed, which is currently engaged in the gearbox, or, in case of a gear change (SWI_GS), which speed is reached.



Note: Gear changes covering more than one speed are also possible.

In the P and N positions, the frictional connection is interrupted hydraulically.

Depending on the type of error, the 3rd or 4th (forward) speed, and the R (reverse) speed are engaged in the limp home program.";
BA_ "UserSigValidity" SG_ 2164277250 TCU_TrgtGearSta 3;
BA_ "RoutingFactor" SG_ 2164277250 TCU_TrgtGearSta 5;
BA_ "Version" SG_ 2164277250 TCU_TrgtGearSta "17.11.00";
BA_ "Description" SG_ 2164277250 TCU_DcmlVehSpdKphVal "The signal VS_TCU_DECIAMAL means the value which is below decimal point of the vehicle speed.

For instance, if a vehicle speed is 13.75Km/h, VS_TCU means 13Km/h and VS_TCU_DECIMAL means 0.75Km/h.



Example)   VS_TCU = 13,  VS_TCU_DECIAMAL  = 96

Vehicle speed  = VS_TCU + ( VS_TCU_DECIMAL / 128 )

= 13 + ( 96 / 128 ) = 13.75 [Km/h]";
BA_ "UserSigValidity" SG_ 2164277250 TCU_DcmlVehSpdKphVal 3;
BA_ "RoutingFactor" SG_ 2164277250 TCU_DcmlVehSpdKphVal 5;
BA_ "Version" SG_ 2164277250 TCU_DcmlVehSpdKphVal "17.11.00";
BA_ "Description" SG_ 2164277250 TCU_SprkRtrdReq "The TCU requests a spark angle retard via the signal SPK_RTD_TCU to the EMS for torque reduction during the gear engage condition.



(PH) = ((HEX) - 3FH) * 0.375 (Advance) (PH) = (3FH - (HEX)) * (-0.375) (Retard)

-15˚  ... 0˚= 17H .. 3FH (Retard)

0.375˚. 15˚= 40H .. 67H (Advance)";
BA_ "GenSigStartValue" SG_ 2164277250 TCU_SprkRtrdReq 255;
BA_ "UserSigValidity" SG_ 2164277250 TCU_SprkRtrdReq 3;
BA_ "RoutingFactor" SG_ 2164277250 TCU_SprkRtrdReq 5;
BA_ "Version" SG_ 2164277250 TCU_SprkRtrdReq "17.11.00";
BA_ "Description" SG_ 2164277250 TCU_EngRpmDisSta "Flag for Engine RPM(from TCU) Display on Cluster, Only when this flag is set to 1, Cluster shall display the Engine RPM from TCU";
BA_ "UserSigValidity" SG_ 2164277250 TCU_EngRpmDisSta 3;
BA_ "RoutingFactor" SG_ 2164277250 TCU_EngRpmDisSta 5;
BA_ "Version" SG_ 2164277250 TCU_EngRpmDisSta "17.11.00";
BA_ "Description" SG_ 2164277250 TCU_GearLmpBlnkngReq "Cluster controls blinking of Gear lamp receiving the request signal from TCU.";
BA_ "UserSigValidity" SG_ 2164277250 TCU_GearLmpBlnkngReq 3;
BA_ "RoutingFactor" SG_ 2164277250 TCU_GearLmpBlnkngReq 5;
BA_ "Version" SG_ 2164277250 TCU_GearLmpBlnkngReq "17.11.00";
BA_ "Description" SG_ 2164277250 TCU_FuelCutInhbtReq "During coast down shifting, EMS may cut off fuel injection and as a result, a driver can feel bad shift feeling. In this case, to enhance shift quality, TCU needs inhibition of fuel cut off control.

This signal indicates inhibition of engine fuel cut off control.";
BA_ "UserSigValidity" SG_ 2164277250 TCU_FuelCutInhbtReq 3;
BA_ "RoutingFactor" SG_ 2164277250 TCU_FuelCutInhbtReq 5;
BA_ "Version" SG_ 2164277250 TCU_FuelCutInhbtReq "17.11.00";
BA_ "Description" SG_ 2164277250 TCU_IdleUpReq "When ATF(Automatic Transmission Fluid) rises in high temperauture, the TCU requests engine idle RPM up via the signal IDLE_UP_TCU to the EMS for reduction of gearshift time form Neutral to Reverse.



THIS SIGNAL IS FOR “LAMBDA ENGINE” SYSTEM ONLY.";
BA_ "UserSigValidity" SG_ 2164277250 TCU_IdleUpReq 3;
BA_ "RoutingFactor" SG_ 2164277250 TCU_IdleUpReq 5;
BA_ "Version" SG_ 2164277250 TCU_IdleUpReq "17.11.00";
BA_ "Description" SG_ 2164277250 TCU_CluTrgtGearSta "TCH_CluTrgtGearSta informs about target gear of SS timing 

(For indicating Paddle shift or Manual mode on cluster)";
BA_ "UserSigValidity" SG_ 2164277250 TCU_CluTrgtGearSta 3;
BA_ "RoutingFactor" SG_ 2164277250 TCU_CluTrgtGearSta 5;
BA_ "Version" SG_ 2164277250 TCU_CluTrgtGearSta "17.11.00";
BA_ "GenMsgSendType" BO_ 2164277251 0;
BA_ "GenMsgCycleTime" BO_ 2164277251 20;
BA_ "GenMsgCycleTimeFast" BO_ 2164277251 0;
BA_ "GenMsgNrOfRepetition" BO_ 2164277251 0;
BA_ "GenMsgDelayTime" BO_ 2164277251 0;
BA_ "VFrameFormat" BO_ 2164277251 1;
BA_ "Description" SG_ 2164277251 TCU_EngRpmDis "Engine RPM from TCU (Only for the display on Cluster)";
BA_ "UserSigValidity" SG_ 2164277251 TCU_EngRpmDis 3;
BA_ "RoutingFactor" SG_ 2164277251 TCU_EngRpmDis 5;
BA_ "Version" SG_ 2164277251 TCU_EngRpmDis "17.11.00";
BA_ "Description" SG_ 2164277251 TCU_SlpVal "This signal is used to avoid busy shifting during uphill driving.

It is calculated using engine torque, turbine torque and gearbox torque so on.

It has some restrictions like the following sentences

- No slope calculation during shifting, braking, 1st gear, or at low oil temperature (Under 10 degree).

- The slope calculation is inaccurate at low vehicle speed (under 30 KPH).

- Slope is calculated according to (CVW + 180Kg). It means that if the vehicle weight increases more than it, then the calculated slope value increases.

If calculated road gradient is less than -16%, SLOPE_TCU should be set to 00h, and if calculated road gradient is more than 15.5%, SLOPE_TCU should be set to 3Fh.";
BA_ "GenSigStartValue" SG_ 2164277251 TCU_SlpVal 32;
BA_ "UserSigValidity" SG_ 2164277251 TCU_SlpVal 3;
BA_ "RoutingFactor" SG_ 2164277251 TCU_SlpVal 5;
BA_ "Version" SG_ 2164277251 TCU_SlpVal "17.11.00";
BA_ "Description" SG_ 2164277251 TCU_EngSpdIncReq "This signal is a target engine speed requirement start flag signal by TCU, 

which is sent to ECU. It is synchronized to the signal engine speed increasing target speed value.";
BA_ "UserSigValidity" SG_ 2164277251 TCU_EngSpdIncReq 3;
BA_ "RoutingFactor" SG_ 2164277251 TCU_EngSpdIncReq 5;
BA_ "Version" SG_ 2164277251 TCU_EngSpdIncReq "17.11.00";
BA_ "Description" SG_ 2164277251 TCU_ObdSta "The signal TCU_OBD is used to inform the OBD master (EMS-ECU) in case a OBD relevant fault is detected. According to the OBD regulations the TCU could request MIL on. If a freeze frame request by the TCU has not been acknowledged (OBD_FRF_ACK) within 2 seconds, this request has to be canceled.

-> Related signal : See “EngFrzFrm” message

Bit0 : Reserved

Bit1 : Failure information of TCU

Bit2 : MIL on request



The exact meaning of this signals and under which conditions they are used has to be defined by the TCU supplier (in accordance with the OBD II regulations).";
BA_ "UserSigValidity" SG_ 2164277251 TCU_ObdSta 3;
BA_ "RoutingFactor" SG_ 2164277251 TCU_ObdSta 5;
BA_ "Version" SG_ 2164277251 TCU_ObdSta "17.11.00";
BA_ "Description" SG_ 2164277251 TCU_SprtyIndxSta "Sporty index based on the driver's driving behaviour";
BA_ "UserSigValidity" SG_ 2164277251 TCU_SprtyIndxSta 3;
BA_ "RoutingFactor" SG_ 2164277251 TCU_SprtyIndxSta 5;
BA_ "Version" SG_ 2164277251 TCU_SprtyIndxSta "17.11.00";
BA_ "Description" SG_ 2164277251 TCU_DrvngModDis "Driving mode display by TCU";
BA_ "UserSigValidity" SG_ 2164277251 TCU_DrvngModDis 3;
BA_ "RoutingFactor" SG_ 2164277251 TCU_DrvngModDis 5;
BA_ "Version" SG_ 2164277251 TCU_DrvngModDis "17.11.00";
BA_ "Description" SG_ 2164277251 TCU_DrvngModReq "Driving mode request with Normal, Eco, Eco+, Sport, Sport+

and Snow only TCU automode is on, otherwise, inactive";
BA_ "UserSigValidity" SG_ 2164277251 TCU_DrvngModReq 3;
BA_ "RoutingFactor" SG_ 2164277251 TCU_DrvngModReq 5;
BA_ "Version" SG_ 2164277251 TCU_DrvngModReq "17.11.00";
BA_ "Description" SG_ 2164277251 TCU_SmrtShftSta "Information of SmartShift";
BA_ "UserSigValidity" SG_ 2164277251 TCU_SmrtShftSta 3;
BA_ "RoutingFactor" SG_ 2164277251 TCU_SmrtShftSta 5;
BA_ "Version" SG_ 2164277251 TCU_SmrtShftSta "17.11.00";
BA_ "Description" SG_ 2164277251 TCU_LupTrgtEngSpdVal "This signal is a target engine speed requested by TCU, which is sent to ECU. 

It is intended for OFF-SLIP to be more successful in triggering fuel cut-off under more various driving conditions.";
BA_ "GenSigStartValue" SG_ 2164277251 TCU_LupTrgtEngSpdVal 255;
BA_ "UserSigValidity" SG_ 2164277251 TCU_LupTrgtEngSpdVal 3;
BA_ "RoutingFactor" SG_ 2164277251 TCU_LupTrgtEngSpdVal 5;
BA_ "Version" SG_ 2164277251 TCU_LupTrgtEngSpdVal "17.11.00";
BA_ "Description" SG_ 2164277251 TCU_FrtStcShftSta "Status of fisrt static shift";
BA_ "UserSigValidity" SG_ 2164277251 TCU_FrtStcShftSta 3;
BA_ "RoutingFactor" SG_ 2164277251 TCU_FrtStcShftSta 5;
BA_ "Version" SG_ 2164277251 TCU_FrtStcShftSta "17.11.00";
BA_ "Description" SG_ 2164277251 TCU_IsgInhbtReq "TCU requests ECU to inhibit the ISG function when ISG start condition of AT is not met (oil temp is too low , AT ISG system malfunction, etc … )";
BA_ "UserSigValidity" SG_ 2164277251 TCU_IsgInhbtReq 3;
BA_ "RoutingFactor" SG_ 2164277251 TCU_IsgInhbtReq 5;
BA_ "Version" SG_ 2164277251 TCU_IsgInhbtReq "17.11.00";
BA_ "Description" SG_ 2164277251 TCU_CdaInhbtReq "TCU requests ECU to prohibit the CDA transition during gear shifting or lock-up clutch operation in the automatic transmission in order to prevent a shock on the vehicle. Without gear shifting and lock-up clutch operation, CDA transition can be performed.";
BA_ "UserSigValidity" SG_ 2164277251 TCU_CdaInhbtReq 3;
BA_ "RoutingFactor" SG_ 2164277251 TCU_CdaInhbtReq 5;
BA_ "Version" SG_ 2164277251 TCU_CdaInhbtReq "17.11.00";
BA_ "Description" SG_ 2164277251 TCU_BrkOnReq "The TCU request the ESC to activate the Brake.

The ESC holds the Brake ON during the TCU’s Brake ON Request.";
BA_ "UserSigValidity" SG_ 2164277251 TCU_BrkOnReq 3;
BA_ "RoutingFactor" SG_ 2164277251 TCU_BrkOnReq 5;
BA_ "Version" SG_ 2164277251 TCU_BrkOnReq "17.11.00";
BA_ "Description" SG_ 2164277251 TCU_TqGrdntLimVal "TCU requests EMS to perform the engine torque gradient limitation control with a rate of Nm per second(Nm/sec).



Downshift : The engine torque gradient limitation for downshift will be a function of pedal and shift-time. 

Upshift : The engine torque gradient limitation for upshift will be a function of shift-time.";
BA_ "UserSigValidity" SG_ 2164277251 TCU_TqGrdntLimVal 3;
BA_ "RoutingFactor" SG_ 2164277251 TCU_TqGrdntLimVal 5;
BA_ "Version" SG_ 2164277251 TCU_TqGrdntLimVal "17.11.00";
VAL_ 2239848449 FCA_OnOffEquipSta 0 "Default" 1 "Off" 2 "Warning" 3 "Assist" 4 "Reserved" 5 "Reserved" 6 "Reserved" 7 "Invalid" ;
VAL_ 2239848449 FCA_SysFlrSta 0 "Normal" 1 "Temp. Unavailable by Front View Camera (Sensor fusion)" 2 "Temp. Unavailable by Front Radar (Radar only or Sensor fusion in Radar)" 3 "Service Required" 4 "Temp. Unavailable by Front View Camera (Camera only)" 5 "Temp. Unavailable by Front View Camera (Sensor fusion in ADAS_DRV)" 6 "Temp. Unavailable by Front Radar (Sensor fusion in Camera)" 7 "Reserved" ;
VAL_ 2239848449 FCA_WrngLvlSta 0 "No warning" 1 "Warning level 1" 2 "Warning level 2" 3 "Warning level 3" ;
VAL_ 2239848449 FCA_VehStpReq 0 "No request" 1 "Stop control is required" 2 "Reserved" 3 "Error Indicator" ;
VAL_ 2239848449 FCA_StbltActvReq 0 "Release No alert" 1 "Pre-crash full retraction" 2 "Haptic warning" 3 "Reserved" 4 "Reserved" 5 "Reserved" 6 "Reserved" 7 "Reserved" ;
VAL_ 2239848449 FCA_HydrlcBstAsstReq 0 "Standard threshold" 1 "Lowered threshold 1" 2 "Lowered threshold 2" 3 "Lowered threshold 3" ;
VAL_ 2239848449 FCA_PrefillActvReq 0 "No pre-fill" 1 "Pre-fill act" 2 "Reserved" 3 "Error Indicator" ;
VAL_ 2239848449 FCA_PartialActvReq 0 "No Partial act" 1 "Partail act" 2 "Reserved" 3 "Error Indicator" ;
VAL_ 2239848449 FCA_FullActvReq 0 "No Full act" 1 "Full act" 2 "Reserved" 3 "Error Indicator" ;
VAL_ 2239848449 FCA_SnstvtyModRetVal 0 "Default" 1 "Late" 2 "Normal" 3 "Early" 4 "Reserved" 5 "Reserved" 6 "Reserved" 7 "Invalid" ;
VAL_ 2239848449 FCA_WrngSndSta 0 "No warning" 1 "Warning 1" 2 "Warning 2" 3 "Warning 3" 4 "Reserved" 5 "Reserved" 6 "Reserved" 7 "Error indicator" ;
VAL_ 2239848450 FCA_RelVel 511 "Signal Invalid" ;
VAL_ 2239848450 FCA_Jnctn_OnOffEquipSta 0 "Default" 1 "Off" 2 "On" 3 "Invalid" ;
VAL_ 2239848450 HDP_EMOpSta 0 "Off" 1 "On (Not Active)" 2 "On (Active)" 3 "Reserved" 4 "Reserved" 5 "Reserved" 6 "Reserved" 7 "Error indicator" ;
VAL_ 2239848450 FCA_WrngTrgtDis 0 "None" 1 "FCA-Pedestrian" 2 "Reserved" 3 "FCA-Cyclist" 4 "Reserved" 5 "FCA-Car" 6 "Reserved" 7 "FCA-JC (L)" 8 "FCA-JC (R)" 9 "Reserved" 10 "Reserved" 11 "FCA-JT (L)" 12 "FCA-JT (R)" 13 "Reserved" 14 "Reserved" ;
VAL_ 2239848450 ADAS_DRV_FCA_Plus_Sta 0 "FCA-Car/Ped/Cyc+ 상황 미해당" 1 "FCA-Car/Ped/Cyc+ 상황 해당" 2 "Not Used" 3 "Error Indicator" ;
VAL_ 2239848450 EM_WrngLvlSta 0 "No warning" 1 "Prefill (Warning level1)" 2 "Partial brake (Warning level2)" 3 "Full brake (Warning level3)" 4 "Reserved" 5 "Reserved" 6 "Reserved" 7 "Error indicator" ;
VAL_ 2239848450 BrkDelVLimReq 0 "Delta V limit required (Release brake control over ΔV 50km/h)" 1 "Delta V limit not required w/ additional signal (Not release brake control)" 2 "Delta V limit not required w/o additional signal (Not release brake control)" 3 "Reserved" 4 "Reserved" 5 "Reserved" 6 "Reserved" 7 "Error indicator" ;
VAL_ 2256644609 CLU_DtntOutSta 0 "Detent Off" 1 "Detent On" 2 "Not used" 3 "Error Indicator" ;
VAL_ 2256644609 CLU_SpdUnitTyp 0 "km/h" 1 "MPH" 2 "Not used" 3 "Error Indicator" ;
VAL_ 2256644609 CLU_DisSpdDcmlVal 0 "0" 1 "0.125" 2 "0.250" 3 "0.375" ;
VAL_ 2256644609 CLU_RhstaLvlSta 0 "Reserved" 1 "Step 1" 2 "Step 2" 3 "Step 3" 4 "Step 4" 5 "Step 5" 6 "Step 6" 7 "Step 7" 8 "Step 8" 9 "Step 9" 10 "Step 10" 11 "Step 11" 12 "Step 12" 13 "Step 13" 14 "Step 14" 15 "Step 15" 16 "Step 16" 17 "Step 17" 18 "Step 18" 19 "Step 19" 20 "Step 20 (Reset Value)" 21 "Step 21 (Detent)" ;
VAL_ 2256644609 CLU_DisSpdVal 1023 "Error" ;
VAL_ 2256644610 CLU_DisSpdVal_KPH 511 "Error" ;
VAL_ 2256644610 CLU_CUSTOMSta_NEW 0 "Default" 1 "MY DRIVE MODE(CUSTOM)" 2 "SMART(CUSTOM)" 3 "BABY(CUSTOM)" 4 "RETRO(CUSTOM)" 5 "SNOW(CUSTOM)-Not Terrain" 6 "COMFORT(REAR)(CUSTOM)" 7 "" 8 "" 9 "" 10 "" 11 "" 12 "" 13 "" 14 "Off(CUSTOM)" 15 "Invalid" ;
VAL_ 2256644610 CLU_AutoBrightSta 0 "Reserved (Not Used)" 1 "0x01~0xC8:Bright State (1~200 Step)" 200 "0x01~0xC8:Bright State (1~200 Step)" ;
VAL_ 2395189249 DATC_SmrtVntOnOffSta 0 "Fuction Off" 1 "Function On" 2 "Not Used" 3 "Error Indicator" ;
VAL_ 2395189249 DATC_PsAutoDis 0 "AUTO Off" 1 "AUTO On" 2 "Not used" 3 "Error Indicator" ;
VAL_ 2395189249 DATC_RrAutoDis 0 "AUTO Off" 1 "AUTO On" 2 "Not used" 3 "Error Indicator" ;
VAL_ 2395189249 DATC_RrDrvModDis 0 "Off(Blank Display, 토출모드 미표시 예) Auto 시)" 1 "VENT" 2 "B_L" 3 "FLOOR" 4 "MIX (7 MODE DEF FLOOR)" 5 "DEF (MAX DEF)" 6 "AUTO DEFOG" 7 "7 MODE DEF VENT" 8 "MODE AUTO" 9 "7 MODE DEF VENT FLOOR" 10 "7 MODE DEF" 11 "DEF VENT (Arrow)" 12 "DEF FLOOR (Arrow)" 13 "DEF VENT FLOOR (Arrow)" 14 "DEF (Arrow)" 15 "Error Indicator" ;
VAL_ 2395189249 DATC_DisplayThemes 0 "Default" 1 "White Theme" 2 "Black Theme" 3 "Invalid" ;
VAL_ 2395189249 DATC_AUTOStepPS 0 "Default" 1 "OFF" 2 "1st & 2nd & 3rd On (3 Step Type)" 3 "1st & 2nd On (3 Step Type)" 4 "1st On (3 Step Type)" 5 "1st & 2nd On (2 Step Type)" 6 "1st On (2 Step Type)" 7 "Error Indicator" ;
VAL_ 2395189249 DATC_AUTOStepRR 0 "Default" 1 "OFF" 2 "1st & 2nd & 3rd On (3 Step Type)" 3 "1st & 2nd On (3 Step Type)" 4 "1st On (3 Step Type)" 5 "1st & 2nd On (2 Step Type)" 6 "1st On (2 Step Type)" 7 "Error Indicator" ;
VAL_ 2378398721 DATC_FragStrhUSMSta 0 "Default" 1 "Off" 2 "Low" 3 "Medium" 4 "High" 5 "Reserved" 6 "Reserved" 7 "Error Indicator" ;
VAL_ 2378398721 DATC_FragKindUSMSta 0 "Default" 1 "First" 2 "Second" 3 "Reserved" 4 "Reserved" 5 "Reserved" 6 "None" 7 "Error Indicator" ;
VAL_ 2378398721 DATC_Frag1ExpireDisp 0 "Default" 1 "Normal" 2 "Expired" 3 "Error Indicator" ;
VAL_ 2378398721 DATC_FragStrhDis 0 "Default" 1 "Off" 2 "Low" 3 "Medium" 4 "High" 5 "Reserved" 6 "Reserved" 7 "Error Indicator" ;
VAL_ 2378398721 DATC_FragKindDis 0 "Default" 1 "First" 2 "Second" 3 "Reserved" 4 "Reserved" 5 "Reserved" 6 "None" 7 "Error Indicator" ;
VAL_ 2378398721 DATC_Frag2ExpireDisp 0 "Default" 1 "Normal" 2 "Expired" 3 "Error Indicator" ;
VAL_ 2378398721 DATC_VitalityFragranceSta 0 "Default" 1 "Off" 2 "On" 3 "Error Indicator" ;
VAL_ 2378398721 DATC_DelightFragranceSta 0 "Default" 1 "Off" 2 "On" 3 "Error Indicator" ;
VAL_ 2378398721 DATC_CareFragranceSta 0 "Default" 1 "Off" 2 "On" 3 "Error Indicator" ;
VAL_ 2378398721 DATC_ComfortFragranceSta 0 "Default" 1 "Off" 2 "On" 3 "Error Indicator" ;
VAL_ 2378398721 DATC_Frag1Inform 0 "Default" 1 "THE DRIVER'S AWAKENING" 2 "MY FAVORITE PLACE" 3 "THE GREAT OUTDOORS" 4 "Reserved" 5 "Reserved" 6 "Reserved" 7 "Reserved" 8 "Reserved" 9 "Reserved" 10 "Reserved" 11 "Reserved" 12 "New Fragrance Mounted" 13 "No Cartridge Mounted" 14 "Reserved" 15 "Error Indicator" ;
VAL_ 2378398721 DATC_Frag1RemainDisp 0 "Default" 1 "Remains 100% (70~100%)" 2 "Remains 70% (30~70%)" 3 "Remains 30% (0~30%)" 4 "Remains 0%" 5 "Reserved" 6 "Unknown" 7 "Error Indicator" ;
VAL_ 2378398721 DATC_Frag2Inform 0 "Default" 1 "THE DRIVER'S AWAKENING" 2 "MY FAVORITE PLACE" 3 "THE GREAT OUTDOORS" 4 "Reserved" 5 "Reserved" 6 "Reserved" 7 "Reserved" 8 "Reserved" 9 "Reserved" 10 "Reserved" 11 "Reserved" 12 "New Fragrance Mounted" 13 "No Cartridge Mounted" 14 "Reserved" 15 "Error Indicator" ;
VAL_ 2378398721 DATC_Frag2RemainDisp 0 "Default" 1 "Remains 100% (70~100%)" 2 "Remains 70% (30~70%)" 3 "Remains 30% (0~30%)" 4 "Remains 0%" 5 "Reserved" 6 "Unknown" 7 "Error Indicator" ;
VAL_ 346 DPSS_AstSldFwdMvBtn 0 "Default" 1 "Off" 2 "On" 3 "Invalid" ;
VAL_ 346 DPSS_AstStSldBwdMvBtn 0 "Default" 1 "Off" 2 "On" 3 "Invalid" ;
VAL_ 346 DPSS_AstStRclFwdMvBtn 0 "Default" 1 "Off" 2 "On" 3 "Invalid" ;
VAL_ 346 DPSS_AstStRclBwdMvBtn 0 "Default" 1 "Off" 2 "On" 3 "Invalid" ;
VAL_ 346 DPSS_AstStHgtUpMvBtn 0 "Default" 1 "Off" 2 "On" 3 "Invalid" ;
VAL_ 346 DPSS_AstStHgtDnMvBtn 0 "Default" 1 "Off" 2 "On" 3 "Invalid" ;
VAL_ 346 DPSS_AstStTltUpMvBtn 0 "Default" 1 "Off" 2 "On" 3 "Invalid" ;
VAL_ 346 DPSS_AstStTltDnMvBtn 0 "Default" 1 "Off" 2 "On" 3 "Invalid" ;
VAL_ 346 DPSS_AstStHRestUpMvBtn 0 "Default" 1 "Off" 2 "On" 3 "Invalid" ;
VAL_ 346 DPSS_AstStHRestDnMvBtn 0 "Default" 1 "Off" 2 "On" 3 "Invalid" ;
VAL_ 346 DPSS_AstStHRestFwdMvBtn 0 "Default" 1 "Off" 2 "On" 3 "Invalid" ;
VAL_ 346 DPSS_AstStHRestBwdMvBtn 0 "Default" 1 "Off" 2 "On" 3 "Invalid" ;
VAL_ 346 DPSS_AstStExtFwdMvBtn 0 "Default" 1 "Off" 2 "On" 3 "Invalid" ;
VAL_ 346 DPSS_AstStExtBwdMvBtn 0 "Default" 1 "Off" 2 "On" 3 "Invalid" ;
VAL_ 346 DPSS_WalkInSwitchSts 0 "Default" 1 "Off" 2 "On" 3 "Invalid" ;
VAL_ 347 DSAU_LumbarUpDis 0 "Default" 1 "Off" 2 "On" 3 "Invalid" ;
VAL_ 347 DSAU_LumbarMidDis 0 "Default" 1 "Off" 2 "On" 3 "Invalid" ;
VAL_ 347 DSAU_LumbarLowDis 0 "Default" 1 "Off" 2 "On" 3 "Invalid" ;
VAL_ 347 DSAU_LumbarDefDis 0 "Default" 1 "Off" 2 "On" 3 "Invalid" ;
VAL_ 348 DSAU_BolsterInfDis 0 "Default" 1 "Off" 2 "On" 3 "Invalid" ;
VAL_ 348 DSAU_BolsterDefDis 0 "Default" 1 "Off" 2 "On" 3 "Invalid" ;
VAL_ 349 DSAU_CushInfDis 0 "Default" 1 "Off" 2 "On" 3 "Invalid" ;
VAL_ 349 DSAU_CushDefDis 0 "Default" 1 "Off" 2 "On" 3 "Invalid" ;
VAL_ 350 DSAU_AirSptTimeRValueSet 0 "Default" 1 "Short" 2 "Normal" 3 "Long" 4 "Reserved" 5 "Reserved" 6 "Reserved" 7 "Reserved" ;
VAL_ 350 DSAU_DrvPostureAssistRValueSet 0 "Default" 1 "Off" 2 "On" 3 "Invalid" ;
VAL_ 350 DSAU_DrvSmtAirSptRValueSet 0 "Default" 1 "Off" 2 "On" 3 "Invalid" ;
VAL_ 350 DSAU_DrvSmtSptRValueSet 0 "Default" 1 "Off" 2 "On" 3 "Invalid" ;
VAL_ 350 DSAU_DrvPostureAssistDis 0 "Default" 1 "Off" 2 "On" 3 "Invalid" ;
VAL_ 350 DSAU_CushSoftRValueSet 0 "Default" 1 "Off" 2 "Soft" 3 "Mid" 4 "Hard" 5 "Reserved" 6 "Reserved" 7 "Reserved" ;
VAL_ 350 DSAU_BackSoftRValueSet 0 "Default" 1 "Off" 2 "Soft" 3 "Mid" 4 "Hard" 5 "Reserved" 6 "Reserved" 7 "Reserved" ;
VAL_ 350 DSAU_AirSptModeRValueSet 0 "Default" 1 "Mode 1" 2 "Mode 2" 3 "Mode 3" 4 "Mode 4" 5 "Mode 5" 6 "Reserved" 7 "Reserved" ;
VAL_ 350 DSAU_MsgModeSts 0 "Default" 1 "Off" 2 "Mode 1" 3 "Mode 2" 4 "Mode 3" 5 "Mode 4" 6 "Mode 5" 7 "Reserved" ;
VAL_ 350 DSAU_MsgModeStrength 0 "Default" 1 "Off" 2 "Low" 3 "Mid" 4 "High" 5 "Reserved" 6 "Reserved" 7 "Reserved" ;
VAL_ 350 DSAU_MoodTrpyRValueSet 0 "Default" 1 "Off" 2 "On" 3 "Invalid" ;
VAL_ 350 DSAU_MoodTrpyCareSta 0 "Default" 1 "Off" 2 "On" 3 "Invalid" ;
VAL_ 350 DSAU_MoodTrpyComfSta 0 "Default" 1 "Off" 2 "On" 3 "Invalid" ;
VAL_ 350 DASU_AirSptStrRValueSet 0 "Default" 1 "Low" 2 "Mid" 3 "High" 4 "Off" 5 "Reserved" 6 "Reserved" 7 "Reserved" ;
VAL_ 2407787009 DVRS_Rec_Crash 0 "OFF" 1 "ON" 2 "Reserved" 3 "invalid" ;
VAL_ 2407787009 DVRS_Rec_Normal_Prk 0 "Off" 1 "On" 2 "Reserved" 3 "Invalid" ;
VAL_ 2407787009 DVRS_Timelapse 0 "Off" 1 "On" 2 "Reserved" 3 "Invalid" ;
VAL_ 2407787009 DVRS_Rec_Manual 0 "OFF" 1 "ON" 2 "Reserved" 3 "invalid" ;
VAL_ 2407787009 DVRS_Prk_time 0 "0x0x00~0xFB:Park operation time" 251 "0x0x00~0xFB:Park operation time" 252 "Not support park record function." 253 "The function is not operationable." 254 "The function is not set." 255 "Invalid" ;
VAL_ 2407787009 DVRS_Rec_Normal 0 "OFF" 1 "ON" 2 "Reserved" 3 "invalid" ;
VAL_ 2407787009 DVRS_Prk_Crash_Event_Count 0 "0x0x00~0xFD:The number of park crash event" 253 "0x0x00~0xFD:The number of park crash event" 254 "Park mode is not executed" 255 "Invalid" ;
VAL_ 2407787009 DVRS_Status 0 "DVRS Valid" 1 "DVRS Front Camera Invalid" 2 "DVRS Rear Camera Invalid" 3 "DVRS Front_Rear Camera Inavlid" 4 "DVRS Record Invalid" 5 "Reserved" 6 "Reserved" 7 "Reserved" 8 "Reserved" 9 "Reserved" 10 "Reserved" 11 "Reserved" 12 "Reserved" 13 "Reserved" 14 "Reserved" 15 "invalid" ;
VAL_ 2407787009 DVRS_Event_Sound 0 "Off" 1 "Crash event" 2 "Switch event" 3 "Invalid" ;
VAL_ 2407787009 DVRS_BeepSound 0 "OFF" 1 "ON" 2 "Keyboard On" 3 "invalid" ;
VAL_ 2407787009 DVRS_Display 0 "AVN mode" 1 "Built-in Cam mode" 2 "popup mode" 3 "Built-in Cam mode Terminate Request by Home-button" 4 "Built-in Cam mode Terminate Request by Back-button" 5 "Built-in Cam update mode" 6 "Ready to update" 7 "Update complete" 8 "USB removed" 9 "Update fail (USB error)" 10 "AVN current mode Request" 11 "Reserved" 12 "Reserved" 13 "Reserved" 14 "Built-in Cam is in error mode" 15 "Invalid" ;
VAL_ 2407787009 BLTN_CAM_UpdateSWType 0 "0ld" 1 "New" 2 "Reserved" 3 "Invalid" ;
VAL_ 2407787009 DVRS_I2CMasterSta 0 "Built-in Cam has control over I2C ch" 1 "ADAS_PRK has control over I2C ch" 2 "Configure Failed" 3 "Invalid" ;
VAL_ 2407787009 DVRS_CamSta 0 "Normal (Camera is working normally)" 1 "Power Issue" 2 "V-sync Issue" 3 "Ser/Des Lock Issue" 4 "Reserved" 5 "Reserved" 6 "Reserved" 7 "Invalid" ;
VAL_ 2407787009 DVRS_RecSet_Normal 0 "Default" 1 "Off" 2 "On" 3 "Invalid" ;
VAL_ 2407787009 DVRS_RecSet_Crash 0 "Default" 1 "Off" 2 "On" 3 "Invalid" ;
VAL_ 2407787009 DVRS_RecSet_Normal_Prk 0 "Default" 1 "Off" 2 "On" 3 "Invalid" ;
VAL_ 2407787009 DVRS_RecSet_Crash_Prk 0 "Default" 1 "Off" 2 "On" 3 "Invalid" ;
VAL_ 2407787009 DVRS_Rec_Crash_Prk 0 "Off" 1 "On" 2 "Reserved" 3 "Invalid" ;
VAL_ 319 FPM_Random 16777215 "Random Number to AVN" ;
VAL_ 2458166529 C_RLUnFldSw_HU 0 "Default" 1 "Off" 2 "On" 3 "Invalid" ;
VAL_ 2458166529 C_RLTiltUpSw_HU 0 "Default" 1 "Off" 2 "On" 3 "Invalid" ;
VAL_ 2458166529 C_RRTiltDownSw_HU 0 "Default" 1 "Off" 2 "On" 3 "Invalid" ;
VAL_ 2458166529 C_RRTiltUpSw_HU 0 "Default" 1 "Off" 2 "On" 3 "Invalid" ;
VAL_ 2458166529 C_RLRclBwdSw_HU 0 "Default" 1 "Off" 2 "On" 3 "Invalid" ;
VAL_ 2458166529 C_RLRclFwdSw_HU 0 "Default" 1 "Off" 2 "On" 3 "Invalid" ;
VAL_ 2458166529 C_RLFldSw_HU 0 "Default" 1 "Off" 2 "On" 3 "Invalid" ;
VAL_ 2458166529 C_RRRclBwdSw_HU 0 "Default" 1 "Off" 2 "On" 3 "Invalid" ;
VAL_ 2458166529 C_RRRclFwdSw_HU 0 "Default" 1 "Off" 2 "On" 3 "Invalid" ;
VAL_ 2458166529 C_TLHrestFldSw_HU 0 "Default" 1 "Off" 2 "On" 3 "Invalid" ;
VAL_ 2458166529 C_TRHrestFldSw_HU 0 "default" 1 "OFF" 2 "ON" 3 "Invalid" ;
VAL_ 2458166529 C_RLRlxSW_HU 0 "Default" 1 "Off" 2 "On" 3 "Invalid" ;
VAL_ 2458166529 C_RRRlxSW_HU 0 "Default" 1 "Off" 2 "On" 3 "Invalid" ;
VAL_ 2458166529 C_RRUnWalkInSw_HU 0 "Default" 1 "Off" 2 "On" 3 "Invalid" ;
VAL_ 2458166529 C_RRWalkInSw_HU 0 "Default" 1 "Off" 2 "On" 3 "Invalid" ;
VAL_ 2458166529 C_TLFldSw_HU 0 "Default" 1 "Off" 2 "On" 3 "Invalid" ;
VAL_ 2458166529 C_TRFldSw_HU 0 "Default" 1 "Off" 2 "On" 3 "Invalid" ;
VAL_ 2458166529 C_RRUnFldSw_HU 0 "Default" 1 "Off" 2 "On" 3 "Invalid" ;
VAL_ 2458166529 C_RLUnWalkInSw_HU 0 "Default" 1 "Off" 2 "On" 3 "Invalid" ;
VAL_ 2458166529 C_RLWalkInSw_HU 0 "Default" 1 "Off" 2 "On" 3 "Invalid" ;
VAL_ 2458166529 C_TRRclBwdSw_HU 0 "Default" 1 "Off" 2 "On" 3 "Invalid" ;
VAL_ 2458166529 C_TRRclFwdSw_HU 0 "Default" 1 "Off" 2 "On" 3 "Invalid" ;
VAL_ 2458166529 C_RRFldSw_HU 0 "Default" 1 "Off" 2 "On" 3 "Invalid" ;
VAL_ 2458166529 C_TLRclBwdSw_HU 0 "Default" 1 "Off" 2 "On" 3 "Invalid" ;
VAL_ 2458166529 C_TLRclFwdSw_HU 0 "Default" 1 "Off" 2 "On" 3 "Invalid" ;
VAL_ 2458166529 C_RLTiltDownSw_HU 0 "Default" 1 "Off" 2 "On" 3 "Invalid" ;
VAL_ 2462364673 POS_V2_3_Offset 0 "0x0x0~0x1FFE:Distance" 8190 "0x0x0~0x1FFE:Distance" 8191 "Invalid" ;
VAL_ 2462364673 POS_V2_3_PathIndex 0 "Unknown" 1 "Reserved" 2 "Reserved" 3 "Reserved" 4 "Reserved" 5 "Reserved" 6 "Reserved" 7 "Reserved" 31 "Invalid" 8 "General Path Index" 9 "General Path Index" 10 "General Path Index" 11 "General Path Index" 12 "General Path Index" 13 "General Path Index" 14 "General Path Index" 15 "General Path Index" 16 "General Path Index" 17 "General Path Index" 18 "General Path Index" 19 "General Path Index" 20 "General Path Index" 21 "General Path Index" 22 "General Path Index" 23 "General Path Index" 24 "General Path Index" 25 "General Path Index" 26 "General Path Index" 27 "General Path Index" 28 "General Path Index" 29 "General Path Index" 30 "General Path Index" ;
VAL_ 2462364673 POS_V2_3_CyclicCounter 0 "Cyclic Counter" 1 "Cyclic Counter" 2 "Cyclic Counter" 3 "Cyclic Counter" 4 "Reserved" 5 "Reserved" 6 "Reserved" 7 "Invalid" ;
VAL_ 2462364673 POS_V2_3_RangeAvgSpeed 0 "0x0x0~0xFD:Range Camera Average Speed" 253 "0x0x0~0xFD:Range Camera Average Speed" 254 "0xFE~0x1FD:Reserved" 509 "0xFE~0x1FD:Reserved" 510 "unknown" 511 "Invalid" ;
VAL_ 2462364673 POS_V2_3_CurrAltitude100m 0 "Unknown" 1 "Under100m" 16 "1500m" 17 "1600m" 18 "1700m" 19 "1800m" 20 "1900m" 21 "2000m" 22 "2100m" 23 "2200m" 24 "2300m" 25 "2400m" 26 "2500m" 27 "2600m" 28 "2700m" 29 "2800m" 30 "2900m" 31 "3000m" 2 "100m" 32 "3100m" 33 "3200m" 34 "3300m" 35 "3400m" 36 "3500m" 37 "3600m" 38 "3700m" 39 "3800m" 40 "3900m" 41 "4000m" 42 "4100m" 43 "4200m" 44 "4300m" 45 "4400m" 46 "4500m" 47 "4600m" 3 "200m" 48 "4700m" 49 "4800m" 50 "4900m" 51 "5000m" 52 "5100m" 53 "5200m" 54 "5300m" 55 "5400m" 56 "5500m" 57 "5600m" 58 "5700m" 59 "5800m" 60 "5900m" 61 "6000m" 62 "Over6,000m" 63 "Invalid" 4 "300m" 5 "400m" 6 "500m" 7 "600m" 8 "700m" 9 "800m" 10 "900m" 11 "1000m" 12 "1100m" 13 "1200m" 14 "1300m" 15 "1400m" ;
VAL_ 2462364673 POS_V2_3_CurrAltitude1m 0 "Unknown" 1 "Under1m" 16 "15m" 17 "16m" 18 "17m" 19 "18m" 20 "19m" 21 "20m" 22 "21m" 23 "22m" 24 "23m" 25 "24m" 26 "25m" 27 "26m" 28 "27m" 29 "28m" 30 "29m" 31 "30m" 2 "1m" 32 "31m" 33 "32m" 34 "33m" 35 "34m" 36 "35m" 37 "36m" 38 "37m" 39 "38m" 40 "39m" 41 "40m" 42 "41m" 43 "42m" 44 "43m" 45 "44m" 46 "45m" 47 "46m" 3 "2m" 48 "47m" 49 "48m" 50 "49m" 51 "50m" 52 "51m" 53 "52m" 54 "53m" 55 "54m" 56 "55m" 57 "56m" 58 "57m" 59 "58m" 60 "59m" 61 "60m" 62 "61m" 63 "62m" 4 "3m" 64 "63m" 65 "64m" 66 "65m" 67 "66m" 68 "67m" 69 "68m" 70 "69m" 71 "70m" 72 "71m" 73 "72m" 74 "73m" 75 "74m" 76 "75m" 77 "76m" 78 "77m" 79 "78m" 5 "4m" 80 "79m" 81 "80m" 82 "81m" 83 "82m" 84 "83m" 85 "84m" 86 "85m" 87 "86m" 88 "87m" 89 "88m" 90 "89m" 91 "90m" 92 "91m" 93 "92m" 94 "93m" 95 "94m" 6 "5m" 96 "95m" 97 "96m" 98 "97m" 99 "98m" 100 "99m" 101 "Reserved" 102 "Reserved" 103 "Reserved" 104 "Reserved" 105 "Reserved" 106 "Reserved" 107 "Reserved" 108 "Reserved" 109 "Reserved" 110 "Reserved" 111 "Reserved" 112 "Reserved" 113 "Reserved" 114 "Reserved" 115 "Reserved" 116 "Reserved" 117 "Reserved" 118 "Reserved" 119 "Reserved" 120 "Reserved" 121 "Reserved" 122 "Reserved" 123 "Reserved" 124 "Reserved" 125 "Reserved" 126 "Reserved" 7 "6m" 127 "Invalid" 8 "7m" 9 "8m" 10 "9m" 11 "10m" 12 "11m" 13 "12m" 14 "13m" 15 "14m" ;
VAL_ 2462364673 POS_V2_3_CurrFuncRoadClass 0 "Unknown" 1 "Freeway" 2 "Arterial(Cityfreeway)" 3 "County" 4 "Collector" 5 "Local" 6 "Etc(ferry, unpaved)" 7 "Invalid" ;
VAL_ 2462364673 POS_V2_3_CurrFormOfWay 0 "Unknown" 1 "Main road(nondisjunction)" 2 "Main road(disjunction)" 3 "JC" 4 "Plural Junction M" 5 "IC" 6 "Reserved" 7 "Service Area" 8 "Reserved" 9 "Roundabout" 10 "P turn" 11 "U turn" 12 "Pedestrian" 13 "Frontage Road" 14 "Intersection internal(Plural Junction)" 15 "Invalid" ;
VAL_ 2462364673 POS_V2_3_CurrDirectionLanes 0 "Unknown" 1 "Lane count" 2 "Lane count" 3 "Lane count" 4 "Lane count" 5 "Lane count" 6 "Lane count" 7 "Lane count" 8 "Lane count" 9 "Lane count" 10 "Lane count" 11 "Lane count" 12 "Lane count" 13 "Lane count" 14 "Lane count" 15 "Invalid" ;
VAL_ 2462364673 POS_V2_3_CurrSpeedLimit 0 "Unknown" 1 "Under 5kph(mph)" 16 "75kph(mph)" 17 "80kph(mph)" 18 "85kph(mph)" 19 "90kph(mph)" 20 "95kph(mph)" 21 "100kph(mph)" 22 "105kph(mph)" 23 "110kph(mph)" 24 "115kph(mph)" 25 "120kph(mph)" 26 "130kph(mph)" 27 "140kph(mph)" 28 "150kph(mph)" 29 "160kph(mph)" 30 "Unlimited" 31 "Invalid" 2 "7kph(mph)" 3 "10kph(mph)" 4 "15kph(mph)" 5 "20kph(mph)" 6 "25kph(mph)" 7 "30kph(mph)" 8 "35kph(mph)" 9 "40kph(mph)" 10 "45kph(mph)" 11 "50kph(mph)" 12 "55kph(mph)" 13 "60kph(mph)" 14 "65kph(mph)" 15 "70kph(mph)" ;
VAL_ 2462364673 POS_V2_3_CurrTrafficSpeed 0 "Unknown" 1 "Under 5kph(mph)" 16 "75kph(mph)" 17 "80kph(mph)" 18 "85kph(mph)" 19 "90kph(mph)" 20 "95kph(mph)" 21 "100kph(mph)" 22 "105kph(mph)" 23 "110kph(mph)" 24 "115kph(mph)" 25 "120kph(mph)" 26 "130kph(mph)" 27 "140kph(mph)" 28 "150kph(mph)" 29 "160kph(mph)" 30 "Over160kph(mph)" 31 "Invalid" 2 "7kph(mph)" 3 "10kph(mph)" 4 "15kph(mph)" 5 "20kph(mph)" 6 "25kph(mph)" 7 "30kph(mph)" 8 "35kph(mph)" 9 "40kph(mph)" 10 "45kph(mph)" 11 "50kph(mph)" 12 "55kph(mph)" 13 "60kph(mph)" 14 "65kph(mph)" 15 "70kph(mph)" ;
VAL_ 2466562561 C_RH_Unfolding_SW 0 "Default" 1 "OFF" 2 "ON" 3 "Invalid" ;
VAL_ 2466562561 C_PSMHeightNValueSet 0 "Default" 1 "Off" 2 "On" 3 "Reserved" 4 "Reserved" 5 "Reserved" 7 "Invalid" ;
VAL_ 2466562561 C_AVN_PTGHeightNValueSet 0 "Default" 1 "Level 1" 2 "Level 2" 3 "Level 3" 4 "Level 4" 5 "Reserved" 6 "User Setting" 7 "Invalid" ;
VAL_ 2466562561 CF_AVN_SCCMLReset 0 "Default" 1 "Reset" 2 "Reserved" 3 "Invalid" ;
VAL_ 2466562561 C_TgltAwayCloseNValue 0 "Default" 1 "Off" 2 "On" 3 "Invalid" ;
VAL_ 2466562561 C_RH_Folding_SW 0 "Default" 1 "OFF" 2 "ON" 3 "Invalid" ;
VAL_ 2466562561 C_HAnBNValueSet 0 "Default" 1 "Arm Disarm Buzzer Off" 2 "Arm Disarm Buzzer On" 3 "Invalid" ;
VAL_ 2466562561 CF_AVN_RrSeatRemindNValueSet 0 "Default" 1 "Off  (Disable)" 2 "On (Enable)" 3 "Invalid" ;
VAL_ 2466562561 CF_AVN_DSWNValueSet 0 "Default" 1 "Off" 2 "On" 3 "Invalid" ;
VAL_ 2466562561 CF_AVN_RRPSU_RLNValueSet 0 "Default" 1 "Off (Disable)" 2 "On (Enable)" 3 "Reserved" 4 "Reserved" 5 "Reserved" 6 "Reserved" 7 "Invalid" ;
VAL_ 2466562561 CF_AVN_APSUNValueSet 0 "Default" 1 "Off (Disable)" 2 "50mm On (Enable)" 3 "75mm On (Enable)" 4 "Reserved" 5 "Reserved" 6 "Reserved" 7 "Invalid" ;
VAL_ 2466562561 CF_AVN_NCC_CameraNValueSet 0 "Default" 1 "Function Off" 2 "Manual Resume (Function On)" 3 "Automatic Resume (Function On)" 4 "Reserved" 5 "Reserved" 6 "Reserved" 7 "Invalid" ;
VAL_ 2466562561 CF_AVN_FCAJnctnNValueSet 0 "Default" 1 "Off" 2 "On" 3 "Invalid" ;
VAL_ 2466562561 CF_AVN_RRPSU_RRNValueSet 0 "Default" 1 "Off (Disable)" 2 "On (Enable)" 3 "Reserved" 4 "Reserved" 5 "Reserved" 6 "Reserved" 7 "Invalid" ;
VAL_ 2466562561 C_LH_Unfolding_SW 0 "Default" 1 "OFF" 2 "ON" 3 "Invalid" ;
VAL_ 2466562561 CF_AVN_HtBlcAstNValueSet 0 "Default" 1 "Normal" 2 "Back 1" 3 "Back 2" 4 "Back 3" 5 "Cush 1" 6 "Cush 2" 7 "Cush 3" 8 "Reserved" 9 "Reserved" 10 "Reserved" 11 "Reserved" 12 "Reserved" 13 "Reserved" 14 "Reserved" 15 "Invalid" ;
VAL_ 2466562561 CF_AVN_HtBlcDrvNValueSet 0 "Default" 1 "Normal" 2 "Back 1" 3 "Back 2" 4 "Back 3" 5 "Cush 1" 6 "Cush 2" 7 "Cush 3" 8 "Reserved" 9 "Reserved" 10 "Reserved" 11 "Reserved" 12 "Reserved" 13 "Reserved" 14 "Reserved" 15 "Invalid" ;
VAL_ 2466562561 CF_AVN_SCCModeNValueSet 0 "Not applied" 1 "Drive mode" 2 "SCC-ML" 3 "Invalid" ;
VAL_ 2466562561 CF_AVN_SCCMLChar1Set 0 "None" 1 "Level 1(Weak)" 2 "Level 2" 3 "Level 3" 4 "Level 4" 5 "Level 5(Strong)" 6 "Reserved" 7 "Invalid" ;
VAL_ 2466562561 CF_AVN_UIPNValueSet 0 "Default" 1 "Off (Disable)" 2 "On (Enable)" 3 "Invalid" ;
VAL_ 2466562561 CF_AVN_SCCMLChar2Set 0 "None" 1 "Level 1(Short)" 2 "Level 2" 3 "Level 3" 4 "Level 4" 5 "Reserved" 6 "Reserved" 7 "Invalid" ;
VAL_ 2466562561 CF_AVN_SCCMLChar3Set 0 "None" 1 "Level 1(Slow)" 2 "Level 2" 3 "Level 3" 4 "Level 4" 5 "Level 5(Fast)" 6 "Reserved" 7 "Invalid" ;
VAL_ 2466562561 C_LH_Folding_SW 0 "Default" 1 "OFF" 2 "ON" 3 "Invalid" ;
VAL_ 2466562561 CF_AVN_NmodeFCAoffNValue 0 "Default" 1 "Disable" 2 "Enable" 3 "Invalid" ;
VAL_ 2466562561 CF_AVN_HDALCFuncNValueSet 0 "Default" 1 "Off" 2 "On" 3 "Invalid" ;
VAL_ 799 DRV_CrashUnlockCmd 0 "Off" 1 "Unlock(Crash)" ;
VAL_ 799 C_ApprOpenStatus 0 "Approach Open Off" 1 "Approach Open On" ;
VAL_ 799 Warn_DrvDrSwSta_SBCM 0 "Close" 1 "Open" 2 "Not Used" 3 "Error Indicator" ;
VAL_ 799 DoorLock_DrvDrUnLkSta_SBCM 0 "Lock" 1 "Unlock" 2 "Not Used" 3 "Error Indicator" ;
VAL_ 799 DRV_SEAWarn_LH 0 "SEA Left Warning OFF" 1 "SEA Left Warning ON" 2 "Reserved" 3 "Invalid" ;
VAL_ 799 DRV_SEAWarn_RH 0 "SEA Right Warning OFF" 1 "SEA Right  Warning ON" 2 "Reserved" 3 "Invalid" ;
VAL_ 799 DRV_SEWWarn_LH 0 "SEW Left Warning OFF" 1 "SEW Left Warning ON" 2 "Reserved" 3 "Invalid" ;
VAL_ 799 DRV_SEWWarn_RH 0 "SEW Right Warning OFF" 1 "SEW Right Warning ON" 2 "Reserved" 3 "Invalid" ;
VAL_ 799 DRV_MRActivationAlarm 0 "Off" 1 "On" 2 "Not Used" 3 "Error Indicator" ;
VAL_ 799 DRV_ReleaseWarn 0 "Release Warning OFF" 1 "Release Warning ON" 2 "Reserved" 3 "Invalid" ;
VAL_ 799 Latch_TypeOption_DRV 0 "Off" 1 "On" 2 "Not Used" 3 "Error Indicator" ;
VAL_ 799 DRV_SWFailAlarm 0 "Off" 1 "On" 2 "Not Used" 3 "Error Indicator" ;
VAL_ 799 USM_PwrDRCloseByRKELockSta 0 "Default" 1 "Off" 2 "On" 3 "Invalid" ;
VAL_ 799 USM_PwrDRCloseByRKELockOpt 0 "Default" 1 "Off" 2 "On" 3 "Invalid" ;
VAL_ 799 USM_PwrDRCloseByBrakeSta 0 "Default" 1 "Off" 2 "On" 3 "Invalid" ;
VAL_ 799 USM_PwrDRCloseByBrakeOpt 0 "Default" 1 "Off" 2 "On" 3 "Invalid" ;
VAL_ 799 USM_PwrDRBuzzerSta 0 "Default" 1 "Off" 2 "On" 3 "Invalid" ;
VAL_ 799 USM_PwrDRBuzzerOpt 0 "Default" 1 "Off" 2 "On" 3 "Invalid" ;
VAL_ 799 PDS_TypeOption_DRV 0 "Off" 1 "On" 2 "Not Used" 3 "Error Indicator" ;
VAL_ 799 C_DrvDoorApproachOpen 0 "Default" 1 "Approach Open Request" 2 "Approach Open Stop" 3 "Not Used" ;
VAL_ 799 C_DrvDoorApproachClose 0 "Default" 1 "Approach Close Request" 2 "Approach Close Stop" 3 "Not Used" ;
VAL_ 799 DoorLock_PDSLkSwSta_DRV 0 "Default" 1 "Lock" 2 "Not Used" 3 "Error Indicator" ;
VAL_ 799 DRVDoorPushAlarm 0 "Off" 1 "On" 2 "Not Used" 3 "Error Indicator" ;
VAL_ 2164277250 TCU_CurrGearSta 0 "if N or P are detected (no frictional connection)" 1 "1st speed" 2 "2nd speed" 3 "3rd speed" 4 "4th speed" 5 "5th speed" 6 "6th speed" 7 "7th speed" 8 "8th speed" 14 "Reverse speed" ;
VAL_ 2164277250 TCH_EngTrgtGearSta 0 "if N or P are detected (no frictional connection)" 1 "1st speed" 2 "2nd speed" 3 "3rd speed" 4 "4th speed" 5 "5th speed" 6 "6th speed" 7 "7th speed" 8 "8th speed" 14 "Reverse speed" ;
VAL_ 2164277250 TCU_EngTqLimVal 0 "Max. reduction" 2047 "No reduction" ;
VAL_ 2164277250 TCU_VehSpdKphVal 255 "Error Indicator" ;
VAL_ 2164277250 TCU_TrgtGearSta 0 "if N or P are detected (no frictional connection)" 1 "1st speed" 2 "2nd speed" 3 "3rd speed" 4 "4th speed" 5 "5th speed" 6 "6th speed" 7 "7th speed" 8 "8th speed" 14 "Reverse speed" ;
VAL_ 2164277250 TCU_DcmlVehSpdKphVal 0 "Error Indicator" ;
VAL_ 2164277250 TCU_GearLmpBlnkngReq 0 "No blink" 1 "Request lamp blinking" 2 "Not used" 3 "Error Indicator" ;
VAL_ 2164277250 TCU_FuelCutInhbtReq 0 "No request" 1 "Fuel cut inhibition request from TCU" 2 "Not used" 3 "Error Indicator" ;
VAL_ 2164277250 TCU_IdleUpReq 0 "No IDLE UP request" 1 "IDLE UP request" 2 "Not used" 3 "Error Indicator" ;
VAL_ 2164277250 TCU_CluTrgtGearSta 0 "if N or P are detected (no frictional connection)" 1 "1st speed" 2 "2nd speed" 3 "3rd speed" 4 "4th speed" 5 "5th speed" 6 "6th speed" 7 "7th speed" 8 "8th speed" 14 "Reverse speed" ;
VAL_ 2164277251 TCU_EngRpmDis 65535 "Error Indicator" ;
VAL_ 2164277251 TCU_EngSpdIncReq 0 "No request" 1 "Engine speed increase is requested" 2 "Not used" 3 "Error Indicator" ;
VAL_ 2164277251 TCU_ObdSta 2 "Failure information of TCU" 3 "Failure information of TCU" 4 "MIL on request" 5 "MIL on request" 6 "Failure information of TCU & MIL on request" 7 "Failure information of TCU & MIL on request" ;
VAL_ 2164277251 TCU_SprtyIndxSta 0 "Invalid" 1 "Step 1" 2 "Step 2" 3 "Step 3" 4 "Step 4" 5 "Step 5" 6 "Step 6" 7 "Step 7" 8 "Step 8" 9 "Step 9" 10 "Step 10" 11 "Step 11" 12 "Step 12" 13 "Step 13" 14 "Step 14" 15 "Step 15" 16 "Step 16" 17 "Step 17" 18 "Step 18" 19 "Step 19" 20 "Step 20" 21 "Step 21" 22 "Step 22" 23 "Step 23" 24 "Step 24" 25 "Step 25" 26 "Invalid" 27 "Invalid" 28 "Invalid" 29 "Invalid" 30 "Invalid" 31 "Invalid" ;
VAL_ 2164277251 TCU_DrvngModDis 0 "Inactive" 1 "Normal" 2 "Eco" 3 "Eco+" 4 "Sport" 5 "Sport+" 6 "Snow" 7 "Reserved" ;
VAL_ 2164277251 TCU_DrvngModReq 0 "Inactive" 1 "Normal" 2 "Eco" 3 "Eco+" 4 "Sport" 5 "Sport+" 6 "Snow" 7 "Reserved" ;
VAL_ 2164277251 TCU_SmrtShftSta 0 "Smart Shift not Applied" 1 "Smart Shift Applied" 2 "Not used" 3 "Error Indicator" ;
VAL_ 2164277251 TCU_FrtStcShftSta 0 "First static shift function is not activated." 1 "First static shift function is activated" 2 "Not used" 3 "Error Indicator" ;
VAL_ 2164277251 TCU_IsgInhbtReq 0 "TCU inhibits the ISG function" 1 "ISG is available" 2 "Not used" 3 "Error Indicator" ;
VAL_ 2164277251 TCU_CdaInhbtReq 0 "CDA transition is available" 1 "TCU prohibits CDA transition" 2 "Not used" 3 "Error Indicator" ;
VAL_ 2164277251 TCU_BrkOnReq 0 "No request" 1 "Brake On Request" 2 "Not used" 3 "Error Indicator" ;
VAL_ 2164277251 TCU_TqGrdntLimVal 255 "No torque gradient limitation" ;
